VERSION ""

NS_ :

BS_:

BU_: AHLM ASBS CBC DIAGNOST DPDM DTCM ECM EHPS ESC ESL ESM ETM GPF HCP IC IRCM OCM ORC PTS RF_HUB SCCM SGW TBM TCM TPM

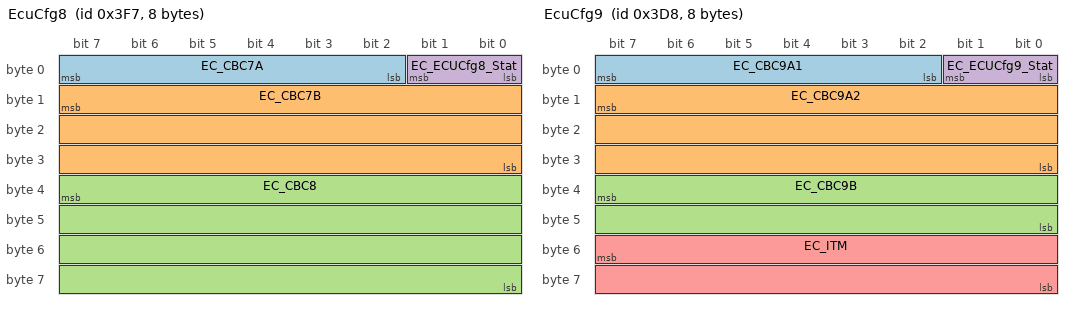
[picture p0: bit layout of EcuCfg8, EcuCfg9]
BO_ 1015 EcuCfg8: 8 CBC
 SG_ EC_CBC7A : 2|6@1+ (1,0) [0|0] ""  RF_HUB,SGW,TBM
 SG_ EC_CBC7B : 15|24@0+ (1,0) [0|0] ""  RF_HUB,SGW
 SG_ EC_CBC8 : 39|32@0+ (1,0) [0|0] ""  RF_HUB,SGW
 SG_ EC_ECUCfg8_Stat : 0|2@1+ (1,0) [0|0] ""  RF_HUB,SGW

BO_ 984 EcuCfg9: 8 CBC
 SG_ EC_CBC9A1 : 2|6@1+ (1,0) [0|0] ""  RF_HUB,SGW
 SG_ EC_CBC9A2 : 15|24@0+ (1,0) [0|0] ""  RF_HUB,SGW
 SG_ EC_CBC9B : 39|16@0+ (1,0) [0|0] ""  RF_HUB,SGW
 SG_ EC_ECUCfg9_Stat : 0|2@1+ (1,0) [0|0] ""  RF_HUB,SGW
 SG_ EC_ITM : 55|16@0+ (1,0) [0|0] ""  RF_HUB,SGW

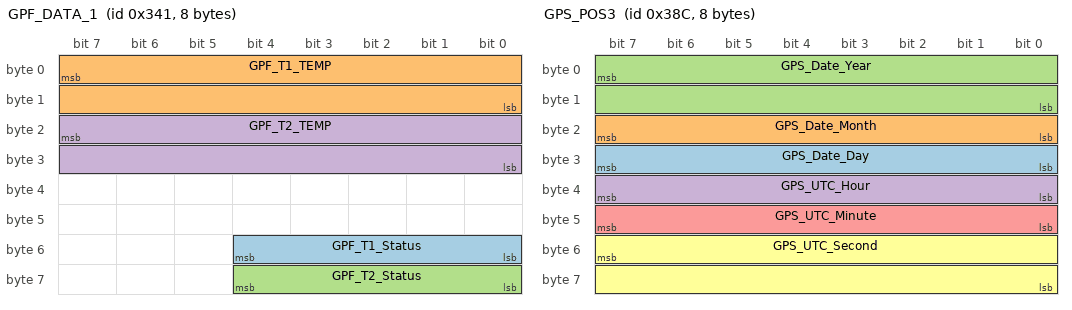
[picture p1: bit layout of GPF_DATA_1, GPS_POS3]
BO_ 833 GPF_DATA_1: 8 GPF
 SG_ GPF_T1_Status : 48|5@1+ (1,0) [0|0] ""  ECM,SGW
 SG_ GPF_T1_TEMP : 7|16@0+ (0.03125,-273) [-273|1774.97] "deg"  ECM,SGW
 SG_ GPF_T2_Status : 56|5@1+ (1,0) [0|0] ""  ECM,SGW
 SG_ GPF_T2_TEMP : 23|16@0+ (0.03125,-273) [-273|1774.97] "deg"  ECM,SGW

BO_ 908 GPS_POS3: 8 CBC
 SG_ GPS_Date_Day : 24|8@1+ (1,0) [1|31] "Days"  HCP,SGW
 SG_ GPS_Date_Month : 16|8@1+ (1,0) [1|12] "Months"  HCP,SGW
 SG_ GPS_Date_Year : 7|16@0+ (1,0) [0|65534] "Years"  HCP,SGW
 SG_ GPS_UTC_Hour : 32|8@1+ (1,0) [0|23] "h"  HCP,SGW
 SG_ GPS_UTC_Minute : 40|8@1+ (1,0) [0|59] "min"  HCP,SGW
 SG_ GPS_UTC_Second : 55|16@0+ (0.01,0) [0|59.99] "s"  HCP,SGW

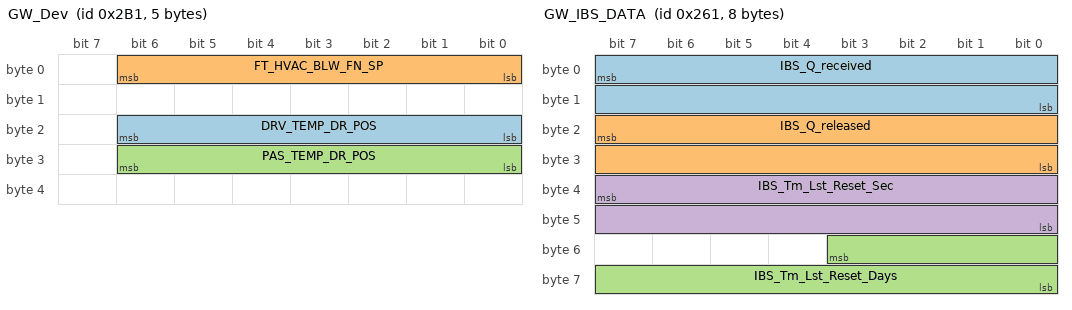
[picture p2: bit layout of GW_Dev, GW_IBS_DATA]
BO_ 689 GW_Dev: 5 CBC
 SG_ DRV_TEMP_DR_POS : 16|7@1+ (1,0) [0|100] "%"  ECM,HCP,SGW
 SG_ FT_HVAC_BLW_FN_SP : 0|7@1+ (1,0) [0|100] "Bars"  ECM,SGW
 SG_ PAS_TEMP_DR_POS : 24|7@1+ (1,0) [0|100] "%"  HCP,SGW

BO_ 609 GW_IBS_DATA: 8 CBC
 SG_ IBS_Q_received : 7|16@0+ (0.125,0) [0|8191.75] "Ah"  SGW
 SG_ IBS_Q_released : 23|16@0+ (0.125,0) [0|8191.75] "Ah"  SGW
 SG_ IBS_Tm_Lst_Reset_Days : 51|12@0+ (1,0) [0|4094] "Days"  SGW
 SG_ IBS_Tm_Lst_Reset_Sec : 39|16@0+ (2,0) [0|86398] "sec"  SGW

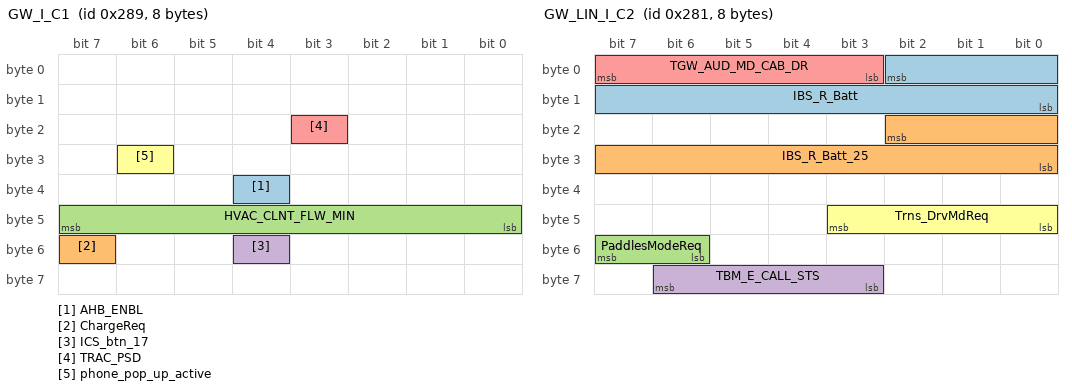
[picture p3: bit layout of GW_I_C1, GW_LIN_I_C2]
BO_ 649 GW_I_C1: 8 CBC
 SG_ AHB_ENBL : 36|1@1+ (1,0) [0|0] ""  IC,SGW
 SG_ ChargeReq : 55|1@1+ (1,0) [0|0] ""  HCP,IC,SGW
 SG_ HVAC_CLNT_FLW_MIN : 40|8@1+ (0.521555,0) [0.521555|131.953415] "LpM"  ECM,SGW
 SG_ ICS_btn_17 : 52|1@1+ (1,0) [0|0] ""  PTS,SGW
 SG_ TRAC_PSD : 19|1@1+ (1,0) [0|0] ""  ESC,ETM,SGW,TBM
 SG_ phone_pop_up_active : 30|1@1+ (1,0) [0|0] ""  IC,SGW

BO_ 650 GW_I_C2: 8 CBC
 SG_ ChargeNow : 60|1@1+ (1,0) [0|0] ""  HCP,SGW
 SG_ ChargeNow_TBM : 61|1@1+ (1,0) [0|0] ""  HCP,SGW

BO_ 663 GW_LIN_I_C1: 8 CBC
 SG_ SpSt_Pad1 : 50|3@1+ (1,0) [0|0] ""  ECM,HCP,SGW
 SG_ SpSt_Pad2 : 53|3@1+ (1,0) [0|0] ""  ECM,HCP,SGW

BO_ 641 GW_LIN_I_C2: 8 CBC
 SG_ IBS_R_Batt : 2|11@0+ (0.05,0) [0|20] "mOhm"  SGW
 SG_ IBS_R_Batt_25 : 18|11@0+ (0.05,0) [0|20] "mOhm"  SGW
 SG_ PaddlesModeReq : 54|2@1+ (1,0) [0|0] ""  SGW,TCM
 SG_ TBM_E_CALL_STS : 59|4@1+ (1,0) [0|0] ""  IC,SGW
 SG_ TGW_AUD_MD_CAB_DR : 3|5@1+ (1,0) [0|0] ""  IC,SGW
 SG_ Trns_DrvMdReq : 40|4@1+ (1,0) [0|0] ""  SGW,TCM

BO_ 651 GW_LIN_I_C3: 8 CBC
 SG_ HILL_DES_RQ_ICS : 49|2@1+ (1,0) [0|0] ""  ESC,SGW

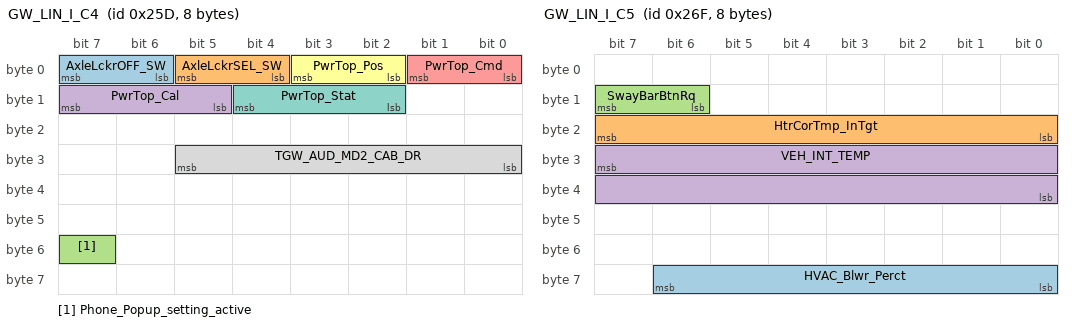
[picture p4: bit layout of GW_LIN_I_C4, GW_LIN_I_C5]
BO_ 605 GW_LIN_I_C4: 8 CBC
 SG_ AxleLckrOFF_SW : 6|2@1+ (1,0) [0|0] ""  DTCM,SGW
 SG_ AxleLckrSEL_SW : 4|2@1+ (1,0) [0|0] ""  DTCM,SGW
 SG_ Phone_Popup_setting_active : 55|1@1+ (1,0) [0|0] ""  IC,SGW
 SG_ PwrTop_Cal : 13|3@1+ (1,0) [0|0] ""  IC,SGW
 SG_ PwrTop_Cmd : 0|2@1+ (1,0) [0|0] ""  SGW
 SG_ PwrTop_Pos : 2|2@1+ (1,0) [0|0] ""  SGW
 SG_ PwrTop_Stat : 10|3@1+ (1,0) [0|0] ""  IC,SGW
 SG_ TGW_AUD_MD2_CAB_DR : 24|6@1+ (1,0) [0|0] ""  IC,SGW

BO_ 623 GW_LIN_I_C5: 8 CBC
 SG_ HVAC_Blwr_Perct : 56|7@1+ (1,0) [0|100] "%"  HCP,SGW
 SG_ HtrCorTmp_InTgt : 16|8@1+ (1,-40) [-40|214] "°C"  HCP,SGW
 SG_ SwayBarBtnRq : 14|2@1+ (1,0) [0|0] ""  ASBS,SGW
 SG_ VEH_INT_TEMP : 31|16@0+ (0.01,-40) [-40|85] "°C"  HCP,SGW

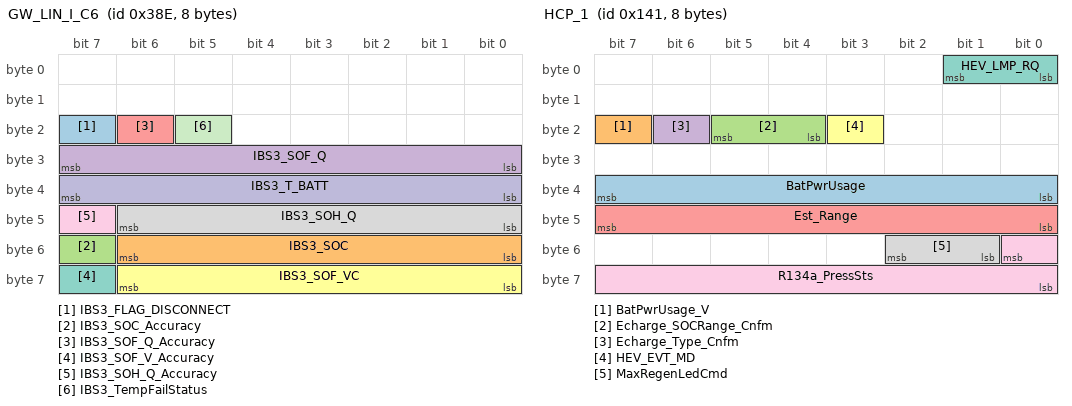
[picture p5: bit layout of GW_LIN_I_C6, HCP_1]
BO_ 910 GW_LIN_I_C6: 8 CBC
 SG_ IBS3_FLAG_DISCONNECT : 23|1@1+ (1,0) [0|0] ""  ECM,SGW
 SG_ IBS3_SOC : 48|7@1+ (1,0) [0|100] "%"  ECM,ETM,HCP,ORC,SGW,TBM
 SG_ IBS3_SOC_Accuracy : 55|1@1+ (1,0) [0|0] ""  ECM,ETM,HCP,SGW,TBM
 SG_ IBS3_SOF_Q : 24|8@1+ (1,0) [0|254] "Ah"  ECM,SGW
 SG_ IBS3_SOF_Q_Accuracy : 22|1@1+ (1,0) [0|0] ""  ECM,SGW
 SG_ IBS3_SOF_VC : 56|7@1+ (0.05,5) [5|11.3] "V"  ECM,SGW
 SG_ IBS3_SOF_V_Accuracy : 63|1@1+ (1,0) [0|0] ""  ECM,SGW
 SG_ IBS3_SOH_Q : 40|7@1+ (2,0) [0|252] "Ah"  ECM,SGW
 SG_ IBS3_SOH_Q_Accuracy : 47|1@1+ (1,0) [0|0] ""  ECM,SGW
 SG_ IBS3_T_BATT : 32|8@1+ (1,-40) [-40|105] "°C"  ECM,ETM,HCP,SGW,TBM
 SG_ IBS3_TempFailStatus : 21|1@1+ (1,0) [0|0] ""  ECM,HCP,SGW

BO_ 321 HCP_1: 8 HCP
 SG_ BatPwrUsage : 32|8@1+ (1,-125) [-125|130] "kW"  IC,SGW
 SG_ BatPwrUsage_V : 23|1@1+ (1,0) [0|0] ""  SGW
 SG_ Echarge_SOCRange_Cnfm : 20|2@1+ (1,0) [0|0] ""  CBC,SGW
 SG_ Echarge_Type_Cnfm : 22|1@1+ (1,0) [0|0] ""  CBC,SGW
 SG_ Est_Range : 40|8@1+ (1,0) [0|254] "km"  ETM,IC,SGW,TBM
 SG_ HEV_EVT_MD : 19|1@1+ (1,0) [0|0] ""  CBC,ETM,IC,IRCM,SGW,TBM
 SG_ HEV_LMP_RQ : 0|2@1+ (1,0) [0|0] ""  ETM,IC,ORC,SGW,TBM
 SG_ MaxRegenLedCmd : 49|2@1+ (1,0) [0|0] ""  CBC,SGW
 SG_ R134a_PressSts : 48|9@0+ (0.1,0) [0|40] "bar"  CBC,SGW

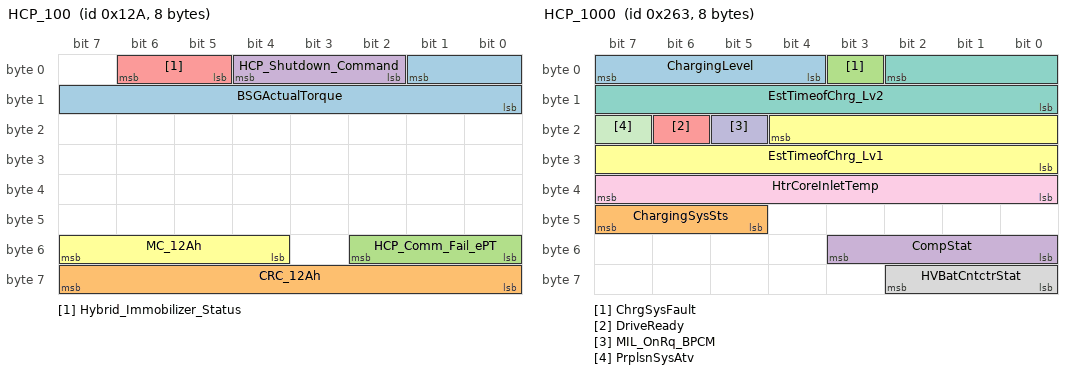
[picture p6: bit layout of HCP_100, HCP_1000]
BO_ 298 HCP_100: 8 HCP
 SG_ BSGActualTorque : 1|10@0+ (0.32,-163.52) [-163.52|163.52] "Nm"  ORC,SGW
 SG_ CRC_12Ah : 56|8@1+ (1,0) [0|0] ""  ECM,ESC,SGW,TCM
 SG_ HCP_Comm_Fail_ePT : 48|3@1+ (1,0) [0|0] ""  ECM,SGW,TCM
 SG_ HCP_Shutdown_Command : 2|3@1+ (1,0) [0|0] ""  CBC,SGW
 SG_ Hybrid_Immobilizer_Status : 5|2@1+ (1,0) [0|0] ""  CBC,ECM,SGW
 SG_ MC_12Ah : 52|4@1+ (1,0) [0|15] ""  ECM,ESC,SGW,TCM

BO_ 611 HCP_1000: 8 HCP
 SG_ ChargingLevel : 4|4@1+ (1,0) [0|0] ""  CBC,ETM,IC,SGW,TBM
 SG_ ChargingSysSts : 45|3@1+ (1,0) [0|0] ""  CBC,ETM,IC,SGW,TBM
 SG_ ChrgSysFault : 3|1@1+ (1,0) [0|0] ""  ETM,IC,SGW,TBM
 SG_ CompStat : 48|4@1+ (1,0) [0|0] ""  CBC,SGW
 SG_ DriveReady : 22|1@1+ (1,0) [0|0] ""  AHLM,CBC,ETM,IC,IRCM,SGW,TBM
 SG_ EstTimeofChrg_Lv1 : 20|13@0+ (1,0) [0|8190] "min"  CBC,ETM,IC,SGW,TBM
 SG_ EstTimeofChrg_Lv2 : 2|11@0+ (1,0) [0|2046] "min"  CBC,ETM,IC,SGW,TBM
 SG_ HVBatCntctrStat : 56|3@1+ (1,0) [0|0] ""  ETM,IC,ORC,SGW,TBM
 SG_ HtrCoreInletTemp : 32|8@1+ (1,-40) [-40|214] "°C"  CBC,ECM,SGW
 SG_ MIL_OnRq_BPCM : 21|1@1+ (1,0) [0|0] ""  IC,SGW
 SG_ PrplsnSysAtv : 23|1@1+ (1,0) [0|0] ""  CBC,ECM,EHPS,ESC,ETM,IC,RF_HUB,SGW,TBM

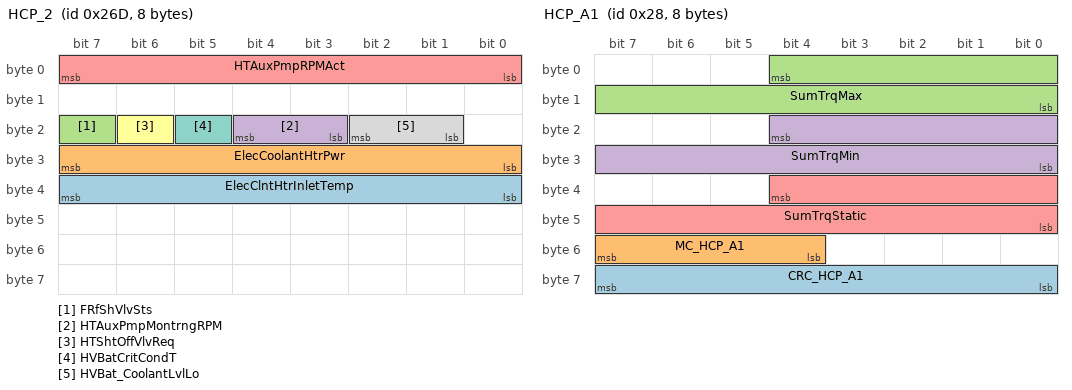
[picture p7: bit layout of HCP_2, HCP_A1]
BO_ 621 HCP_2: 8 HCP
 SG_ ElecClntHtrInletTemp : 32|8@1+ (1,-40) [-40|214] "°C"  ECM,SGW
 SG_ ElecCoolantHtrPwr : 24|8@1+ (0.04,0) [0|10.16] "kW"  CBC,ECM,SGW
 SG_ FRfShVlvSts : 23|1@1+ (1,0) [0|0] ""  CBC,SGW
 SG_ HTAuxPmpMontrngRPM : 19|2@1+ (1,0) [0|0] ""  ECM,SGW
 SG_ HTAuxPmpRPMAct : 0|8@1+ (24,0) [0|6096] "rpm"  CBC,ECM,SGW
 SG_ HTShtOffVlvReq : 22|1@1+ (1,0) [0|0] ""  CBC,ECM,SGW
 SG_ HVBatCritCondT : 21|1@1+ (1,0) [0|0] ""  CBC,SGW
 SG_ HVBat_CoolantLvlLo : 17|2@1+ (1,0) [0|0] ""  IC,SGW

BO_ 40 HCP_A1: 8 HCP
 SG_ CRC_HCP_A1 : 56|8@1+ (1,0) [0|0] ""  DTCM,ECM,ESC,IRCM,SGW,TCM
 SG_ MC_HCP_A1 : 52|4@1+ (1,0) [0|15] ""  DTCM,ECM,ESC,IRCM,SGW,TCM
 SG_ SumTrqMax : 4|13@0+ (0.25,-500) [-500|1547.5] "Nm"  DTCM,ECM,ESC,IRCM,SGW,TCM
 SG_ SumTrqMin : 20|13@0+ (0.25,-500) [-500|1547.5] "Nm"  DTCM,ECM,ESC,IRCM,SGW,TCM
 SG_ SumTrqStatic : 36|13@0+ (0.25,-500) [-500|1547.5] "Nm"  DTCM,ECM,ESC,IRCM,ORC,SGW,TCM

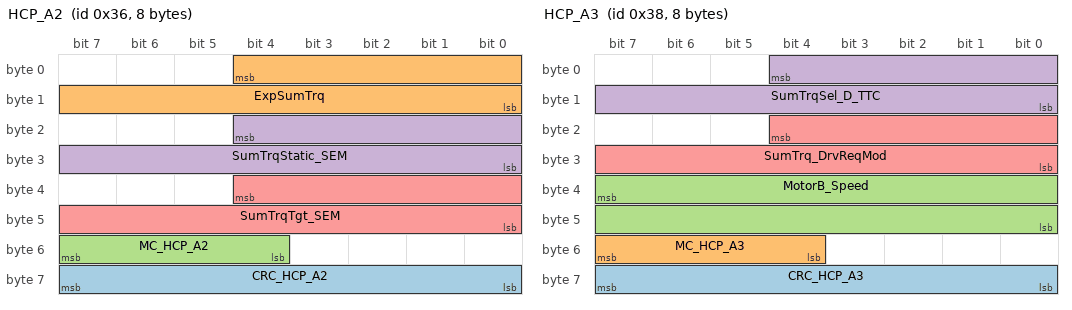
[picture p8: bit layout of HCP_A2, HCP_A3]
BO_ 54 HCP_A2: 8 HCP
 SG_ CRC_HCP_A2 : 56|8@1+ (1,0) [0|0] ""  DTCM,ESC,SGW,TCM
 SG_ ExpSumTrq : 4|13@0+ (0.25,-500) [-500|1547.5] "Nm"  DTCM,ESC,SGW
 SG_ MC_HCP_A2 : 52|4@1+ (1,0) [0|15] ""  DTCM,ESC,SGW,TCM
 SG_ SumTrqStatic_SEM : 20|13@0+ (0.25,-500) [-500|1547.5] "Nm"  SGW,TCM
 SG_ SumTrqTgt_SEM : 36|13@0+ (0.25,-500) [-500|1547.5] "Nm"  SGW,TCM

BO_ 56 HCP_A3: 8 HCP
 SG_ CRC_HCP_A3 : 56|8@1+ (1,0) [0|0] ""  DTCM,ECM,ESC,SGW,TCM
 SG_ MC_HCP_A3 : 52|4@1+ (1,0) [0|15] ""  DTCM,ECM,ESC,SGW,TCM
 SG_ MotorB_Speed : 39|16@0+ (1,-16382) [-16382|49151] "rpm"  DTCM,ECM,ESC,SGW,TCM
 SG_ SumTrqSel_D_TTC : 4|13@0+ (0.25,-500) [-500|1547.5] "Nm"  DTCM,ESC,IRCM,ORC,SGW,TCM
 SG_ SumTrq_DrvReqMod : 20|13@0+ (0.25,-500) [-500|1547.5] "Nm"  DTCM,ESC,IRCM,SGW,TCM

BO_ 315 HCP_C1: 8 HCP
 SG_ CRC_HCP_C1 : 56|8@1+ (1,0) [0|0] ""  ECM,IC,SGW,TCM
 SG_ DriveMdstat : 48|4@1+ (1,0) [0|0] ""  CBC,ECM,ETM,IC,SGW
 SG_ DrvMode_PopUpRqst : 25|4@1+ (1,0) [0|0] ""  IC,SGW
 SG_ GrShiftIndication : 1|2@1+ (1,0) [0|0] ""  IC,SGW
 SG_ HCPCoachDisp : 40|8@1+ (1,-100) [-100|100] "%"  IC,SGW
 SG_ HCPCoachDispV : 30|1@1+ (1,0) [0|0] ""  IC,SGW
 SG_ HCPOutputPwr : 32|8@1+ (1,-100) [-100|100] "%"  IC,SGW
 SG_ HCPOutputPwrV : 29|1@1+ (1,0) [0|0] ""  IC,SGW
 SG_ HCPPopUpMessage1 : 8|1@1+ (1,0) [0|0] ""  IC,SGW
 SG_ HCPPopUpMessage10 : 24|1@1+ (1,0) [0|0] ""  IC,SGW
 SG_ HCPPopUpMessage12 : 3|2@1+ (1,0) [0|0] ""  IC,SGW
 SG_ HCPPopUpMessage2 : 9|1@1+ (1,0) [0|0] ""  IC,SGW
 SG_ HCPPopUpMessage3 : 10|1@1+ (1,0) [0|0] ""  IC,SGW
 SG_ HCPPopUpMessage4 : 11|1@1+ (1,0) [0|0] ""  IC,SGW
 SG_ HCPPopUpMessage5 : 12|1@1+ (1,0) [0|0] ""  IC,SGW
 SG_ HCPPopUpMessage6 : 13|1@1+ (1,0) [0|0] ""  IC,SGW
 SG_ HCPPopUpMessage7 : 14|1@1+ (1,0) [0|0] ""  IC,SGW
 SG_ HCPPopUpMessage8 : 15|1@1+ (1,0) [0|0] ""  IC,SGW
 SG_ HCPPopUpMessage9 : 0|1@1+ (1,0) [0|0] ""  IC,SGW
 SG_ HybSysEmsMlfAtv : 7|1@1+ (1,0) [0|0] ""  SGW
 SG_ MC_HCP_C1 : 52|4@1+ (1,0) [0|15] ""  ECM,IC,SGW,TCM
 SG_ MIL_OnRq_HCP : 6|1@1+ (1,0) [0|0] ""  ECM,ETM,SGW,TBM
 SG_ MaxRegenTelltale : 16|2@1+ (1,0) [0|0] ""  IC,SGW
 SG_ P1fFailedUseBumpStartHMI : 31|1@1+ (1,0) [0|0] ""  IC,SGW

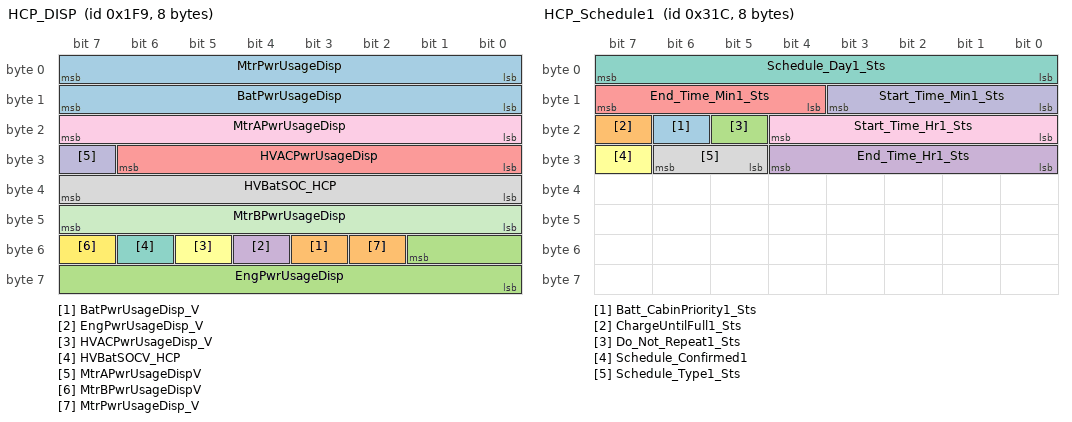
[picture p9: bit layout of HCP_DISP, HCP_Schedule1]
BO_ 505 HCP_DISP: 8 HCP
 SG_ BatPwrUsageDisp : 8|8@1+ (1,-125) [-125|130] "kW"  CBC,ETM,SGW,TBM
 SG_ BatPwrUsageDisp_V : 51|1@1+ (1,0) [0|0] ""  CBC,ETM,SGW
 SG_ EngPwrUsageDisp : 49|10@0+ (1,0) [0|1023] "kW"  CBC,ETM,IC,SGW
 SG_ EngPwrUsageDisp_V : 52|1@1+ (1,0) [0|0] ""  CBC,ETM,IC,SGW
 SG_ HVACPwrUsageDisp : 24|7@1+ (1,0) [0|127] "kW"  CBC,ETM,SGW
 SG_ HVACPwrUsageDisp_V : 53|1@1+ (1,0) [0|0] ""  CBC,ETM,SGW
 SG_ HVBatSOCV_HCP : 54|1@1+ (1,0) [0|0] ""  CBC,ETM,IC,SGW,TBM
 SG_ HVBatSOC_HCP : 32|8@1+ (0.3922,0) [0|100] "%"  CBC,ETM,IC,SGW,TBM
 SG_ MtrAPwrUsageDisp : 16|8@1+ (1,-125) [-125|130] "kW"  CBC,ETM,SGW
 SG_ MtrAPwrUsageDispV : 31|1@1+ (1,0) [0|0] ""  CBC,ETM,SGW
 SG_ MtrBPwrUsageDisp : 40|8@1+ (1,-125) [-125|130] "kW"  CBC,ETM,SGW
 SG_ MtrBPwrUsageDispV : 55|1@1+ (1,0) [0|0] ""  CBC,ETM,SGW
 SG_ MtrPwrUsageDisp : 0|8@1+ (1,-125) [-125|130] "kW"  IC,SGW
 SG_ MtrPwrUsageDisp_V : 50|1@1+ (1,0) [0|0] ""  IC,SGW

BO_ 796 HCP_Schedule1: 8 HCP
 SG_ Batt_CabinPriority1_Sts : 22|1@1+ (1,0) [0|0] ""  CBC,SGW
 SG_ ChargeUntilFull1_Sts : 23|1@1+ (1,0) [0|0] ""  CBC,SGW
 SG_ Do_Not_Repeat1_Sts : 21|1@1+ (1,0) [0|0] ""  CBC,SGW
 SG_ End_Time_Hr1_Sts : 24|5@1+ (1,0) [0|23] "Hours"  CBC,SGW
 SG_ End_Time_Min1_Sts : 12|4@1+ (5,0) [0|55] "min"  CBC,SGW
 SG_ Schedule_Confirmed1 : 31|1@1+ (1,0) [0|0] ""  CBC,SGW
 SG_ Schedule_Day1_Sts : 0|8@1+ (1,0) [0|0] ""  CBC,SGW
 SG_ Schedule_Type1_Sts : 29|2@1+ (1,0) [0|0] ""  CBC,SGW
 SG_ Start_Time_Hr1_Sts : 16|5@1+ (1,0) [0|23] "Hours"  CBC,SGW
 SG_ Start_Time_Min1_Sts : 8|4@1+ (5,0) [0|55] "min"  CBC,SGW

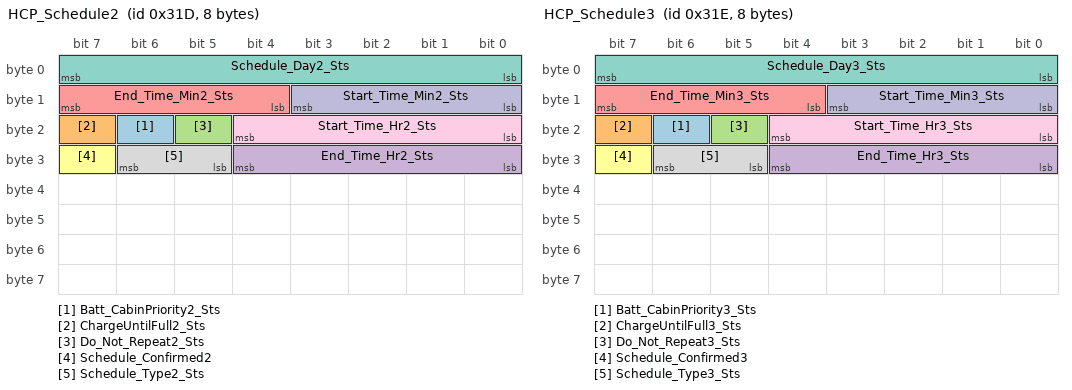
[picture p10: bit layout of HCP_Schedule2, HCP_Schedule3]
BO_ 797 HCP_Schedule2: 8 HCP
 SG_ Batt_CabinPriority2_Sts : 22|1@1+ (1,0) [0|0] ""  CBC,SGW
 SG_ ChargeUntilFull2_Sts : 23|1@1+ (1,0) [0|0] ""  CBC,SGW
 SG_ Do_Not_Repeat2_Sts : 21|1@1+ (1,0) [0|0] ""  CBC,SGW
 SG_ End_Time_Hr2_Sts : 24|5@1+ (1,0) [0|23] "Hours"  CBC,SGW
 SG_ End_Time_Min2_Sts : 12|4@1+ (5,0) [0|55] "min"  CBC,SGW
 SG_ Schedule_Confirmed2 : 31|1@1+ (1,0) [0|0] ""  CBC,SGW
 SG_ Schedule_Day2_Sts : 0|8@1+ (1,0) [0|0] ""  CBC,SGW
 SG_ Schedule_Type2_Sts : 29|2@1+ (1,0) [0|0] ""  CBC,SGW
 SG_ Start_Time_Hr2_Sts : 16|5@1+ (1,0) [0|23] "Hours"  CBC,SGW
 SG_ Start_Time_Min2_Sts : 8|4@1+ (5,0) [0|55] "min"  CBC,SGW

BO_ 798 HCP_Schedule3: 8 HCP
 SG_ Batt_CabinPriority3_Sts : 22|1@1+ (1,0) [0|0] ""  CBC,SGW
 SG_ ChargeUntilFull3_Sts : 23|1@1+ (1,0) [0|0] ""  CBC,SGW
 SG_ Do_Not_Repeat3_Sts : 21|1@1+ (1,0) [0|0] ""  CBC,SGW
 SG_ End_Time_Hr3_Sts : 24|5@1+ (1,0) [0|23] "Hours"  CBC,SGW
 SG_ End_Time_Min3_Sts : 12|4@1+ (5,0) [0|55] "min"  CBC,SGW
 SG_ Schedule_Confirmed3 : 31|1@1+ (1,0) [0|0] ""  CBC,SGW
 SG_ Schedule_Day3_Sts : 0|8@1+ (1,0) [0|0] ""  CBC,SGW
 SG_ Schedule_Type3_Sts : 29|2@1+ (1,0) [0|0] ""  CBC,SGW
 SG_ Start_Time_Hr3_Sts : 16|5@1+ (1,0) [0|23] "Hours"  CBC,SGW
 SG_ Start_Time_Min3_Sts : 8|4@1+ (5,0) [0|55] "min"  CBC,SGW

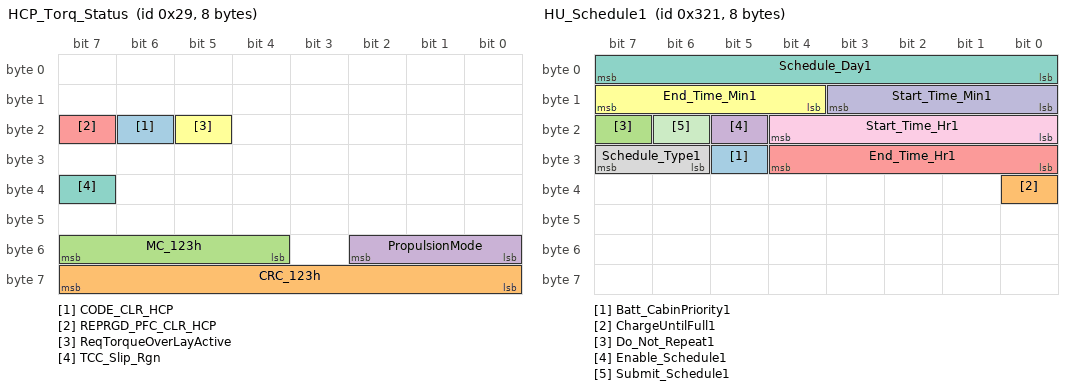
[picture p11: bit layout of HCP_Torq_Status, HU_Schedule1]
BO_ 41 HCP_Torq_Status: 8 HCP
 SG_ CODE_CLR_HCP : 22|1@1+ (1,0) [0|0] ""  ECM,SGW
 SG_ CRC_123h : 56|8@1+ (1,0) [0|255] ""  ECM,SGW,TCM
 SG_ MC_123h : 52|4@1+ (1,0) [0|15] ""  ECM,SGW,TCM
 SG_ PropulsionMode : 48|3@1+ (1,0) [0|0] ""  ECM,SGW
 SG_ REPRGD_PFC_CLR_HCP : 23|1@1+ (1,0) [0|0] ""  ECM,SGW
 SG_ ReqTorqueOverLayActive : 21|1@1+ (1,0) [0|0] ""  ORC,SGW,TCM
 SG_ TCC_Slip_Rgn : 39|1@1+ (1,0) [0|0] ""  SGW,TCM

BO_ 801 HU_Schedule1: 8 CBC
 SG_ Batt_CabinPriority1 : 29|1@1+ (1,0) [0|0] ""  HCP,SGW
 SG_ ChargeUntilFull1 : 32|1@1+ (1,0) [0|0] ""  HCP,SGW
 SG_ Do_Not_Repeat1 : 23|1@1+ (1,0) [0|0] ""  HCP,SGW
 SG_ Enable_Schedule1 : 21|1@1+ (1,0) [0|0] ""  HCP,SGW
 SG_ End_Time_Hr1 : 24|5@1+ (5,0) [0|23] "Hours"  HCP,SGW
 SG_ End_Time_Min1 : 12|4@1+ (1,0) [0|55] "min"  HCP,SGW
 SG_ Schedule_Day1 : 0|8@1+ (1,0) [0|0] ""  HCP,SGW
 SG_ Schedule_Type1 : 30|2@1+ (1,0) [0|0] ""  HCP,SGW
 SG_ Start_Time_Hr1 : 16|5@1+ (1,0) [0|23] "Hours"  HCP,SGW
 SG_ Start_Time_Min1 : 8|4@1+ (5,0) [0|55] "min"  HCP,SGW
 SG_ Submit_Schedule1 : 22|1@1+ (1,0) [0|0] ""  HCP,SGW

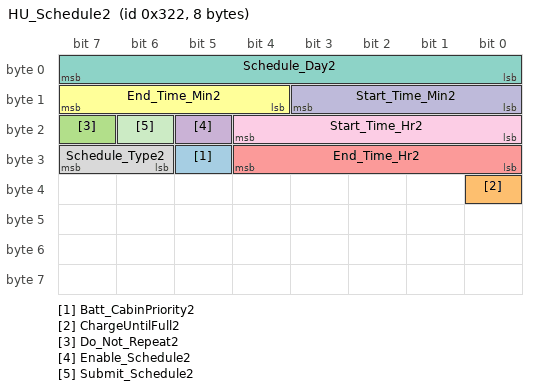
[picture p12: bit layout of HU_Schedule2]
BO_ 802 HU_Schedule2: 8 CBC
 SG_ Batt_CabinPriority2 : 29|1@1+ (1,0) [0|0] ""  HCP,SGW
 SG_ ChargeUntilFull2 : 32|1@1+ (1,0) [0|0] ""  HCP,SGW
 SG_ Do_Not_Repeat2 : 23|1@1+ (1,0) [0|0] ""  HCP,SGW
 SG_ Enable_Schedule2 : 21|1@1+ (1,0) [0|0] ""  HCP,SGW
 SG_ End_Time_Hr2 : 24|5@1+ (1,0) [0|23] "Hours"  HCP,SGW
 SG_ End_Time_Min2 : 12|4@1+ (5,0) [0|55] "min"  HCP,SGW
 SG_ Schedule_Day2 : 0|8@1+ (1,0) [0|0] ""  HCP,SGW
 SG_ Schedule_Type2 : 30|2@1+ (1,0) [0|0] ""  HCP,SGW
 SG_ Start_Time_Hr2 : 16|5@1+ (1,0) [0|23] "Hours"  HCP,SGW
 SG_ Start_Time_Min2 : 8|4@1+ (5,0) [0|55] "min"  HCP,SGW
 SG_ Submit_Schedule2 : 22|1@1+ (1,0) [0|0] ""  HCP,SGW

CM_ SG_ 1015 EC_CBC7A "CBC ecu configuration 7A";
CM_ SG_ 1015 EC_CBC7B "CBC ecu configuration 7B";
CM_ SG_ 1015 EC_CBC8 "CBC ecu configuration 8";
CM_ SG_ 1015 EC_ECUCfg8_Stat "ECU Configuration messages status 8";
CM_ SG_ 984 EC_CBC9A1 "CBC configuration 9A1";
CM_ SG_ 984 EC_CBC9A2 "CBC configuration 9A2";
CM_ SG_ 984 EC_CBC9B "CBC configuration 9B";
CM_ SG_ 984 EC_ECUCfg9_Stat "ECU Configuration messages status 9";
CM_ SG_ 984 EC_ITM "ITM ecu configuration";
CM_ SG_ 833 GPF_T1_Status "PRE GPF Temperature Sensor Status";
CM_ SG_ 833 GPF_T1_TEMP "PRE GPF Temperature Sensor";
CM_ SG_ 833 GPF_T2_Status "POST GPF Temperature Sensor Status";
CM_ SG_ 833 GPF_T2_TEMP "POST GPF Temperature Sensor";
CM_ SG_ 908 GPS_Date_Day "GPS date day";
CM_ SG_ 908 GPS_Date_Month "GPS date month";
CM_ SG_ 908 GPS_Date_Year "GPS date year";
CM_ SG_ 908 GPS_UTC_Hour "GPS UTC hour";
CM_ SG_ 908 GPS_UTC_Minute "GPS UTC minute";
CM_ SG_ 908 GPS_UTC_Second "GPS UTC second";
CM_ SG_ 689 DRV_TEMP_DR_POS "Driver temperature door postion";
CM_ SG_ 689 FT_HVAC_BLW_FN_SP "Front HVAC blower fan speed status in 'bars'";
CM_ SG_ 689 PAS_TEMP_DR_POS "Passenger temperature door postion";
CM_ SG_ 609 IBS_Q_received "LifeTime charge received";
CM_ SG_ 609 IBS_Q_released "Lifetime charge released";
CM_ SG_ 609 IBS_Tm_Lst_Reset_Days "Accumulated time since last reset in days";
CM_ SG_ 609 IBS_Tm_Lst_Reset_Sec "Accumulated time since last reset in seconds";
CM_ SG_ 649 AHB_ENBL "Auto highbeam enable";
CM_ SG_ 649 ChargeReq "Request for scheduled charge; Charge now = [1]";
CM_ SG_ 649 HVAC_CLNT_FLW_MIN "HVAC coolant flow minimum request";
CM_ SG_ 649 ICS_btn_17 "PTS Off pressed";
CM_ SG_ 649 TRAC_PSD "Traction on/off button pressed; [0] = Not Pressed, [1] = Pressed";
CM_ SG_ 649 phone_pop_up_active "Phone pop up is active; True = [1]";
CM_ SG_ 650 ChargeNow "Charge Now Signal";
CM_ SG_ 650 ChargeNow_TBM "Charge Now Signal TBM";
CM_ SG_ 663 SpSt_Pad1 "Stop / start switch - pad 1";
CM_ SG_ 663 SpSt_Pad2 "Stop / start switch - pad 2";
CM_ SG_ 641 IBS_R_Batt "Calculated battery resistance";
CM_ SG_ 641 IBS_R_Batt_25 "Batt resistance at 100% SOC and 25 degC";
CM_ SG_ 641 PaddlesModeReq "Requested state of paddle lock-out function";
CM_ SG_ 641 TBM_E_CALL_STS "E call status messages";
CM_ SG_ 641 TGW_AUD_MD_CAB_DR "TGW audio mode for Cabin/Driver";
CM_ SG_ 641 Trns_DrvMdReq "The requested state of the drive mode feature";
CM_ SG_ 651 HILL_DES_RQ_ICS "Hill descent or select speed status";
CM_ SG_ 605 AxleLckrOFF_SW "Axle locker deactivation switch";
CM_ SG_ 605 AxleLckrSEL_SW "Axle locker selection switch";
CM_ SG_ 605 Phone_Popup_setting_active "Phone call status popup active or not, Active=1";
CM_ SG_ 605 PwrTop_Cal "Power Top Calibration Status";
CM_ SG_ 605 PwrTop_Cmd "Power Top Switch Status";
CM_ SG_ 605 PwrTop_Pos "Power Top Roof Position";
CM_ SG_ 605 PwrTop_Stat "Power Top Operation Status";
CM_ SG_ 605 TGW_AUD_MD2_CAB_DR "TGW additional audio modes for Cabin/Driver";
CM_ SG_ 623 HVAC_Blwr_Perct "HVAC blower PWM percentage for service mode";
CM_ SG_ 623 HtrCorTmp_InTgt "Heater core temp target";
CM_ SG_ 623 SwayBarBtnRq "Sway bar disconnect switch request";
CM_ SG_ 623 VEH_INT_TEMP "Vehicle interior temperature";
CM_ SG_ 910 IBS3_FLAG_DISCONNECT "Battery disconnection flag";
CM_ SG_ 910 IBS3_SOC "State of charge";
CM_ SG_ 910 IBS3_SOC_Accuracy "SOC accuracy status";
CM_ SG_ 910 IBS3_SOF_Q "Residual battery charge in Ah";
CM_ SG_ 910 IBS3_SOF_Q_Accuracy "SOF_Q accuracy status";
CM_ SG_ 910 IBS3_SOF_VC "Predicted initial battery voltage dip during cranking (old CG spec)";
CM_ SG_ 910 IBS3_SOF_V_Accuracy "SOF_V accuracy; Data reliable = [0], unreliable = [1]";
CM_ SG_ 910 IBS3_SOH_Q "State of health related to capacity (energy)";
CM_ SG_ 910 IBS3_SOH_Q_Accuracy "SOH_Q accuracy status";
CM_ SG_ 910 IBS3_T_BATT "Battery temperature";
CM_ SG_ 910 IBS3_TempFailStatus "Failure of ASIC Temperature meas. (internal defect)";
CM_ SG_ 321 BatPwrUsage ".";
CM_ SG_ 321 BatPwrUsage_V ".";
CM_ SG_ 321 Echarge_SOCRange_Cnfm "Echarge selected SOC confirmation status";
CM_ SG_ 321 Echarge_Type_Cnfm "Echarge type confirmation status";
CM_ SG_ 321 Est_Range "Estimated electric range sent to HMI";
CM_ SG_ 321 HEV_EVT_MD "The system is in EVT mode; Hybrid mode = [0], EV Mode = [1]";
CM_ SG_ 321 HEV_LMP_RQ "HEV service lamp request";
CM_ SG_ 321 MaxRegenLedCmd "Max Regen switch status";
CM_ SG_ 321 R134a_PressSts "Refrigerant pressure (R134a or R1234YF)";
CM_ SG_ 298 BSGActualTorque "BSG Actual Torque";
CM_ SG_ 298 CRC_12Ah "CRC-checksum byte 1 to 7 according to SAE J1850";
CM_ SG_ 298 HCP_Comm_Fail_ePT "HCP_Comm_Fail_ePT";
CM_ SG_ 298 HCP_Shutdown_Command "System shutdown command from HCP";
CM_ SG_ 298 Hybrid_Immobilizer_Status "System shutdown command from HCP";
CM_ SG_ 298 MC_12Ah "Message counter";
CM_ SG_ 611 ChargingLevel "Charging level and type.";
CM_ SG_ 611 ChargingSysSts "Charging System status";
CM_ SG_ 611 ChrgSysFault "Charging System Fault status";
CM_ SG_ 611 CompStat "comppressor state";
CM_ SG_ 611 DriveReady "Ready to Drive, [1] = Vehicle is allowed to shift out of park or neutral";
CM_ SG_ 611 EstTimeofChrg_Lv1 "Estimated Time to charge on Level 1";
CM_ SG_ 611 EstTimeofChrg_Lv2 "Estimated Time to charge on Level 2";
CM_ SG_ 611 HVBatCntctrStat "HV Battery pack contactor state";
CM_ SG_ 611 HtrCoreInletTemp "Heater Core Inlet Temp";
CM_ SG_ 611 MIL_OnRq_BPCM "MIL Lamp request from BPCM.";
CM_ SG_ 611 PrplsnSysAtv "Propulsion system active, [1] = active";
CM_ SG_ 621 ElecClntHtrInletTemp "Electric Coolant Heater Inlet Temperature";
CM_ SG_ 621 ElecCoolantHtrPwr "Electric Coolant Heater Power";
CM_ SG_ 621 FRfShVlvSts "Front Refrigerant Shutoff Valve Status";
CM_ SG_ 621 HTAuxPmpMontrngRPM "High Temp Aux Pump RPM monitoring active";
CM_ SG_ 621 HTAuxPmpRPMAct "High Temp Aux Pump Status";
CM_ SG_ 621 HTShtOffVlvReq "High temp shut off valve request; [0] = Open, [1] = Closed";
CM_ SG_ 621 HVBatCritCondT "High Voltage Battery Temperature Critical Condition, [1] = True";
CM_ SG_ 621 HVBat_CoolantLvlLo "Battery coolant level low";
CM_ SG_ 40 CRC_HCP_A1 "CRC-checksum byte 1 to 7 according to SAE J1850";
CM_ SG_ 40 MC_HCP_A1 "Message counter";
CM_ SG_ 40 SumTrqMax "Maximum Sum Torque";
CM_ SG_ 40 SumTrqMin "Minimum Sum Torque";
CM_ SG_ 40 SumTrqStatic "Static Sum Torque / Effective Sum Torque";
CM_ SG_ 54 CRC_HCP_A2 "CRC-checksum byte 1 to 7 according to SAE J1850";
CM_ SG_ 54 ExpSumTrq "Expected Sum Torque based on target  transmission input speed";
CM_ SG_ 54 MC_HCP_A2 "Message counter";
CM_ SG_ 54 SumTrqStatic_SEM "Static Sum Torque - Transmission Torque Request";
CM_ SG_ 54 SumTrqTgt_SEM "Target Torque  - Transmission Torque Request";
CM_ SG_ 56 CRC_HCP_A3 "CRC-checksum byte 1 to 6 according to SAE J1850";
CM_ SG_ 56 MC_HCP_A3 "Message counter";
CM_ SG_ 56 MotorB_Speed "Electric Motor Revolutions Per Minute, Initialization = 0xFFFE";
CM_ SG_ 56 SumTrqSel_D_TTC "Corrected (substitute) driver torque demand";
CM_ SG_ 56 SumTrq_DrvReqMod "Driver requested sum torque modifed";
CM_ SG_ 315 CRC_HCP_C1 "CRC-checksum byte 1 to 7 according to SAE J1850";
CM_ SG_ 315 DriveMdstat "Drive mode select switch status";
CM_ SG_ 315 DrvMode_PopUpRqst "Drive modes HMI pop-up message request";
CM_ SG_ 315 GrShiftIndication "Gear Shift Indication to Driver";
CM_ SG_ 315 HCPCoachDisp "Percentage output acceleration & deceleration to support Efficiency Coaching HMI";
CM_ SG_ 315 HCPCoachDispV "Acceleration & deceleration to support Efficiency Coaching validtiy, 0 = Valid, 1 = Invalid";
CM_ SG_ 315 HCPOutputPwr "Percentage output power from HCP for HMI";
CM_ SG_ 315 HCPOutputPwrV "Percentage output power from HCP for HMI validity, 0 = Valid, 1 = Invalid";
CM_ SG_ 315 HCPPopUpMessage1 "Vehicle speed may be limited; True = [1]";
CM_ SG_ 315 HCPPopUpMessage10 "High Voltage Functionalities rejected due to Hood Open; True = [1]";
CM_ SG_ 315 HCPPopUpMessage12 "Display for Max Regen feature";
CM_ SG_ 315 HCPPopUpMessage2 "Plug in vehicle to keep battery warm; True = [1]";
CM_ SG_ 315 HCPPopUpMessage3 "Remote start canceled - hv battery temperature; True = [1]";
CM_ SG_ 315 HCPPopUpMessage4 "Turn on vehicle to use climate controls; True = [1]";
CM_ SG_ 315 HCPPopUpMessage5 "Please check plug status before driving; True = [1]";
CM_ SG_ 315 HCPPopUpMessage6 "There may be a problem with the charging unit; True = [1]";
CM_ SG_ 315 HCPPopUpMessage7 "Please leave key in run - battery conditioning needed; True = [1]";
CM_ SG_ 315 HCPPopUpMessage8 "Plugged in. Lock vehicle to start charging or resume scheduled charging; True = [1]";
CM_ SG_ 315 HCPPopUpMessage9 "Stop safely. Vehicle will shut off soon; True = [1]";
CM_ SG_ 315 HybSysEmsMlfAtv "Emissions Related Malfunction Active";
CM_ SG_ 315 MC_HCP_C1 "Message counter";
CM_ SG_ 315 MIL_OnRq_HCP "MIL on request from the HCP";
CM_ SG_ 315 MaxRegenTelltale "Max Regen telltale";
CM_ SG_ 315 P1fFailedUseBumpStartHMI "P1f failed, use P2 to bump start the engine; True = [1]";
CM_ SG_ 505 BatPwrUsageDisp "Battery power usage for HMI, in KW";
CM_ SG_ 505 BatPwrUsageDisp_V "Validity bit for signal BatPwrUsageDisp, 0=Valid";
CM_ SG_ 505 EngPwrUsageDisp "Engine power usage for HMI, in KW";
CM_ SG_ 505 EngPwrUsageDisp_V "Validity bit for signal EngPwrUsageDisp, 0=Valid";
CM_ SG_ 505 HVACPwrUsageDisp "HVAC power usage for HMI, in KW";
CM_ SG_ 505 HVACPwrUsageDisp_V "Validity bit for signal HVACPwrUsageDisp, 0=Valid";
CM_ SG_ 505 HVBatSOCV_HCP "High voltage battery state of charge validity: invalid = [1]";
CM_ SG_ 505 HVBatSOC_HCP "High voltage battery state of charge";
CM_ SG_ 505 MtrAPwrUsageDisp "Motor A power usage for HMI, in KW";
CM_ SG_ 505 MtrAPwrUsageDispV "Validity bit for signal MtrAPwrUsageDisp, 0=Valid";
CM_ SG_ 505 MtrBPwrUsageDisp "Motor B power usage for HMI, in KW";
CM_ SG_ 505 MtrBPwrUsageDispV "Validity bit for signal MtrBPwrUsageDisp, 0=Valid";
CM_ SG_ 505 MtrPwrUsageDisp "Motor power usage for HMI, in KW";
CM_ SG_ 505 MtrPwrUsageDisp_V "Validity bit for signal MtrPwrUsageDisp, 0=Valid";
CM_ SG_ 796 Batt_CabinPriority1_Sts "Bit to prioritize cabin conditioning under schedule 1";
CM_ SG_ 796 ChargeUntilFull1_Sts "Charge until battery is fully charged with schedule 1";
CM_ SG_ 796 Do_Not_Repeat1_Sts "Do not repeat the set Schedule";
CM_ SG_ 796 End_Time_Hr1_Sts "End Time of schedule 1 (hours in 24 hrs. format)";
CM_ SG_ 796 End_Time_Min1_Sts "End Time of schedule 1 (Minutes)";
CM_ SG_ 796 Schedule_Confirmed1 "Confirm the requested schedule 1";
CM_ SG_ 796 Schedule_Day1_Sts "Schedule#1 Day for charging or cabin conditioning";
CM_ SG_ 796 Schedule_Type1_Sts "Type of charging and climate schedule";
CM_ SG_ 796 Start_Time_Hr1_Sts "Start Time of schedule 1 (hours in 24 hrs. format)";
CM_ SG_ 796 Start_Time_Min1_Sts "Start Time of schedule 1 (minutes)";
CM_ SG_ 797 Batt_CabinPriority2_Sts "Bit to prioritize cabin conditioning under schedule 2";
CM_ SG_ 797 ChargeUntilFull2_Sts "Charge until battery is fully charged with schedule 2";
CM_ SG_ 797 Do_Not_Repeat2_Sts "Do not repeat the set Schedule";
CM_ SG_ 797 End_Time_Hr2_Sts "End Time of schedule 2 (hours in 24 hrs. format)";
CM_ SG_ 797 End_Time_Min2_Sts "End Time of schedule 2 (Minutes)";
CM_ SG_ 797 Schedule_Confirmed2 "Confirm the requested schedule 2";
CM_ SG_ 797 Schedule_Day2_Sts "Schedule#2 Day for charging or cabin conditioning";
CM_ SG_ 797 Schedule_Type2_Sts "Type of charging and climate schedule";
CM_ SG_ 797 Start_Time_Hr2_Sts "Start Time of schedule 2 (hours in 24 hrs. format)";
CM_ SG_ 797 Start_Time_Min2_Sts "Start Time of schedule 2 (minutes)";
CM_ SG_ 798 Batt_CabinPriority3_Sts "Bit to prioritize cabin conditioning under schedule 3";
CM_ SG_ 798 ChargeUntilFull3_Sts "Charge until battery is fully charged with schedule 3";
CM_ SG_ 798 Do_Not_Repeat3_Sts "Do not repeat the set Schedule";
CM_ SG_ 798 End_Time_Hr3_Sts "End Time of schedule 3 (hours in 24 hrs. format)";
CM_ SG_ 798 End_Time_Min3_Sts "End Time of schedule 3 (Minutes)";
CM_ SG_ 798 Schedule_Confirmed3 "Confirm the requested schedule 3";
CM_ SG_ 798 Schedule_Day3_Sts "Schedule#3 Day for charging or cabin conditioning";
CM_ SG_ 798 Schedule_Type3_Sts "Type of charging and climate schedule";
CM_ SG_ 798 Start_Time_Hr3_Sts "Start Time of schedule 3 (hours in 24 hrs. format)";
CM_ SG_ 798 Start_Time_Min3_Sts "Start Time of schedule 3 (minutes)";
CM_ SG_ 41 CODE_CLR_HCP "Clear emission related faults; 0= not clear 1= Clear";
CM_ SG_ 41 CRC_123h "CRC-checksum byte 1 to 7 according to SAE J1850";
CM_ SG_ 41 MC_123h "Message counter";
CM_ SG_ 41 PropulsionMode "Propulsion mode of the vehicle";
CM_ SG_ 41 REPRGD_PFC_CLR_HCP "Set readiness to 'incomplete'; 0 = Do nothing; 1= Set incomplete";
CM_ SG_ 41 ReqTorqueOverLayActive "Regeneration Shift Schedule Request (1 = Active)";
CM_ SG_ 41 TCC_Slip_Rgn "TCC slip during transition regen; Active = [1]";
CM_ SG_ 801 Batt_CabinPriority1 "Bit to prioritize battery charging or cabin conditioning under schedule 1";
CM_ SG_ 801 ChargeUntilFull1 "Charge until battery is fully charged with schedule 1";
CM_ SG_ 801 Do_Not_Repeat1 "Do not repeat the set Schedule";
CM_ SG_ 801 Enable_Schedule1 "Schedule 1 checkbox enabled";
CM_ SG_ 801 End_Time_Hr1 "End Time of schedule 1 (hours in 24 hrs. format)";
CM_ SG_ 801 End_Time_Min1 "End Time of schedule 1 (Minutes)";
CM_ SG_ 801 Schedule_Day1 "Schedule#1 Day for charging or cabin conditioning";
CM_ SG_ 801 Schedule_Type1 "Type of charging and climate schedule";
CM_ SG_ 801 Start_Time_Hr1 "Start Time of schedule 1 (hours in 24 hrs. format)";
CM_ SG_ 801 Start_Time_Min1 "Start Time of schedule 1 (minutes)";
CM_ SG_ 801 Submit_Schedule1 "Schedule 1 submitted";
CM_ SG_ 802 Batt_CabinPriority2 "Bit to prioritize battery charging or cabin conditioning under schedule 2";
CM_ SG_ 802 ChargeUntilFull2 "Charge until battery is fully charged with schedule 2";
CM_ SG_ 802 Do_Not_Repeat2 "Do not repeat the set Schedule";
CM_ SG_ 802 Enable_Schedule2 "Schedule 2 checkbox enabled";
CM_ SG_ 802 End_Time_Hr2 "End Time of schedule 2 (hours in 24 hrs. format)";
CM_ SG_ 802 End_Time_Min2 "End Time of schedule 2 (Minutes)";
CM_ SG_ 802 Schedule_Day2 "Schedule#2 Day for charging or cabin conditioning";
CM_ SG_ 802 Schedule_Type2 "Type of charging and climate schedule";
CM_ SG_ 802 Start_Time_Hr2 "Start Time of schedule 2 (hours in 24 hrs. format)";
CM_ SG_ 802 Start_Time_Min2 "Start Time of schedule 2 (minutes)";
CM_ SG_ 802 Submit_Schedule2 "Schedule 2 submitted";
BA_DEF_ BO_  "App-Botschaft" ENUM  "nein","ja";
BA_DEF_ BO_  "CanMsgMinLen" INT 0 8;
BA_DEF_ BO_  "DiagRequest" ENUM  "nein","ja";
BA_DEF_ BO_  "DiagResponse" ENUM  "nein","ja";
BA_DEF_ BO_  "DiagState" ENUM  "nein","ja";
BA_DEF_ BO_  "GenMsgCycleTime" INT 0 65535;
BA_DEF_ BO_  "GenMsgCycleTimeActive" INT 0 65535;
BA_DEF_ BO_  "GenMsgDelayTime" INT 0 65535;
BA_DEF_ BO_  "GenMsgNrOfRepetitions" INT 0 65535;
BA_DEF_ BO_  "GenMsgSendType" ENUM  "cyclicX","spontanX","cyclicIfActiveX","spontanWithDelay","cyclicAndSpontanX","cyclicAndSpontanWithDelay","spontanWithRepitition","cyclicIfActiveAndSpontanWD","cyclicIfActiveFast","cyclicWithRepeatOnDemand","none";
BA_DEF_ BO_  "GenMsgStartDelayTime" INT 0 65535;
BA_DEF_ BO_  "GenMsgStartValue" STRING ;
BA_DEF_ BO_  "NWM-Botschaft" ENUM  "nein","ja";
BA_DEF_ BO_  "TpTxIndex" INT 0 99;
BA_DEF_ SG_  "FlexKomComment" STRING ;
BA_DEF_ SG_  "FlexKomIsMotorola" ENUM  "nein","ja";
BA_DEF_ SG_  "FlexKomSID" INT 0 2147483647;
BA_DEF_ SG_  "FlexKomSigLaenge" INT 0 64;
BA_DEF_ SG_  "FlexKomSigName" STRING ;
BA_DEF_ SG_  "FlexKomSigStartPos" INT 0 63;
BA_DEF_ SG_  "FlexKomSigStartValue" STRING ;
BA_DEF_ SG_  "GenSigCycleTime" INT 0 65535;
BA_DEF_ SG_  "GenSigCycleTimeActive" INT 0 65535;
BA_DEF_ SG_  "GenSigSendType" ENUM  "cyclicX","spontanX","cyclicIfActiveX","spontanWithDelay","cyclicAndSpontanX","cyclicAndSpontanWithDelay","spontanWithRepitition","cyclicIfActiveAndSpontanWD","cyclicIfActiveFast","cyclicWithRepeatOnDemand","none";
BA_DEF_ SG_  "GenSigSNA" STRING ;
BA_DEF_ SG_  "GenSigStartValue" HEX 0 2147483648;
BA_DEF_ SG_  "GenSigTimeout_AHLM" INT 0 65535;
BA_DEF_ SG_  "GenSigTimeout_ASBS" INT 0 65535;
BA_DEF_ SG_  "GenSigTimeout_CBC" INT 0 65535;
BA_DEF_ SG_  "GenSigTimeout_DPDM" INT 0 65535;
BA_DEF_ SG_  "GenSigTimeout_DTCM" INT 0 65535;
BA_DEF_ SG_  "GenSigTimeout_EHPS" INT 0 65535;
BA_DEF_ SG_  "GenSigTimeout_ESC" INT 0 65535;
BA_DEF_ SG_  "GenSigTimeout_ESL" INT 0 65535;
BA_DEF_ SG_  "GenSigTimeout_ESM" INT 0 65535;
BA_DEF_ SG_  "GenSigTimeout_ETM" INT 0 65535;
BA_DEF_ SG_  "GenSigTimeout_IC" INT 0 65535;
BA_DEF_ SG_  "GenSigTimeout_OCM" INT 0 65535;
BA_DEF_ SG_  "GenSigTimeout_ORC" INT 0 65535;
BA_DEF_ SG_  "GenSigTimeout_PTS" INT 0 65535;
BA_DEF_ SG_  "GenSigTimeout_RF_HUB" INT 0 65535;
BA_DEF_ SG_  "GenSigTimeout_SCCM" INT 0 65535;
BA_DEF_ SG_  "GenSigTimeout_TBM" INT 0 65535;
BA_DEF_ SG_  "GenSigTimeout_TCM" INT 0 65535;
BA_DEF_ SG_  "GenSigTimeout_TPM" INT 0 65535;
BA_DEF_ SG_  "RID" STRING ;
BA_DEF_ SG_  "SystemSignalLongSymbol" STRING ;
BA_DEF_DEF_  "App-Botschaft" "nein";
BA_DEF_DEF_  "CanMsgMinLen" 0;
BA_DEF_DEF_  "DiagRequest" "nein";
BA_DEF_DEF_  "DiagResponse" "nein";
BA_DEF_DEF_  "DiagState" "nein";
BA_DEF_DEF_  "GenMsgCycleTime" 0;
BA_DEF_DEF_  "GenMsgCycleTimeActive" 0;
BA_DEF_DEF_  "GenMsgDelayTime" 0;
BA_DEF_DEF_  "GenMsgNrOfRepetitions" 0;
BA_DEF_DEF_  "GenMsgSendType" "cyclicX";
BA_DEF_DEF_  "GenMsgStartDelayTime" 0;
BA_DEF_DEF_  "GenMsgStartValue" "";
BA_DEF_DEF_  "NWM-Botschaft" "nein";
BA_DEF_DEF_  "TpTxIndex" 0;
BA_DEF_DEF_  "FlexKomComment" "";
BA_DEF_DEF_  "FlexKomIsMotorola" "nein";
BA_DEF_DEF_  "FlexKomSID" 0;
BA_DEF_DEF_  "FlexKomSigLaenge" 0;
BA_DEF_DEF_  "FlexKomSigName" "";
BA_DEF_DEF_  "FlexKomSigStartPos" 0;
BA_DEF_DEF_  "FlexKomSigStartValue" "";
BA_DEF_DEF_  "GenSigCycleTime" 0;
BA_DEF_DEF_  "GenSigCycleTimeActive" 0;
BA_DEF_DEF_  "GenSigSendType" "cyclicX";
BA_DEF_DEF_  "GenSigSNA" "";
BA_DEF_DEF_  "GenSigStartValue" 0;
BA_DEF_DEF_  "GenSigTimeout_AHLM" 0;
BA_DEF_DEF_  "GenSigTimeout_ASBS" 0;
BA_DEF_DEF_  "GenSigTimeout_CBC" 0;
BA_DEF_DEF_  "GenSigTimeout_DPDM" 0;
BA_DEF_DEF_  "GenSigTimeout_DTCM" 0;
BA_DEF_DEF_  "GenSigTimeout_EHPS" 0;
BA_DEF_DEF_  "GenSigTimeout_ESC" 0;
BA_DEF_DEF_  "GenSigTimeout_ESL" 0;
BA_DEF_DEF_  "GenSigTimeout_ESM" 0;
BA_DEF_DEF_  "GenSigTimeout_ETM" 0;
BA_DEF_DEF_  "GenSigTimeout_IC" 0;
BA_DEF_DEF_  "GenSigTimeout_OCM" 0;
BA_DEF_DEF_  "GenSigTimeout_ORC" 0;
BA_DEF_DEF_  "GenSigTimeout_PTS" 0;
BA_DEF_DEF_  "GenSigTimeout_RF_HUB" 0;
BA_DEF_DEF_  "GenSigTimeout_SCCM" 0;
BA_DEF_DEF_  "GenSigTimeout_TBM" 0;
BA_DEF_DEF_  "GenSigTimeout_TCM" 0;
BA_DEF_DEF_  "GenSigTimeout_TPM" 0;
BA_DEF_DEF_  "RID" "";
BA_DEF_DEF_  "SystemSignalLongSymbol" "";
BA_ "GenMsgStartValue" BO_ 1015 "0300000000000000h";
BA_ "GenMsgStartDelayTime" BO_ 1015 80;
BA_ "GenMsgNrOfRepetitions" BO_ 1015 2;
BA_ "GenMsgDelayTime" BO_ 1015 20;
BA_ "GenMsgCycleTime" BO_ 1015 2000;
BA_ "GenMsgStartValue" BO_ 984 "0300000000000000h";
BA_ "GenMsgStartDelayTime" BO_ 984 90;
BA_ "GenMsgNrOfRepetitions" BO_ 984 2;
BA_ "GenMsgDelayTime" BO_ 984 20;
BA_ "GenMsgCycleTime" BO_ 984 2000;
BA_ "GenMsgStartValue" BO_ 833 "0019001900000000h";
BA_ "GenMsgNrOfRepetitions" BO_ 833 2;
BA_ "GenMsgDelayTime" BO_ 833 20;
BA_ "GenMsgCycleTime" BO_ 833 500;
BA_ "GenMsgStartValue" BO_ 908 "FFFFFFFFFFFFFFFFh";
BA_ "GenMsgNrOfRepetitions" BO_ 908 2;
BA_ "GenMsgDelayTime" BO_ 908 20;
BA_ "GenMsgCycleTime" BO_ 908 1000;
BA_ "GenMsgStartValue" BO_ 689 "7F8FFFFF7Fh";
BA_ "GenMsgStartDelayTime" BO_ 689 70;
BA_ "GenMsgSendType" BO_ 689 5;
BA_ "GenMsgNrOfRepetitions" BO_ 689 2;
BA_ "GenMsgDelayTime" BO_ 689 20;
BA_ "GenMsgCycleTime" BO_ 689 1000;
BA_ "GenMsgStartValue" BO_ 609 "FFFFFFFF00000000h";
BA_ "GenMsgStartDelayTime" BO_ 609 90;
BA_ "GenMsgNrOfRepetitions" BO_ 609 2;
BA_ "GenMsgDelayTime" BO_ 609 20;
BA_ "GenMsgCycleTime" BO_ 609 1000;
BA_ "GenMsgStartValue" BO_ 649 "3000071EC0FF8000h";
BA_ "GenMsgStartDelayTime" BO_ 649 80;
BA_ "GenMsgSendType" BO_ 649 5;
BA_ "GenMsgNrOfRepetitions" BO_ 649 2;
BA_ "GenMsgDelayTime" BO_ 649 20;
BA_ "GenMsgCycleTime" BO_ 649 1000;
BA_ "GenMsgStartValue" BO_ 650 "0000000000000000h";
BA_ "GenMsgSendType" BO_ 650 5;
BA_ "GenMsgNrOfRepetitions" BO_ 650 2;
BA_ "GenMsgDelayTime" BO_ 650 20;
BA_ "GenMsgCycleTime" BO_ 650 1000;
BA_ "GenMsgStartValue" BO_ 663 "F0FF0300000C00FFh";
BA_ "GenMsgStartDelayTime" BO_ 663 100;
BA_ "GenMsgSendType" BO_ 663 5;
BA_ "GenMsgNrOfRepetitions" BO_ 663 2;
BA_ "GenMsgDelayTime" BO_ 663 20;
BA_ "GenMsgCycleTime" BO_ 663 1000;
BA_ "GenMsgStartValue" BO_ 641 "07FF07FF00000004h";
BA_ "GenMsgStartDelayTime" BO_ 641 130;
BA_ "GenMsgSendType" BO_ 641 5;
BA_ "GenMsgNrOfRepetitions" BO_ 641 2;
BA_ "GenMsgDelayTime" BO_ 641 20;
BA_ "GenMsgCycleTime" BO_ 641 1000;
BA_ "GenMsgStartValue" BO_ 651 "00000000001E0000h";
BA_ "GenMsgSendType" BO_ 651 5;
BA_ "GenMsgNrOfRepetitions" BO_ 651 2;
BA_ "GenMsgDelayTime" BO_ 651 20;
BA_ "GenMsgCycleTime" BO_ 651 1000;
BA_ "GenMsgStartValue" BO_ 605 "000000007F7F7F7Fh";
BA_ "GenMsgSendType" BO_ 605 5;
BA_ "GenMsgNrOfRepetitions" BO_ 605 2;
BA_ "GenMsgDelayTime" BO_ 605 20;
BA_ "GenMsgCycleTime" BO_ 605 1000;
BA_ "GenMsgStartValue" BO_ 623 "0000FFFFFF7F7F7Fh";
BA_ "GenMsgSendType" BO_ 623 5;
BA_ "GenMsgNrOfRepetitions" BO_ 623 2;
BA_ "GenMsgDelayTime" BO_ 623 20;
BA_ "GenMsgCycleTime" BO_ 623 1000;
BA_ "GenMsgStartValue" BO_ 910 "000000FFFF7F7F00h";
BA_ "GenMsgNrOfRepetitions" BO_ 910 2;
BA_ "GenMsgDelayTime" BO_ 910 20;
BA_ "GenMsgCycleTime" BO_ 910 2000;
BA_ "GenMsgStartValue" BO_ 321 "03000E0000FF01FFh";
BA_ "GenMsgNrOfRepetitions" BO_ 321 2;
BA_ "GenMsgDelayTime" BO_ 321 20;
BA_ "GenMsgCycleTime" BO_ 321 100;
BA_ "GenMsgStartValue" BO_ 298 "01FF0000000000FFh";
BA_ "GenMsgSendType" BO_ 298 5;
BA_ "GenMsgNrOfRepetitions" BO_ 298 2;
BA_ "GenMsgDelayTime" BO_ 298 20;
BA_ "GenMsgCycleTime" BO_ 298 100;
BA_ "GenMsgStartValue" BO_ 611 "0000000000000000h";
BA_ "GenMsgSendType" BO_ 611 5;
BA_ "GenMsgNrOfRepetitions" BO_ 611 2;
BA_ "GenMsgDelayTime" BO_ 611 20;
BA_ "GenMsgCycleTime" BO_ 611 1000;
BA_ "GenMsgStartValue" BO_ 621 "00001E0000000000h";
BA_ "GenMsgSendType" BO_ 621 5;
BA_ "GenMsgNrOfRepetitions" BO_ 621 2;
BA_ "GenMsgDelayTime" BO_ 621 20;
BA_ "GenMsgCycleTime" BO_ 621 1000;
BA_ "GenMsgStartValue" BO_ 40 "1FFF1FFF1FFF00FFh";
BA_ "GenMsgNrOfRepetitions" BO_ 40 2;
BA_ "GenMsgDelayTime" BO_ 40 20;
BA_ "GenMsgCycleTime" BO_ 40 10;
BA_ "GenMsgStartValue" BO_ 54 "1FFF1FFF1FFF00FFh";
BA_ "GenMsgNrOfRepetitions" BO_ 54 2;
BA_ "GenMsgDelayTime" BO_ 54 20;
BA_ "GenMsgCycleTime" BO_ 54 10;
BA_ "GenMsgStartValue" BO_ 56 "1FFF1FFFFFFE00FFh";
BA_ "GenMsgNrOfRepetitions" BO_ 56 2;
BA_ "GenMsgDelayTime" BO_ 56 20;
BA_ "GenMsgCycleTime" BO_ 56 10;
BA_ "GenMsgStartValue" BO_ 315 "00000000646400FFh";
BA_ "GenMsgNrOfRepetitions" BO_ 315 2;
BA_ "GenMsgDelayTime" BO_ 315 20;
BA_ "GenMsgCycleTime" BO_ 315 100;
BA_ "GenMsgStartValue" BO_ 505 "0000000000000000h";
BA_ "GenMsgNrOfRepetitions" BO_ 505 2;
BA_ "GenMsgDelayTime" BO_ 505 20;
BA_ "GenMsgCycleTime" BO_ 505 500;
BA_ "GenMsgStartValue" BO_ 796 "0000000000000000h";
BA_ "GenMsgSendType" BO_ 796 5;
BA_ "GenMsgNrOfRepetitions" BO_ 796 2;
BA_ "GenMsgDelayTime" BO_ 796 20;
BA_ "GenMsgCycleTime" BO_ 796 1000;
BA_ "GenMsgStartValue" BO_ 797 "0000000000000000h";
BA_ "GenMsgSendType" BO_ 797 5;
BA_ "GenMsgNrOfRepetitions" BO_ 797 2;
BA_ "GenMsgDelayTime" BO_ 797 20;
BA_ "GenMsgCycleTime" BO_ 797 1000;
BA_ "GenMsgStartValue" BO_ 798 "0000000000000000h";
BA_ "GenMsgSendType" BO_ 798 5;
BA_ "GenMsgNrOfRepetitions" BO_ 798 2;
BA_ "GenMsgDelayTime" BO_ 798 20;
BA_ "GenMsgCycleTime" BO_ 798 1000;
BA_ "GenMsgStartValue" BO_ 41 "00000000000000FFh";
BA_ "GenMsgNrOfRepetitions" BO_ 41 2;
BA_ "GenMsgDelayTime" BO_ 41 20;
BA_ "GenMsgCycleTime" BO_ 41 10;
BA_ "GenMsgStartValue" BO_ 801 "0000000000000000h";
BA_ "GenMsgSendType" BO_ 801 5;
BA_ "GenMsgNrOfRepetitions" BO_ 801 2;
BA_ "GenMsgDelayTime" BO_ 801 20;
BA_ "GenMsgCycleTime" BO_ 801 1000;
BA_ "GenMsgStartValue" BO_ 802 "0000000000000000h";
BA_ "GenMsgSendType" BO_ 802 5;
BA_ "GenMsgNrOfRepetitions" BO_ 802 2;
BA_ "GenMsgDelayTime" BO_ 802 20;
BA_ "GenMsgCycleTime" BO_ 802 1000;
BA_ "GenSigSNA" SG_ 1015 EC_CBC7A "0h";
BA_ "GenSigCycleTime" SG_ 1015 EC_CBC7A 2000;
BA_ "FlexKomSigStartValue" SG_ 1015 EC_CBC7A "00000000h";
BA_ "FlexKomSigStartPos" SG_ 1015 EC_CBC7A 7;
BA_ "FlexKomSigName" SG_ 1015 EC_CBC7A "EC_CBC7";
BA_ "FlexKomSigLaenge" SG_ 1015 EC_CBC7A 32;
BA_ "FlexKomSID" SG_ 1015 EC_CBC7A 1106;
BA_ "FlexKomIsMotorola" SG_ 1015 EC_CBC7A 1;
BA_ "FlexKomComment" SG_ 1015 EC_CBC7A "CBC ecu configuration 7";
BA_ "GenSigSNA" SG_ 1015 EC_CBC7B "0h";
BA_ "GenSigCycleTime" SG_ 1015 EC_CBC7B 2000;
BA_ "FlexKomSigStartValue" SG_ 1015 EC_CBC7B "00000000h";
BA_ "FlexKomSigStartPos" SG_ 1015 EC_CBC7B 7;
BA_ "FlexKomSigName" SG_ 1015 EC_CBC7B "EC_CBC7";
BA_ "FlexKomSigLaenge" SG_ 1015 EC_CBC7B 32;
BA_ "FlexKomSID" SG_ 1015 EC_CBC7B 1106;
BA_ "FlexKomIsMotorola" SG_ 1015 EC_CBC7B 1;
BA_ "FlexKomComment" SG_ 1015 EC_CBC7B "CBC ecu configuration 7";
BA_ "GenSigSNA" SG_ 1015 EC_CBC8 "0h";
BA_ "GenSigCycleTime" SG_ 1015 EC_CBC8 2000;
BA_ "FlexKomSigStartValue" SG_ 1015 EC_CBC8 "00000000h";
BA_ "FlexKomSigStartPos" SG_ 1015 EC_CBC8 39;
BA_ "FlexKomSigName" SG_ 1015 EC_CBC8 "EC_CBC8";
BA_ "FlexKomSigLaenge" SG_ 1015 EC_CBC8 32;
BA_ "FlexKomSID" SG_ 1015 EC_CBC8 1104;
BA_ "FlexKomIsMotorola" SG_ 1015 EC_CBC8 1;
BA_ "FlexKomComment" SG_ 1015 EC_CBC8 "CBC ecu configuration 8";
BA_ "GenSigStartValue" SG_ 1015 EC_ECUCfg8_Stat 3;
BA_ "GenSigSNA" SG_ 1015 EC_ECUCfg8_Stat "3h";
BA_ "GenSigCycleTime" SG_ 1015 EC_ECUCfg8_Stat 2000;
BA_ "FlexKomSigStartValue" SG_ 1015 EC_ECUCfg8_Stat "03h";
BA_ "FlexKomSigStartPos" SG_ 1015 EC_ECUCfg8_Stat 1;
BA_ "FlexKomSigName" SG_ 1015 EC_ECUCfg8_Stat "EC_ECUCfg8_Stat";
BA_ "FlexKomSigLaenge" SG_ 1015 EC_ECUCfg8_Stat 2;
BA_ "FlexKomSID" SG_ 1015 EC_ECUCfg8_Stat 1101;
BA_ "FlexKomIsMotorola" SG_ 1015 EC_ECUCfg8_Stat 1;
BA_ "FlexKomComment" SG_ 1015 EC_ECUCfg8_Stat "ECU Configuration messages status 8";
BA_ "GenSigSNA" SG_ 984 EC_CBC9A1 "0h";
BA_ "GenSigCycleTime" SG_ 984 EC_CBC9A1 2000;
BA_ "FlexKomSigStartValue" SG_ 984 EC_CBC9A1 "00000000h";
BA_ "FlexKomSigStartPos" SG_ 984 EC_CBC9A1 7;
BA_ "FlexKomSigName" SG_ 984 EC_CBC9A1 "EC_CBC9A";
BA_ "FlexKomSigLaenge" SG_ 984 EC_CBC9A1 32;
BA_ "FlexKomSID" SG_ 984 EC_CBC9A1 1421;
BA_ "FlexKomIsMotorola" SG_ 984 EC_CBC9A1 1;
BA_ "FlexKomComment" SG_ 984 EC_CBC9A1 "CBC configuration 9A";
BA_ "GenSigSNA" SG_ 984 EC_CBC9A2 "0h";
BA_ "GenSigCycleTime" SG_ 984 EC_CBC9A2 2000;
BA_ "FlexKomSigStartValue" SG_ 984 EC_CBC9A2 "00000000h";
BA_ "FlexKomSigStartPos" SG_ 984 EC_CBC9A2 7;
BA_ "FlexKomSigName" SG_ 984 EC_CBC9A2 "EC_CBC9A";
BA_ "FlexKomSigLaenge" SG_ 984 EC_CBC9A2 32;
BA_ "FlexKomSID" SG_ 984 EC_CBC9A2 1421;
BA_ "FlexKomIsMotorola" SG_ 984 EC_CBC9A2 1;
BA_ "FlexKomComment" SG_ 984 EC_CBC9A2 "CBC configuration 9A";
BA_ "GenSigSNA" SG_ 984 EC_CBC9B "0h";
BA_ "GenSigCycleTime" SG_ 984 EC_CBC9B 2000;
BA_ "FlexKomSigStartValue" SG_ 984 EC_CBC9B "0000h";
BA_ "FlexKomSigStartPos" SG_ 984 EC_CBC9B 39;
BA_ "FlexKomSigName" SG_ 984 EC_CBC9B "EC_CBC9B";
BA_ "FlexKomSigLaenge" SG_ 984 EC_CBC9B 16;
BA_ "FlexKomSID" SG_ 984 EC_CBC9B 1422;
BA_ "FlexKomIsMotorola" SG_ 984 EC_CBC9B 1;
BA_ "FlexKomComment" SG_ 984 EC_CBC9B "CBC configuration 9B";
BA_ "GenSigStartValue" SG_ 984 EC_ECUCfg9_Stat 3;
BA_ "GenSigSNA" SG_ 984 EC_ECUCfg9_Stat "3h";
BA_ "GenSigCycleTime" SG_ 984 EC_ECUCfg9_Stat 2000;
BA_ "FlexKomSigStartValue" SG_ 984 EC_ECUCfg9_Stat "03h";
BA_ "FlexKomSigStartPos" SG_ 984 EC_ECUCfg9_Stat 1;
BA_ "FlexKomSigName" SG_ 984 EC_ECUCfg9_Stat "EC_ECUCfg9_Stat";
BA_ "FlexKomSigLaenge" SG_ 984 EC_ECUCfg9_Stat 2;
BA_ "FlexKomSID" SG_ 984 EC_ECUCfg9_Stat 1215;
BA_ "FlexKomIsMotorola" SG_ 984 EC_ECUCfg9_Stat 1;
BA_ "FlexKomComment" SG_ 984 EC_ECUCfg9_Stat "ECU Configuration messages status 9";
BA_ "GenSigSNA" SG_ 984 EC_ITM "0h";
BA_ "GenSigCycleTime" SG_ 984 EC_ITM 2000;
BA_ "FlexKomSigStartValue" SG_ 984 EC_ITM "0000h";
BA_ "FlexKomSigStartPos" SG_ 984 EC_ITM 55;
BA_ "FlexKomSigName" SG_ 984 EC_ITM "EC_ITM";
BA_ "FlexKomSigLaenge" SG_ 984 EC_ITM 16;
BA_ "FlexKomSID" SG_ 984 EC_ITM 1219;
BA_ "FlexKomIsMotorola" SG_ 984 EC_ITM 1;
BA_ "FlexKomComment" SG_ 984 EC_ITM "ITM ecu configuration";
BA_ "GenSigSNA" SG_ 833 GPF_T1_Status "0h";
BA_ "GenSigCycleTime" SG_ 833 GPF_T1_Status 500;
BA_ "FlexKomSigStartValue" SG_ 833 GPF_T1_Status "0019001900000000h";
BA_ "FlexKomSigStartPos" SG_ 833 GPF_T1_Status 7;
BA_ "FlexKomSigName" SG_ 833 GPF_T1_Status "GPF_DATA_1_PKT";
BA_ "FlexKomSigLaenge" SG_ 833 GPF_T1_Status 64;
BA_ "FlexKomSID" SG_ 833 GPF_T1_Status 2850;
BA_ "FlexKomIsMotorola" SG_ 833 GPF_T1_Status 1;
BA_ "FlexKomComment" SG_ 833 GPF_T1_Status "GPF_DATA_1 packet";
BA_ "GenSigStartValue" SG_ 833 GPF_T1_TEMP 25;
BA_ "GenSigSNA" SG_ 833 GPF_T1_TEMP "0h";
BA_ "GenSigCycleTime" SG_ 833 GPF_T1_TEMP 500;
BA_ "FlexKomSigStartValue" SG_ 833 GPF_T1_TEMP "0019001900000000h";
BA_ "FlexKomSigStartPos" SG_ 833 GPF_T1_TEMP 7;
BA_ "FlexKomSigName" SG_ 833 GPF_T1_TEMP "GPF_DATA_1_PKT";
BA_ "FlexKomSigLaenge" SG_ 833 GPF_T1_TEMP 64;
BA_ "FlexKomSID" SG_ 833 GPF_T1_TEMP 2850;
BA_ "FlexKomIsMotorola" SG_ 833 GPF_T1_TEMP 1;
BA_ "FlexKomComment" SG_ 833 GPF_T1_TEMP "GPF_DATA_1 packet";
BA_ "GenSigSNA" SG_ 833 GPF_T2_Status "0h";
BA_ "GenSigCycleTime" SG_ 833 GPF_T2_Status 500;
BA_ "FlexKomSigStartValue" SG_ 833 GPF_T2_Status "0019001900000000h";
BA_ "FlexKomSigStartPos" SG_ 833 GPF_T2_Status 7;
BA_ "FlexKomSigName" SG_ 833 GPF_T2_Status "GPF_DATA_1_PKT";
BA_ "FlexKomSigLaenge" SG_ 833 GPF_T2_Status 64;
BA_ "FlexKomSID" SG_ 833 GPF_T2_Status 2850;
BA_ "FlexKomIsMotorola" SG_ 833 GPF_T2_Status 1;
BA_ "FlexKomComment" SG_ 833 GPF_T2_Status "GPF_DATA_1 packet";
BA_ "GenSigStartValue" SG_ 833 GPF_T2_TEMP 25;
BA_ "GenSigSNA" SG_ 833 GPF_T2_TEMP "0h";
BA_ "GenSigCycleTime" SG_ 833 GPF_T2_TEMP 500;
BA_ "FlexKomSigStartValue" SG_ 833 GPF_T2_TEMP "0019001900000000h";
BA_ "FlexKomSigStartPos" SG_ 833 GPF_T2_TEMP 7;
BA_ "FlexKomSigName" SG_ 833 GPF_T2_TEMP "GPF_DATA_1_PKT";
BA_ "FlexKomSigLaenge" SG_ 833 GPF_T2_TEMP 64;
BA_ "FlexKomSID" SG_ 833 GPF_T2_TEMP 2850;
BA_ "FlexKomIsMotorola" SG_ 833 GPF_T2_TEMP 1;
BA_ "FlexKomComment" SG_ 833 GPF_T2_TEMP "GPF_DATA_1 packet";
BA_ "RID" SG_ 908 GPS_Date_Day "2897";
BA_ "GenSigStartValue" SG_ 908 GPS_Date_Day 255;
BA_ "GenSigSNA" SG_ 908 GPS_Date_Day "FFh";
BA_ "GenSigCycleTime" SG_ 908 GPS_Date_Day 1000;
BA_ "FlexKomSigStartValue" SG_ 908 GPS_Date_Day "FFFFFFFFFFFFFFFFh";
BA_ "FlexKomSigStartPos" SG_ 908 GPS_Date_Day 7;
BA_ "FlexKomSigName" SG_ 908 GPS_Date_Day "GPS_Date_UTC";
BA_ "FlexKomSigLaenge" SG_ 908 GPS_Date_Day 64;
BA_ "FlexKomSID" SG_ 908 GPS_Date_Day 566;
BA_ "FlexKomIsMotorola" SG_ 908 GPS_Date_Day 1;
BA_ "FlexKomComment" SG_ 908 GPS_Date_Day "GPS Date and UTC";
BA_ "RID" SG_ 908 GPS_Date_Month "2895";
BA_ "GenSigStartValue" SG_ 908 GPS_Date_Month 255;
BA_ "GenSigSNA" SG_ 908 GPS_Date_Month "FFh";
BA_ "GenSigCycleTime" SG_ 908 GPS_Date_Month 1000;
BA_ "FlexKomSigStartValue" SG_ 908 GPS_Date_Month "FFFFFFFFFFFFFFFFh";
BA_ "FlexKomSigStartPos" SG_ 908 GPS_Date_Month 7;
BA_ "FlexKomSigName" SG_ 908 GPS_Date_Month "GPS_Date_UTC";
BA_ "FlexKomSigLaenge" SG_ 908 GPS_Date_Month 64;
BA_ "FlexKomSID" SG_ 908 GPS_Date_Month 566;
BA_ "FlexKomIsMotorola" SG_ 908 GPS_Date_Month 1;
BA_ "FlexKomComment" SG_ 908 GPS_Date_Month "GPS Date and UTC";
BA_ "RID" SG_ 908 GPS_Date_Year "2896";
BA_ "GenSigStartValue" SG_ 908 GPS_Date_Year 65535;
BA_ "GenSigSNA" SG_ 908 GPS_Date_Year "FFFFh";
BA_ "GenSigCycleTime" SG_ 908 GPS_Date_Year 1000;
BA_ "FlexKomSigStartValue" SG_ 908 GPS_Date_Year "FFFFFFFFFFFFFFFFh";
BA_ "FlexKomSigStartPos" SG_ 908 GPS_Date_Year 7;
BA_ "FlexKomSigName" SG_ 908 GPS_Date_Year "GPS_Date_UTC";
BA_ "FlexKomSigLaenge" SG_ 908 GPS_Date_Year 64;
BA_ "FlexKomSID" SG_ 908 GPS_Date_Year 566;
BA_ "FlexKomIsMotorola" SG_ 908 GPS_Date_Year 1;
BA_ "FlexKomComment" SG_ 908 GPS_Date_Year "GPS Date and UTC";
BA_ "RID" SG_ 908 GPS_UTC_Hour "2899";
BA_ "GenSigStartValue" SG_ 908 GPS_UTC_Hour 255;
BA_ "GenSigSNA" SG_ 908 GPS_UTC_Hour "FFh";
BA_ "GenSigCycleTime" SG_ 908 GPS_UTC_Hour 1000;
BA_ "FlexKomSigStartValue" SG_ 908 GPS_UTC_Hour "FFFFFFFFFFFFFFFFh";
BA_ "FlexKomSigStartPos" SG_ 908 GPS_UTC_Hour 7;
BA_ "FlexKomSigName" SG_ 908 GPS_UTC_Hour "GPS_Date_UTC";
BA_ "FlexKomSigLaenge" SG_ 908 GPS_UTC_Hour 64;
BA_ "FlexKomSID" SG_ 908 GPS_UTC_Hour 566;
BA_ "FlexKomIsMotorola" SG_ 908 GPS_UTC_Hour 1;
BA_ "FlexKomComment" SG_ 908 GPS_UTC_Hour "GPS Date and UTC";
BA_ "RID" SG_ 908 GPS_UTC_Minute "2902";
BA_ "GenSigStartValue" SG_ 908 GPS_UTC_Minute 255;
BA_ "GenSigSNA" SG_ 908 GPS_UTC_Minute "FFh";
BA_ "GenSigCycleTime" SG_ 908 GPS_UTC_Minute 1000;
BA_ "FlexKomSigStartValue" SG_ 908 GPS_UTC_Minute "FFFFFFFFFFFFFFFFh";
BA_ "FlexKomSigStartPos" SG_ 908 GPS_UTC_Minute 7;
BA_ "FlexKomSigName" SG_ 908 GPS_UTC_Minute "GPS_Date_UTC";
BA_ "FlexKomSigLaenge" SG_ 908 GPS_UTC_Minute 64;
BA_ "FlexKomSID" SG_ 908 GPS_UTC_Minute 566;
BA_ "FlexKomIsMotorola" SG_ 908 GPS_UTC_Minute 1;
BA_ "FlexKomComment" SG_ 908 GPS_UTC_Minute "GPS Date and UTC";
BA_ "RID" SG_ 908 GPS_UTC_Second "2898";
BA_ "GenSigStartValue" SG_ 908 GPS_UTC_Second 65535;
BA_ "GenSigSNA" SG_ 908 GPS_UTC_Second "FFFFh";
BA_ "GenSigCycleTime" SG_ 908 GPS_UTC_Second 1000;
BA_ "FlexKomSigStartValue" SG_ 908 GPS_UTC_Second "FFFFFFFFFFFFFFFFh";
BA_ "FlexKomSigStartPos" SG_ 908 GPS_UTC_Second 7;
BA_ "FlexKomSigName" SG_ 908 GPS_UTC_Second "GPS_Date_UTC";
BA_ "FlexKomSigLaenge" SG_ 908 GPS_UTC_Second 64;
BA_ "FlexKomSID" SG_ 908 GPS_UTC_Second 566;
BA_ "FlexKomIsMotorola" SG_ 908 GPS_UTC_Second 1;
BA_ "FlexKomComment" SG_ 908 GPS_UTC_Second "GPS Date and UTC";
BA_ "RID" SG_ 689 DRV_TEMP_DR_POS "1232";
BA_ "GenSigStartValue" SG_ 689 DRV_TEMP_DR_POS 127;
BA_ "GenSigSNA" SG_ 689 DRV_TEMP_DR_POS "7Fh";
BA_ "GenSigSendType" SG_ 689 DRV_TEMP_DR_POS 5;
BA_ "GenSigCycleTime" SG_ 689 DRV_TEMP_DR_POS 1000;
BA_ "FlexKomSigStartValue" SG_ 689 DRV_TEMP_DR_POS "7F8FFFFF7Fh";
BA_ "FlexKomSigStartPos" SG_ 689 DRV_TEMP_DR_POS 7;
BA_ "FlexKomSigName" SG_ 689 DRV_TEMP_DR_POS "GW_Dev";
BA_ "FlexKomSigLaenge" SG_ 689 DRV_TEMP_DR_POS 40;
BA_ "FlexKomSID" SG_ 689 DRV_TEMP_DR_POS 1445;
BA_ "FlexKomIsMotorola" SG_ 689 DRV_TEMP_DR_POS 1;
BA_ "FlexKomComment" SG_ 689 DRV_TEMP_DR_POS "Temporary development packet - route signals from ";
BA_ "RID" SG_ 689 FT_HVAC_BLW_FN_SP "1070";
BA_ "GenSigTimeout_IC" SG_ 689 FT_HVAC_BLW_FN_SP 10500;
BA_ "GenSigStartValue" SG_ 689 FT_HVAC_BLW_FN_SP 127;
BA_ "GenSigSNA" SG_ 689 FT_HVAC_BLW_FN_SP "7Fh";
BA_ "GenSigSendType" SG_ 689 FT_HVAC_BLW_FN_SP 5;
BA_ "GenSigCycleTime" SG_ 689 FT_HVAC_BLW_FN_SP 1000;
BA_ "FlexKomSigStartValue" SG_ 689 FT_HVAC_BLW_FN_SP "7F8FFFFF7Fh";
BA_ "FlexKomSigStartPos" SG_ 689 FT_HVAC_BLW_FN_SP 7;
BA_ "FlexKomSigName" SG_ 689 FT_HVAC_BLW_FN_SP "GW_Dev";
BA_ "FlexKomSigLaenge" SG_ 689 FT_HVAC_BLW_FN_SP 40;
BA_ "FlexKomSID" SG_ 689 FT_HVAC_BLW_FN_SP 1445;
BA_ "FlexKomIsMotorola" SG_ 689 FT_HVAC_BLW_FN_SP 1;
BA_ "FlexKomComment" SG_ 689 FT_HVAC_BLW_FN_SP "Temporary development packet - route signals from ";
BA_ "RID" SG_ 689 PAS_TEMP_DR_POS "1205";
BA_ "GenSigStartValue" SG_ 689 PAS_TEMP_DR_POS 127;
BA_ "GenSigSNA" SG_ 689 PAS_TEMP_DR_POS "7Fh";
BA_ "GenSigSendType" SG_ 689 PAS_TEMP_DR_POS 5;
BA_ "GenSigCycleTime" SG_ 689 PAS_TEMP_DR_POS 1000;
BA_ "FlexKomSigStartValue" SG_ 689 PAS_TEMP_DR_POS "7F8FFFFF7Fh";
BA_ "FlexKomSigStartPos" SG_ 689 PAS_TEMP_DR_POS 7;
BA_ "FlexKomSigName" SG_ 689 PAS_TEMP_DR_POS "GW_Dev";
BA_ "FlexKomSigLaenge" SG_ 689 PAS_TEMP_DR_POS 40;
BA_ "FlexKomSID" SG_ 689 PAS_TEMP_DR_POS 1445;
BA_ "FlexKomIsMotorola" SG_ 689 PAS_TEMP_DR_POS 1;
BA_ "FlexKomComment" SG_ 689 PAS_TEMP_DR_POS "Temporary development packet - route signals from ";
BA_ "RID" SG_ 609 IBS_Q_received "1817";
BA_ "GenSigStartValue" SG_ 609 IBS_Q_received 65535;
BA_ "GenSigSNA" SG_ 609 IBS_Q_received "FFFFh";
BA_ "GenSigCycleTime" SG_ 609 IBS_Q_received 1000;
BA_ "FlexKomSigStartValue" SG_ 609 IBS_Q_received "FFFFFFFF00000000h";
BA_ "FlexKomSigStartPos" SG_ 609 IBS_Q_received 7;
BA_ "FlexKomSigName" SG_ 609 IBS_Q_received "GW_IBS_DataPkt";
BA_ "FlexKomSigLaenge" SG_ 609 IBS_Q_received 64;
BA_ "FlexKomSID" SG_ 609 IBS_Q_received 1855;
BA_ "FlexKomIsMotorola" SG_ 609 IBS_Q_received 1;
BA_ "FlexKomComment" SG_ 609 IBS_Q_received "LIN to CAN C IBS data";
BA_ "RID" SG_ 609 IBS_Q_released "1815";
BA_ "GenSigStartValue" SG_ 609 IBS_Q_released 65535;
BA_ "GenSigSNA" SG_ 609 IBS_Q_released "FFFFh";
BA_ "GenSigCycleTime" SG_ 609 IBS_Q_released 1000;
BA_ "FlexKomSigStartValue" SG_ 609 IBS_Q_released "FFFFFFFF00000000h";
BA_ "FlexKomSigStartPos" SG_ 609 IBS_Q_released 7;
BA_ "FlexKomSigName" SG_ 609 IBS_Q_released "GW_IBS_DataPkt";
BA_ "FlexKomSigLaenge" SG_ 609 IBS_Q_released 64;
BA_ "FlexKomSID" SG_ 609 IBS_Q_released 1855;
BA_ "FlexKomIsMotorola" SG_ 609 IBS_Q_released 1;
BA_ "FlexKomComment" SG_ 609 IBS_Q_released "LIN to CAN C IBS data";
BA_ "RID" SG_ 609 IBS_Tm_Lst_Reset_Days "1807";
BA_ "GenSigSNA" SG_ 609 IBS_Tm_Lst_Reset_Days "FFFh";
BA_ "GenSigCycleTime" SG_ 609 IBS_Tm_Lst_Reset_Days 1000;
BA_ "FlexKomSigStartValue" SG_ 609 IBS_Tm_Lst_Reset_Days "FFFFFFFF00000000h";
BA_ "FlexKomSigStartPos" SG_ 609 IBS_Tm_Lst_Reset_Days 7;
BA_ "FlexKomSigName" SG_ 609 IBS_Tm_Lst_Reset_Days "GW_IBS_DataPkt";
BA_ "FlexKomSigLaenge" SG_ 609 IBS_Tm_Lst_Reset_Days 64;
BA_ "FlexKomSID" SG_ 609 IBS_Tm_Lst_Reset_Days 1855;
BA_ "FlexKomIsMotorola" SG_ 609 IBS_Tm_Lst_Reset_Days 1;
BA_ "FlexKomComment" SG_ 609 IBS_Tm_Lst_Reset_Days "LIN to CAN C IBS data";
BA_ "RID" SG_ 609 IBS_Tm_Lst_Reset_Sec "1826";
BA_ "GenSigSNA" SG_ 609 IBS_Tm_Lst_Reset_Sec "FFFFh";
BA_ "GenSigCycleTime" SG_ 609 IBS_Tm_Lst_Reset_Sec 1000;
BA_ "FlexKomSigStartValue" SG_ 609 IBS_Tm_Lst_Reset_Sec "FFFFFFFF00000000h";
BA_ "FlexKomSigStartPos" SG_ 609 IBS_Tm_Lst_Reset_Sec 7;
BA_ "FlexKomSigName" SG_ 609 IBS_Tm_Lst_Reset_Sec "GW_IBS_DataPkt";
BA_ "FlexKomSigLaenge" SG_ 609 IBS_Tm_Lst_Reset_Sec 64;
BA_ "FlexKomSID" SG_ 609 IBS_Tm_Lst_Reset_Sec 1855;
BA_ "FlexKomIsMotorola" SG_ 609 IBS_Tm_Lst_Reset_Sec 1;
BA_ "FlexKomComment" SG_ 609 IBS_Tm_Lst_Reset_Sec "LIN to CAN C IBS data";
BA_ "GenSigTimeout_IC" SG_ 649 AHB_ENBL 10500;
BA_ "GenSigSNA" SG_ 649 AHB_ENBL "0h";
BA_ "GenSigSendType" SG_ 649 AHB_ENBL 5;
BA_ "GenSigCycleTime" SG_ 649 AHB_ENBL 1000;
BA_ "FlexKomSigStartValue" SG_ 649 AHB_ENBL "00h";
BA_ "FlexKomSigStartPos" SG_ 649 AHB_ENBL 36;
BA_ "FlexKomSigName" SG_ 649 AHB_ENBL "AHB_ENBL";
BA_ "FlexKomSigLaenge" SG_ 649 AHB_ENBL 1;
BA_ "FlexKomSID" SG_ 649 AHB_ENBL 733;
BA_ "FlexKomIsMotorola" SG_ 649 AHB_ENBL 1;
BA_ "FlexKomComment" SG_ 649 AHB_ENBL "Auto highbeam enable";
BA_ "RID" SG_ 649 ChargeReq "2187 4465";
BA_ "GenSigStartValue" SG_ 649 ChargeReq 1;
BA_ "GenSigSNA" SG_ 649 ChargeReq "1h";
BA_ "GenSigSendType" SG_ 649 ChargeReq 5;
BA_ "GenSigCycleTime" SG_ 649 ChargeReq 1000;
BA_ "FlexKomSigStartValue" SG_ 649 ChargeReq "01h";
BA_ "FlexKomSigStartPos" SG_ 649 ChargeReq 55;
BA_ "FlexKomSigName" SG_ 649 ChargeReq "ChargeReq";
BA_ "FlexKomSigLaenge" SG_ 649 ChargeReq 1;
BA_ "FlexKomSID" SG_ 649 ChargeReq 2418;
BA_ "FlexKomIsMotorola" SG_ 649 ChargeReq 1;
BA_ "FlexKomComment" SG_ 649 ChargeReq "Request for scheduled charge; Charge now = [1]";
BA_ "RID" SG_ 649 HVAC_CLNT_FLW_MIN "2885";
BA_ "GenSigStartValue" SG_ 649 HVAC_CLNT_FLW_MIN 255;
BA_ "GenSigSNA" SG_ 649 HVAC_CLNT_FLW_MIN "FFh";
BA_ "GenSigSendType" SG_ 649 HVAC_CLNT_FLW_MIN 5;
BA_ "GenSigCycleTime" SG_ 649 HVAC_CLNT_FLW_MIN 1000;
BA_ "FlexKomSigStartValue" SG_ 649 HVAC_CLNT_FLW_MIN "FFh";
BA_ "FlexKomSigStartPos" SG_ 649 HVAC_CLNT_FLW_MIN 47;
BA_ "FlexKomSigName" SG_ 649 HVAC_CLNT_FLW_MIN "HVAC_CLNT_FLW_MIN";
BA_ "FlexKomSigLaenge" SG_ 649 HVAC_CLNT_FLW_MIN 8;
BA_ "FlexKomSID" SG_ 649 HVAC_CLNT_FLW_MIN 1527;
BA_ "FlexKomIsMotorola" SG_ 649 HVAC_CLNT_FLW_MIN 1;
BA_ "FlexKomComment" SG_ 649 HVAC_CLNT_FLW_MIN "HVAC coolant flow minimum request";
BA_ "RID" SG_ 649 ICS_btn_17 "2096";
BA_ "GenSigSNA" SG_ 649 ICS_btn_17 "0h";
BA_ "GenSigSendType" SG_ 649 ICS_btn_17 5;
BA_ "GenSigCycleTime" SG_ 649 ICS_btn_17 1000;
BA_ "FlexKomSigStartValue" SG_ 649 ICS_btn_17 "00h";
BA_ "FlexKomSigStartPos" SG_ 649 ICS_btn_17 52;
BA_ "FlexKomSigName" SG_ 649 ICS_btn_17 "ICS_btn_17";
BA_ "FlexKomSigLaenge" SG_ 649 ICS_btn_17 1;
BA_ "FlexKomSID" SG_ 649 ICS_btn_17 1840;
BA_ "FlexKomIsMotorola" SG_ 649 ICS_btn_17 1;
BA_ "FlexKomComment" SG_ 649 ICS_btn_17 "PTS Off pressed";
BA_ "RID" SG_ 649 TRAC_PSD "1155";
BA_ "GenSigSNA" SG_ 649 TRAC_PSD "0h";
BA_ "GenSigSendType" SG_ 649 TRAC_PSD 5;
BA_ "GenSigCycleTime" SG_ 649 TRAC_PSD 1000;
BA_ "FlexKomSigStartValue" SG_ 649 TRAC_PSD "00h";
BA_ "FlexKomSigStartPos" SG_ 649 TRAC_PSD 19;
BA_ "FlexKomSigName" SG_ 649 TRAC_PSD "TRAC_PSD";
BA_ "FlexKomSigLaenge" SG_ 649 TRAC_PSD 1;
BA_ "FlexKomSID" SG_ 649 TRAC_PSD 424;
BA_ "FlexKomIsMotorola" SG_ 649 TRAC_PSD 1;
BA_ "FlexKomComment" SG_ 649 TRAC_PSD "Traction on/off button pressed; [0] = Not Pressed,";
BA_ "RID" SG_ 649 phone_pop_up_active "3052";
BA_ "GenSigTimeout_IC" SG_ 649 phone_pop_up_active 10500;
BA_ "GenSigSNA" SG_ 649 phone_pop_up_active "0h";
BA_ "GenSigSendType" SG_ 649 phone_pop_up_active 5;
BA_ "GenSigCycleTime" SG_ 649 phone_pop_up_active 1000;
BA_ "FlexKomSigStartValue" SG_ 649 phone_pop_up_active "00h";
BA_ "FlexKomSigStartPos" SG_ 649 phone_pop_up_active 30;
BA_ "FlexKomSigName" SG_ 649 phone_pop_up_active "phone_pop_up_active";
BA_ "FlexKomSigLaenge" SG_ 649 phone_pop_up_active 1;
BA_ "FlexKomSID" SG_ 649 phone_pop_up_active 2527;
BA_ "FlexKomIsMotorola" SG_ 649 phone_pop_up_active 1;
BA_ "FlexKomComment" SG_ 649 phone_pop_up_active "Phone pop up is active; True = [1]";
BA_ "RID" SG_ 650 ChargeNow "6625";
BA_ "GenSigSNA" SG_ 650 ChargeNow "0";
BA_ "GenSigSendType" SG_ 650 ChargeNow 5;
BA_ "GenSigCycleTime" SG_ 650 ChargeNow 1000;
BA_ "FlexKomSigStartValue" SG_ 650 ChargeNow "00000000003F0000h";
BA_ "FlexKomSigStartPos" SG_ 650 ChargeNow 7;
BA_ "FlexKomSigName" SG_ 650 ChargeNow "GW_I_C2_pkt";
BA_ "FlexKomSigLaenge" SG_ 650 ChargeNow 64;
BA_ "FlexKomSID" SG_ 650 ChargeNow 2784;
BA_ "FlexKomIsMotorola" SG_ 650 ChargeNow 1;
BA_ "FlexKomComment" SG_ 650 ChargeNow "GW_I_C2 packet";
BA_ "RID" SG_ 650 ChargeNow_TBM "6682";
BA_ "GenSigSNA" SG_ 650 ChargeNow_TBM "0";
BA_ "GenSigSendType" SG_ 650 ChargeNow_TBM 5;
BA_ "GenSigCycleTime" SG_ 650 ChargeNow_TBM 1000;
BA_ "FlexKomSigStartValue" SG_ 650 ChargeNow_TBM "00000000003F0000h";
BA_ "FlexKomSigStartPos" SG_ 650 ChargeNow_TBM 7;
BA_ "FlexKomSigName" SG_ 650 ChargeNow_TBM "GW_I_C2_pkt";
BA_ "FlexKomSigLaenge" SG_ 650 ChargeNow_TBM 64;
BA_ "FlexKomSID" SG_ 650 ChargeNow_TBM 2784;
BA_ "FlexKomIsMotorola" SG_ 650 ChargeNow_TBM 1;
BA_ "FlexKomComment" SG_ 650 ChargeNow_TBM "GW_I_C2 packet";
BA_ "RID" SG_ 663 SpSt_Pad1 "1933";
BA_ "GenSigSNA" SG_ 663 SpSt_Pad1 "7h";
BA_ "GenSigSendType" SG_ 663 SpSt_Pad1 5;
BA_ "GenSigCycleTime" SG_ 663 SpSt_Pad1 1000;
BA_ "FlexKomSigStartValue" SG_ 663 SpSt_Pad1 "00h";
BA_ "FlexKomSigStartPos" SG_ 663 SpSt_Pad1 52;
BA_ "FlexKomSigName" SG_ 663 SpSt_Pad1 "SpSt_Pad1";
BA_ "FlexKomSigLaenge" SG_ 663 SpSt_Pad1 3;
BA_ "FlexKomSID" SG_ 663 SpSt_Pad1 1959;
BA_ "FlexKomIsMotorola" SG_ 663 SpSt_Pad1 1;
BA_ "FlexKomComment" SG_ 663 SpSt_Pad1 "Stop / start switch - pad 1";
BA_ "RID" SG_ 663 SpSt_Pad2 "1934";
BA_ "GenSigSNA" SG_ 663 SpSt_Pad2 "7h";
BA_ "GenSigSendType" SG_ 663 SpSt_Pad2 5;
BA_ "GenSigCycleTime" SG_ 663 SpSt_Pad2 1000;
BA_ "FlexKomSigStartValue" SG_ 663 SpSt_Pad2 "00h";
BA_ "FlexKomSigStartPos" SG_ 663 SpSt_Pad2 55;
BA_ "FlexKomSigName" SG_ 663 SpSt_Pad2 "SpSt_Pad2";
BA_ "FlexKomSigLaenge" SG_ 663 SpSt_Pad2 3;
BA_ "FlexKomSID" SG_ 663 SpSt_Pad2 1960;
BA_ "FlexKomIsMotorola" SG_ 663 SpSt_Pad2 1;
BA_ "FlexKomComment" SG_ 663 SpSt_Pad2 "Stop / start switch - pad 2";
BA_ "RID" SG_ 641 IBS_R_Batt "1917";
BA_ "GenSigStartValue" SG_ 641 IBS_R_Batt 2047;
BA_ "GenSigSNA" SG_ 641 IBS_R_Batt "7FFh";
BA_ "GenSigCycleTime" SG_ 641 IBS_R_Batt 1000;
BA_ "FlexKomSigStartValue" SG_ 641 IBS_R_Batt "07FFh";
BA_ "FlexKomSigStartPos" SG_ 641 IBS_R_Batt 7;
BA_ "FlexKomSigName" SG_ 641 IBS_R_Batt "IBS_R_Batt";
BA_ "FlexKomSigLaenge" SG_ 641 IBS_R_Batt 16;
BA_ "FlexKomSID" SG_ 641 IBS_R_Batt 1948;
BA_ "FlexKomIsMotorola" SG_ 641 IBS_R_Batt 1;
BA_ "FlexKomComment" SG_ 641 IBS_R_Batt "Calculated battery resistance";
BA_ "RID" SG_ 641 IBS_R_Batt_25 "1912";
BA_ "GenSigStartValue" SG_ 641 IBS_R_Batt_25 2047;
BA_ "GenSigSNA" SG_ 641 IBS_R_Batt_25 "7FFh";
BA_ "GenSigCycleTime" SG_ 641 IBS_R_Batt_25 1000;
BA_ "FlexKomSigStartValue" SG_ 641 IBS_R_Batt_25 "07FFh";
BA_ "FlexKomSigStartPos" SG_ 641 IBS_R_Batt_25 23;
BA_ "FlexKomSigName" SG_ 641 IBS_R_Batt_25 "IBS_R_Batt_25";
BA_ "FlexKomSigLaenge" SG_ 641 IBS_R_Batt_25 16;
BA_ "FlexKomSID" SG_ 641 IBS_R_Batt_25 1947;
BA_ "FlexKomIsMotorola" SG_ 641 IBS_R_Batt_25 1;
BA_ "FlexKomComment" SG_ 641 IBS_R_Batt_25 "Batt resistance at 100% SOC and 25 degC";
BA_ "GenSigTimeout_IC" SG_ 641 PaddlesModeReq 10500;
BA_ "GenSigSNA" SG_ 641 PaddlesModeReq "3h";
BA_ "GenSigSendType" SG_ 641 PaddlesModeReq 5;
BA_ "GenSigCycleTime" SG_ 641 PaddlesModeReq 1000;
BA_ "FlexKomSigStartValue" SG_ 641 PaddlesModeReq "00h";
BA_ "FlexKomSigStartPos" SG_ 641 PaddlesModeReq 55;
BA_ "FlexKomSigName" SG_ 641 PaddlesModeReq "PaddlesModeReq";
BA_ "FlexKomSigLaenge" SG_ 641 PaddlesModeReq 2;
BA_ "FlexKomSID" SG_ 641 PaddlesModeReq 2080;
BA_ "FlexKomIsMotorola" SG_ 641 PaddlesModeReq 1;
BA_ "FlexKomComment" SG_ 641 PaddlesModeReq "Requested state of paddle lock-out function";
BA_ "RID" SG_ 641 TBM_E_CALL_STS "2196";
BA_ "GenSigTimeout_IC" SG_ 641 TBM_E_CALL_STS 10500;
BA_ "GenSigSNA" SG_ 641 TBM_E_CALL_STS "Fh";
BA_ "GenSigSendType" SG_ 641 TBM_E_CALL_STS 5;
BA_ "GenSigCycleTime" SG_ 641 TBM_E_CALL_STS 1000;
BA_ "FlexKomSigStartValue" SG_ 641 TBM_E_CALL_STS "00h";
BA_ "FlexKomSigStartPos" SG_ 641 TBM_E_CALL_STS 62;
BA_ "FlexKomSigName" SG_ 641 TBM_E_CALL_STS "TBM_E_CALL_STS";
BA_ "FlexKomSigLaenge" SG_ 641 TBM_E_CALL_STS 4;
BA_ "FlexKomSID" SG_ 641 TBM_E_CALL_STS 2438;
BA_ "FlexKomIsMotorola" SG_ 641 TBM_E_CALL_STS 1;
BA_ "FlexKomComment" SG_ 641 TBM_E_CALL_STS "E call status messages";
BA_ "RID" SG_ 641 TGW_AUD_MD_CAB_DR "2058";
BA_ "GenSigTimeout_IC" SG_ 641 TGW_AUD_MD_CAB_DR 10500;
BA_ "GenSigSNA" SG_ 641 TGW_AUD_MD_CAB_DR "1Fh";
BA_ "GenSigSendType" SG_ 641 TGW_AUD_MD_CAB_DR 5;
BA_ "GenSigCycleTime" SG_ 641 TGW_AUD_MD_CAB_DR 1000;
BA_ "FlexKomSigStartValue" SG_ 641 TGW_AUD_MD_CAB_DR "00h";
BA_ "FlexKomSigStartPos" SG_ 641 TGW_AUD_MD_CAB_DR 7;
BA_ "FlexKomSigName" SG_ 641 TGW_AUD_MD_CAB_DR "TGW_AUD_MD_CAB_DR";
BA_ "FlexKomSigLaenge" SG_ 641 TGW_AUD_MD_CAB_DR 5;
BA_ "FlexKomSID" SG_ 641 TGW_AUD_MD_CAB_DR 672;
BA_ "FlexKomIsMotorola" SG_ 641 TGW_AUD_MD_CAB_DR 1;
BA_ "FlexKomComment" SG_ 641 TGW_AUD_MD_CAB_DR "TGW audio mode for Cabin/Driver";
BA_ "RID" SG_ 641 Trns_DrvMdReq "6575";
BA_ "GenSigTimeout_IC" SG_ 641 Trns_DrvMdReq 10500;
BA_ "GenSigSNA" SG_ 641 Trns_DrvMdReq "Fh";
BA_ "GenSigSendType" SG_ 641 Trns_DrvMdReq 5;
BA_ "GenSigCycleTime" SG_ 641 Trns_DrvMdReq 1000;
BA_ "FlexKomSigStartValue" SG_ 641 Trns_DrvMdReq "00h";
BA_ "FlexKomSigStartPos" SG_ 641 Trns_DrvMdReq 43;
BA_ "FlexKomSigName" SG_ 641 Trns_DrvMdReq "Trns_DrvMdReq";
BA_ "FlexKomSigLaenge" SG_ 641 Trns_DrvMdReq 4;
BA_ "FlexKomSID" SG_ 641 Trns_DrvMdReq 2081;
BA_ "FlexKomIsMotorola" SG_ 641 Trns_DrvMdReq 1;
BA_ "FlexKomComment" SG_ 641 Trns_DrvMdReq "The requested state of the drive mode feature";
BA_ "RID" SG_ 651 HILL_DES_RQ_ICS "5077";
BA_ "GenSigSNA" SG_ 651 HILL_DES_RQ_ICS "3h";
BA_ "GenSigSendType" SG_ 651 HILL_DES_RQ_ICS 5;
BA_ "GenSigCycleTime" SG_ 651 HILL_DES_RQ_ICS 1000;
BA_ "FlexKomSigStartValue" SG_ 651 HILL_DES_RQ_ICS "00h";
BA_ "FlexKomSigStartPos" SG_ 651 HILL_DES_RQ_ICS 50;
BA_ "FlexKomSigName" SG_ 651 HILL_DES_RQ_ICS "HILL_DES_RQ_ICS";
BA_ "FlexKomSigLaenge" SG_ 651 HILL_DES_RQ_ICS 2;
BA_ "FlexKomSID" SG_ 651 HILL_DES_RQ_ICS 2638;
BA_ "FlexKomIsMotorola" SG_ 651 HILL_DES_RQ_ICS 1;
BA_ "FlexKomComment" SG_ 651 HILL_DES_RQ_ICS "Hill descent or select speed status";
BA_ "RID" SG_ 605 AxleLckrOFF_SW "5153";
BA_ "GenSigSNA" SG_ 605 AxleLckrOFF_SW "3h";
BA_ "GenSigSendType" SG_ 605 AxleLckrOFF_SW 5;
BA_ "GenSigCycleTime" SG_ 605 AxleLckrOFF_SW 1000;
BA_ "FlexKomSigStartValue" SG_ 605 AxleLckrOFF_SW "00h";
BA_ "FlexKomSigStartPos" SG_ 605 AxleLckrOFF_SW 7;
BA_ "FlexKomSigName" SG_ 605 AxleLckrOFF_SW "AxleLckrOFF_SW";
BA_ "FlexKomSigLaenge" SG_ 605 AxleLckrOFF_SW 2;
BA_ "FlexKomSID" SG_ 605 AxleLckrOFF_SW 2641;
BA_ "FlexKomIsMotorola" SG_ 605 AxleLckrOFF_SW 1;
BA_ "FlexKomComment" SG_ 605 AxleLckrOFF_SW "Axle locker deactivation switch";
BA_ "RID" SG_ 605 AxleLckrSEL_SW "5152";
BA_ "GenSigSNA" SG_ 605 AxleLckrSEL_SW "3h";
BA_ "GenSigSendType" SG_ 605 AxleLckrSEL_SW 5;
BA_ "GenSigCycleTime" SG_ 605 AxleLckrSEL_SW 1000;
BA_ "FlexKomSigStartValue" SG_ 605 AxleLckrSEL_SW "00h";
BA_ "FlexKomSigStartPos" SG_ 605 AxleLckrSEL_SW 5;
BA_ "FlexKomSigName" SG_ 605 AxleLckrSEL_SW "AxleLckrSEL_SW";
BA_ "FlexKomSigLaenge" SG_ 605 AxleLckrSEL_SW 2;
BA_ "FlexKomSID" SG_ 605 AxleLckrSEL_SW 2640;
BA_ "FlexKomIsMotorola" SG_ 605 AxleLckrSEL_SW 1;
BA_ "FlexKomComment" SG_ 605 AxleLckrSEL_SW "Axle locker selection switch";
BA_ "RID" SG_ 605 Phone_Popup_setting_active "6384";
BA_ "GenSigTimeout_IC" SG_ 605 Phone_Popup_setting_active 10500;
BA_ "GenSigSNA" SG_ 605 Phone_Popup_setting_active "0h";
BA_ "GenSigSendType" SG_ 605 Phone_Popup_setting_active 5;
BA_ "GenSigCycleTime" SG_ 605 Phone_Popup_setting_active 1000;
BA_ "FlexKomSigStartValue" SG_ 605 Phone_Popup_setting_active "00h";
BA_ "FlexKomSigStartPos" SG_ 605 Phone_Popup_setting_active 55;
BA_ "FlexKomSigName" SG_ 605 Phone_Popup_setting_active "Phone_Popup_setting_active";
BA_ "FlexKomSigLaenge" SG_ 605 Phone_Popup_setting_active 1;
BA_ "FlexKomSID" SG_ 605 Phone_Popup_setting_active 2745;
BA_ "FlexKomIsMotorola" SG_ 605 Phone_Popup_setting_active 1;
BA_ "FlexKomComment" SG_ 605 Phone_Popup_setting_active "Phone call status popup active or not, Active=1";
BA_ "RID" SG_ 605 PwrTop_Cal "5073";
BA_ "GenSigTimeout_IC" SG_ 605 PwrTop_Cal 10500;
BA_ "GenSigSNA" SG_ 605 PwrTop_Cal "7h";
BA_ "GenSigSendType" SG_ 605 PwrTop_Cal 5;
BA_ "GenSigCycleTime" SG_ 605 PwrTop_Cal 1000;
BA_ "FlexKomSigStartValue" SG_ 605 PwrTop_Cal "00h";
BA_ "FlexKomSigStartPos" SG_ 605 PwrTop_Cal 15;
BA_ "FlexKomSigName" SG_ 605 PwrTop_Cal "PwrTop_Cal";
BA_ "FlexKomSigLaenge" SG_ 605 PwrTop_Cal 3;
BA_ "FlexKomSID" SG_ 605 PwrTop_Cal 2633;
BA_ "FlexKomIsMotorola" SG_ 605 PwrTop_Cal 1;
BA_ "FlexKomComment" SG_ 605 PwrTop_Cal "Power Top Calibration Status";
BA_ "RID" SG_ 605 PwrTop_Cmd "5074";
BA_ "GenSigTimeout_IC" SG_ 605 PwrTop_Cmd 10500;
BA_ "GenSigSNA" SG_ 605 PwrTop_Cmd "3h";
BA_ "GenSigSendType" SG_ 605 PwrTop_Cmd 5;
BA_ "GenSigCycleTime" SG_ 605 PwrTop_Cmd 1000;
BA_ "FlexKomSigStartValue" SG_ 605 PwrTop_Cmd "00h";
BA_ "FlexKomSigStartPos" SG_ 605 PwrTop_Cmd 1;
BA_ "FlexKomSigName" SG_ 605 PwrTop_Cmd "PwrTop_Cmd";
BA_ "FlexKomSigLaenge" SG_ 605 PwrTop_Cmd 2;
BA_ "FlexKomSID" SG_ 605 PwrTop_Cmd 2634;
BA_ "FlexKomIsMotorola" SG_ 605 PwrTop_Cmd 1;
BA_ "FlexKomComment" SG_ 605 PwrTop_Cmd "Power Top Switch Status";
BA_ "RID" SG_ 605 PwrTop_Pos "5075";
BA_ "GenSigTimeout_IC" SG_ 605 PwrTop_Pos 10500;
BA_ "GenSigSNA" SG_ 605 PwrTop_Pos "0h";
BA_ "GenSigSendType" SG_ 605 PwrTop_Pos 5;
BA_ "GenSigCycleTime" SG_ 605 PwrTop_Pos 1000;
BA_ "FlexKomSigStartValue" SG_ 605 PwrTop_Pos "00h";
BA_ "FlexKomSigStartPos" SG_ 605 PwrTop_Pos 3;
BA_ "FlexKomSigName" SG_ 605 PwrTop_Pos "PwrTop_Pos";
BA_ "FlexKomSigLaenge" SG_ 605 PwrTop_Pos 2;
BA_ "FlexKomSID" SG_ 605 PwrTop_Pos 2635;
BA_ "FlexKomIsMotorola" SG_ 605 PwrTop_Pos 1;
BA_ "FlexKomComment" SG_ 605 PwrTop_Pos "Power Top Roof Position";
BA_ "RID" SG_ 605 PwrTop_Stat "5072";
BA_ "GenSigTimeout_IC" SG_ 605 PwrTop_Stat 10500;
BA_ "GenSigSNA" SG_ 605 PwrTop_Stat "7h";
BA_ "GenSigSendType" SG_ 605 PwrTop_Stat 5;
BA_ "GenSigCycleTime" SG_ 605 PwrTop_Stat 1000;
BA_ "FlexKomSigStartValue" SG_ 605 PwrTop_Stat "00h";
BA_ "FlexKomSigStartPos" SG_ 605 PwrTop_Stat 12;
BA_ "FlexKomSigName" SG_ 605 PwrTop_Stat "PwrTop_Stat";
BA_ "FlexKomSigLaenge" SG_ 605 PwrTop_Stat 3;
BA_ "FlexKomSID" SG_ 605 PwrTop_Stat 2636;
BA_ "FlexKomIsMotorola" SG_ 605 PwrTop_Stat 1;
BA_ "FlexKomComment" SG_ 605 PwrTop_Stat "Power Top Operation Status";
BA_ "RID" SG_ 605 TGW_AUD_MD2_CAB_DR "6336";
BA_ "GenSigTimeout_IC" SG_ 605 TGW_AUD_MD2_CAB_DR 10500;
BA_ "GenSigSNA" SG_ 605 TGW_AUD_MD2_CAB_DR "3Fh";
BA_ "GenSigSendType" SG_ 605 TGW_AUD_MD2_CAB_DR 5;
BA_ "GenSigCycleTime" SG_ 605 TGW_AUD_MD2_CAB_DR 1000;
BA_ "FlexKomSigStartValue" SG_ 605 TGW_AUD_MD2_CAB_DR "00h";
BA_ "FlexKomSigStartPos" SG_ 605 TGW_AUD_MD2_CAB_DR 29;
BA_ "FlexKomSigName" SG_ 605 TGW_AUD_MD2_CAB_DR "TGW_AUD_MD2_CAB_DR";
BA_ "FlexKomSigLaenge" SG_ 605 TGW_AUD_MD2_CAB_DR 6;
BA_ "FlexKomSID" SG_ 605 TGW_AUD_MD2_CAB_DR 2717;
BA_ "FlexKomIsMotorola" SG_ 605 TGW_AUD_MD2_CAB_DR 1;
BA_ "FlexKomComment" SG_ 605 TGW_AUD_MD2_CAB_DR "TGW additional audio modes for Cabin/Driver";
BA_ "RID" SG_ 623 HVAC_Blwr_Perct "2873";
BA_ "GenSigStartValue" SG_ 623 HVAC_Blwr_Perct 127;
BA_ "GenSigSNA" SG_ 623 HVAC_Blwr_Perct "7Fh";
BA_ "GenSigSendType" SG_ 623 HVAC_Blwr_Perct 5;
BA_ "GenSigCycleTime" SG_ 623 HVAC_Blwr_Perct 1000;
BA_ "FlexKomSigStartValue" SG_ 623 HVAC_Blwr_Perct "0000FFFFFF7F7F7Fh";
BA_ "FlexKomSigStartPos" SG_ 623 HVAC_Blwr_Perct 7;
BA_ "FlexKomSigName" SG_ 623 HVAC_Blwr_Perct "GW_LIN_I_C5_Pkt";
BA_ "FlexKomSigLaenge" SG_ 623 HVAC_Blwr_Perct 64;
BA_ "FlexKomSID" SG_ 623 HVAC_Blwr_Perct 2511;
BA_ "FlexKomIsMotorola" SG_ 623 HVAC_Blwr_Perct 1;
BA_ "FlexKomComment" SG_ 623 HVAC_Blwr_Perct "-";
BA_ "RID" SG_ 623 HtrCorTmp_InTgt "2874";
BA_ "GenSigStartValue" SG_ 623 HtrCorTmp_InTgt 255;
BA_ "GenSigSNA" SG_ 623 HtrCorTmp_InTgt "FFh";
BA_ "GenSigSendType" SG_ 623 HtrCorTmp_InTgt 5;
BA_ "GenSigCycleTime" SG_ 623 HtrCorTmp_InTgt 1000;
BA_ "FlexKomSigStartValue" SG_ 623 HtrCorTmp_InTgt "0000FFFFFF7F7F7Fh";
BA_ "FlexKomSigStartPos" SG_ 623 HtrCorTmp_InTgt 7;
BA_ "FlexKomSigName" SG_ 623 HtrCorTmp_InTgt "GW_LIN_I_C5_Pkt";
BA_ "FlexKomSigLaenge" SG_ 623 HtrCorTmp_InTgt 64;
BA_ "FlexKomSID" SG_ 623 HtrCorTmp_InTgt 2511;
BA_ "FlexKomIsMotorola" SG_ 623 HtrCorTmp_InTgt 1;
BA_ "FlexKomComment" SG_ 623 HtrCorTmp_InTgt "-";
BA_ "RID" SG_ 623 SwayBarBtnRq "5136";
BA_ "GenSigTimeout_ASBS" SG_ 623 SwayBarBtnRq 10500;
BA_ "GenSigSNA" SG_ 623 SwayBarBtnRq "3h";
BA_ "GenSigSendType" SG_ 623 SwayBarBtnRq 5;
BA_ "GenSigCycleTime" SG_ 623 SwayBarBtnRq 1000;
BA_ "FlexKomSigStartValue" SG_ 623 SwayBarBtnRq "0000FFFFFF7F7F7Fh";
BA_ "FlexKomSigStartPos" SG_ 623 SwayBarBtnRq 7;
BA_ "FlexKomSigName" SG_ 623 SwayBarBtnRq "GW_LIN_I_C5_Pkt";
BA_ "FlexKomSigLaenge" SG_ 623 SwayBarBtnRq 64;
BA_ "FlexKomSID" SG_ 623 SwayBarBtnRq 2511;
BA_ "FlexKomIsMotorola" SG_ 623 SwayBarBtnRq 1;
BA_ "FlexKomComment" SG_ 623 SwayBarBtnRq "-";
BA_ "RID" SG_ 623 VEH_INT_TEMP "2879";
BA_ "GenSigStartValue" SG_ 623 VEH_INT_TEMP 65535;
BA_ "GenSigSNA" SG_ 623 VEH_INT_TEMP "FFFFh";
BA_ "GenSigSendType" SG_ 623 VEH_INT_TEMP 5;
BA_ "GenSigCycleTime" SG_ 623 VEH_INT_TEMP 1000;
BA_ "FlexKomSigStartValue" SG_ 623 VEH_INT_TEMP "0000FFFFFF7F7F7Fh";
BA_ "FlexKomSigStartPos" SG_ 623 VEH_INT_TEMP 7;
BA_ "FlexKomSigName" SG_ 623 VEH_INT_TEMP "GW_LIN_I_C5_Pkt";
BA_ "FlexKomSigLaenge" SG_ 623 VEH_INT_TEMP 64;
BA_ "FlexKomSID" SG_ 623 VEH_INT_TEMP 2511;
BA_ "FlexKomIsMotorola" SG_ 623 VEH_INT_TEMP 1;
BA_ "FlexKomComment" SG_ 623 VEH_INT_TEMP "-";
BA_ "RID" SG_ 910 IBS3_FLAG_DISCONNECT "5131";
BA_ "GenSigSNA" SG_ 910 IBS3_FLAG_DISCONNECT "0h";
BA_ "GenSigCycleTime" SG_ 910 IBS3_FLAG_DISCONNECT 2000;
BA_ "FlexKomSigStartValue" SG_ 910 IBS3_FLAG_DISCONNECT "00FFFF7F7F80h";
BA_ "FlexKomSigStartPos" SG_ 910 IBS3_FLAG_DISCONNECT 23;
BA_ "FlexKomSigName" SG_ 910 IBS3_FLAG_DISCONNECT "GW_LIN_I_C6_Pkt2";
BA_ "FlexKomSigLaenge" SG_ 910 IBS3_FLAG_DISCONNECT 48;
BA_ "FlexKomSID" SG_ 910 IBS3_FLAG_DISCONNECT 2657;
BA_ "FlexKomIsMotorola" SG_ 910 IBS3_FLAG_DISCONNECT 1;
BA_ "FlexKomComment" SG_ 910 IBS3_FLAG_DISCONNECT "Cyclic only";
BA_ "RID" SG_ 910 IBS3_SOC "5121";
BA_ "GenSigStartValue" SG_ 910 IBS3_SOC 127;
BA_ "GenSigSNA" SG_ 910 IBS3_SOC "7Fh";
BA_ "GenSigCycleTime" SG_ 910 IBS3_SOC 2000;
BA_ "FlexKomSigStartValue" SG_ 910 IBS3_SOC "00FFFF7F7F80h";
BA_ "FlexKomSigStartPos" SG_ 910 IBS3_SOC 23;
BA_ "FlexKomSigName" SG_ 910 IBS3_SOC "GW_LIN_I_C6_Pkt2";
BA_ "FlexKomSigLaenge" SG_ 910 IBS3_SOC 48;
BA_ "FlexKomSID" SG_ 910 IBS3_SOC 2657;
BA_ "FlexKomIsMotorola" SG_ 910 IBS3_SOC 1;
BA_ "FlexKomComment" SG_ 910 IBS3_SOC "Cyclic only";
BA_ "RID" SG_ 910 IBS3_SOC_Accuracy "5104";
BA_ "GenSigSNA" SG_ 910 IBS3_SOC_Accuracy "0h";
BA_ "GenSigCycleTime" SG_ 910 IBS3_SOC_Accuracy 2000;
BA_ "FlexKomSigStartValue" SG_ 910 IBS3_SOC_Accuracy "00FFFF7F7F80h";
BA_ "FlexKomSigStartPos" SG_ 910 IBS3_SOC_Accuracy 23;
BA_ "FlexKomSigName" SG_ 910 IBS3_SOC_Accuracy "GW_LIN_I_C6_Pkt2";
BA_ "FlexKomSigLaenge" SG_ 910 IBS3_SOC_Accuracy 48;
BA_ "FlexKomSID" SG_ 910 IBS3_SOC_Accuracy 2657;
BA_ "FlexKomIsMotorola" SG_ 910 IBS3_SOC_Accuracy 1;
BA_ "FlexKomComment" SG_ 910 IBS3_SOC_Accuracy "Cyclic only";
BA_ "RID" SG_ 910 IBS3_SOF_Q "5145";
BA_ "GenSigStartValue" SG_ 910 IBS3_SOF_Q 255;
BA_ "GenSigSNA" SG_ 910 IBS3_SOF_Q "FFh";
BA_ "GenSigCycleTime" SG_ 910 IBS3_SOF_Q 2000;
BA_ "FlexKomSigStartValue" SG_ 910 IBS3_SOF_Q "00FFFF7F7F80h";
BA_ "FlexKomSigStartPos" SG_ 910 IBS3_SOF_Q 23;
BA_ "FlexKomSigName" SG_ 910 IBS3_SOF_Q "GW_LIN_I_C6_Pkt2";
BA_ "FlexKomSigLaenge" SG_ 910 IBS3_SOF_Q 48;
BA_ "FlexKomSID" SG_ 910 IBS3_SOF_Q 2657;
BA_ "FlexKomIsMotorola" SG_ 910 IBS3_SOF_Q 1;
BA_ "FlexKomComment" SG_ 910 IBS3_SOF_Q "Cyclic only";
BA_ "RID" SG_ 910 IBS3_SOF_Q_Accuracy "5133";
BA_ "GenSigSNA" SG_ 910 IBS3_SOF_Q_Accuracy "0h";
BA_ "GenSigCycleTime" SG_ 910 IBS3_SOF_Q_Accuracy 2000;
BA_ "FlexKomSigStartValue" SG_ 910 IBS3_SOF_Q_Accuracy "00FFFF7F7F80h";
BA_ "FlexKomSigStartPos" SG_ 910 IBS3_SOF_Q_Accuracy 23;
BA_ "FlexKomSigName" SG_ 910 IBS3_SOF_Q_Accuracy "GW_LIN_I_C6_Pkt2";
BA_ "FlexKomSigLaenge" SG_ 910 IBS3_SOF_Q_Accuracy 48;
BA_ "FlexKomSID" SG_ 910 IBS3_SOF_Q_Accuracy 2657;
BA_ "FlexKomIsMotorola" SG_ 910 IBS3_SOF_Q_Accuracy 1;
BA_ "FlexKomComment" SG_ 910 IBS3_SOF_Q_Accuracy "Cyclic only";
BA_ "RID" SG_ 910 IBS3_SOF_VC "5115";
BA_ "GenSigSNA" SG_ 910 IBS3_SOF_VC "7Fh";
BA_ "GenSigCycleTime" SG_ 910 IBS3_SOF_VC 2000;
BA_ "FlexKomSigStartValue" SG_ 910 IBS3_SOF_VC "00FFFF7F7F80h";
BA_ "FlexKomSigStartPos" SG_ 910 IBS3_SOF_VC 23;
BA_ "FlexKomSigName" SG_ 910 IBS3_SOF_VC "GW_LIN_I_C6_Pkt2";
BA_ "FlexKomSigLaenge" SG_ 910 IBS3_SOF_VC 48;
BA_ "FlexKomSID" SG_ 910 IBS3_SOF_VC 2657;
BA_ "FlexKomIsMotorola" SG_ 910 IBS3_SOF_VC 1;
BA_ "FlexKomComment" SG_ 910 IBS3_SOF_VC "Cyclic only";
BA_ "RID" SG_ 910 IBS3_SOF_V_Accuracy "5129";
BA_ "GenSigStartValue" SG_ 910 IBS3_SOF_V_Accuracy 1;
BA_ "GenSigSNA" SG_ 910 IBS3_SOF_V_Accuracy "1h";
BA_ "GenSigCycleTime" SG_ 910 IBS3_SOF_V_Accuracy 2000;
BA_ "FlexKomSigStartValue" SG_ 910 IBS3_SOF_V_Accuracy "00FFFF7F7F80h";
BA_ "FlexKomSigStartPos" SG_ 910 IBS3_SOF_V_Accuracy 23;
BA_ "FlexKomSigName" SG_ 910 IBS3_SOF_V_Accuracy "GW_LIN_I_C6_Pkt2";
BA_ "FlexKomSigLaenge" SG_ 910 IBS3_SOF_V_Accuracy 48;
BA_ "FlexKomSID" SG_ 910 IBS3_SOF_V_Accuracy 2657;
BA_ "FlexKomIsMotorola" SG_ 910 IBS3_SOF_V_Accuracy 1;
BA_ "FlexKomComment" SG_ 910 IBS3_SOF_V_Accuracy "Cyclic only";
BA_ "RID" SG_ 910 IBS3_SOH_Q "5148";
BA_ "GenSigStartValue" SG_ 910 IBS3_SOH_Q 127;
BA_ "GenSigSNA" SG_ 910 IBS3_SOH_Q "7Fh";
BA_ "GenSigCycleTime" SG_ 910 IBS3_SOH_Q 2000;
BA_ "FlexKomSigStartValue" SG_ 910 IBS3_SOH_Q "00FFFF7F7F80h";
BA_ "FlexKomSigStartPos" SG_ 910 IBS3_SOH_Q 23;
BA_ "FlexKomSigName" SG_ 910 IBS3_SOH_Q "GW_LIN_I_C6_Pkt2";
BA_ "FlexKomSigLaenge" SG_ 910 IBS3_SOH_Q 48;
BA_ "FlexKomSID" SG_ 910 IBS3_SOH_Q 2657;
BA_ "FlexKomIsMotorola" SG_ 910 IBS3_SOH_Q 1;
BA_ "FlexKomComment" SG_ 910 IBS3_SOH_Q "Cyclic only";
BA_ "RID" SG_ 910 IBS3_SOH_Q_Accuracy "5086";
BA_ "GenSigSNA" SG_ 910 IBS3_SOH_Q_Accuracy "0h";
BA_ "GenSigCycleTime" SG_ 910 IBS3_SOH_Q_Accuracy 2000;
BA_ "FlexKomSigStartValue" SG_ 910 IBS3_SOH_Q_Accuracy "00FFFF7F7F80h";
BA_ "FlexKomSigStartPos" SG_ 910 IBS3_SOH_Q_Accuracy 23;
BA_ "FlexKomSigName" SG_ 910 IBS3_SOH_Q_Accuracy "GW_LIN_I_C6_Pkt2";
BA_ "FlexKomSigLaenge" SG_ 910 IBS3_SOH_Q_Accuracy 48;
BA_ "FlexKomSID" SG_ 910 IBS3_SOH_Q_Accuracy 2657;
BA_ "FlexKomIsMotorola" SG_ 910 IBS3_SOH_Q_Accuracy 1;
BA_ "FlexKomComment" SG_ 910 IBS3_SOH_Q_Accuracy "Cyclic only";
BA_ "RID" SG_ 910 IBS3_T_BATT "5105";
BA_ "GenSigStartValue" SG_ 910 IBS3_T_BATT 255;
BA_ "GenSigSNA" SG_ 910 IBS3_T_BATT "FFh";
BA_ "GenSigCycleTime" SG_ 910 IBS3_T_BATT 2000;
BA_ "FlexKomSigStartValue" SG_ 910 IBS3_T_BATT "00FFFF7F7F80h";
BA_ "FlexKomSigStartPos" SG_ 910 IBS3_T_BATT 23;
BA_ "FlexKomSigName" SG_ 910 IBS3_T_BATT "GW_LIN_I_C6_Pkt2";
BA_ "FlexKomSigLaenge" SG_ 910 IBS3_T_BATT 48;
BA_ "FlexKomSID" SG_ 910 IBS3_T_BATT 2657;
BA_ "FlexKomIsMotorola" SG_ 910 IBS3_T_BATT 1;
BA_ "FlexKomComment" SG_ 910 IBS3_T_BATT "Cyclic only";
BA_ "RID" SG_ 910 IBS3_TempFailStatus "5082";
BA_ "GenSigSNA" SG_ 910 IBS3_TempFailStatus "0h";
BA_ "GenSigCycleTime" SG_ 910 IBS3_TempFailStatus 2000;
BA_ "FlexKomSigStartValue" SG_ 910 IBS3_TempFailStatus "00FFFF7F7F80h";
BA_ "FlexKomSigStartPos" SG_ 910 IBS3_TempFailStatus 23;
BA_ "FlexKomSigName" SG_ 910 IBS3_TempFailStatus "GW_LIN_I_C6_Pkt2";
BA_ "FlexKomSigLaenge" SG_ 910 IBS3_TempFailStatus 48;
BA_ "FlexKomSID" SG_ 910 IBS3_TempFailStatus 2657;
BA_ "FlexKomIsMotorola" SG_ 910 IBS3_TempFailStatus 1;
BA_ "FlexKomComment" SG_ 910 IBS3_TempFailStatus "Cyclic only";
BA_ "GenSigTimeout_IC" SG_ 321 BatPwrUsage 1050;
BA_ "GenSigSNA" SG_ 321 BatPwrUsage "0h";
BA_ "GenSigCycleTime" SG_ 321 BatPwrUsage 100;
BA_ "FlexKomSigStartValue" SG_ 321 BatPwrUsage "03000E0000FF01FFh";
BA_ "FlexKomSigStartPos" SG_ 321 BatPwrUsage 7;
BA_ "FlexKomSigName" SG_ 321 BatPwrUsage "HCP_1";
BA_ "FlexKomSigLaenge" SG_ 321 BatPwrUsage 64;
BA_ "FlexKomSID" SG_ 321 BatPwrUsage 2198;
BA_ "FlexKomIsMotorola" SG_ 321 BatPwrUsage 1;
BA_ "FlexKomComment" SG_ 321 BatPwrUsage "HCP message 1 packet";
BA_ "GenSigTimeout_IC" SG_ 321 BatPwrUsage_V 1050;
BA_ "GenSigSNA" SG_ 321 BatPwrUsage_V "0h";
BA_ "GenSigCycleTime" SG_ 321 BatPwrUsage_V 100;
BA_ "FlexKomSigStartValue" SG_ 321 BatPwrUsage_V "03000E0000FF01FFh";
BA_ "FlexKomSigStartPos" SG_ 321 BatPwrUsage_V 7;
BA_ "FlexKomSigName" SG_ 321 BatPwrUsage_V "HCP_1";
BA_ "FlexKomSigLaenge" SG_ 321 BatPwrUsage_V 64;
BA_ "FlexKomSID" SG_ 321 BatPwrUsage_V 2198;
BA_ "FlexKomIsMotorola" SG_ 321 BatPwrUsage_V 1;
BA_ "FlexKomComment" SG_ 321 BatPwrUsage_V "HCP message 1 packet";
BA_ "RID" SG_ 321 Echarge_SOCRange_Cnfm "6558";
BA_ "GenSigSNA" SG_ 321 Echarge_SOCRange_Cnfm "0h";
BA_ "GenSigCycleTime" SG_ 321 Echarge_SOCRange_Cnfm 100;
BA_ "FlexKomSigStartValue" SG_ 321 Echarge_SOCRange_Cnfm "03000E0000FF01FFh";
BA_ "FlexKomSigStartPos" SG_ 321 Echarge_SOCRange_Cnfm 7;
BA_ "FlexKomSigName" SG_ 321 Echarge_SOCRange_Cnfm "HCP_1";
BA_ "FlexKomSigLaenge" SG_ 321 Echarge_SOCRange_Cnfm 64;
BA_ "FlexKomSID" SG_ 321 Echarge_SOCRange_Cnfm 2198;
BA_ "FlexKomIsMotorola" SG_ 321 Echarge_SOCRange_Cnfm 1;
BA_ "FlexKomComment" SG_ 321 Echarge_SOCRange_Cnfm "HCP message 1 packet";
BA_ "RID" SG_ 321 Echarge_Type_Cnfm "6559";
BA_ "GenSigSNA" SG_ 321 Echarge_Type_Cnfm "0h";
BA_ "GenSigCycleTime" SG_ 321 Echarge_Type_Cnfm 100;
BA_ "FlexKomSigStartValue" SG_ 321 Echarge_Type_Cnfm "03000E0000FF01FFh";
BA_ "FlexKomSigStartPos" SG_ 321 Echarge_Type_Cnfm 7;
BA_ "FlexKomSigName" SG_ 321 Echarge_Type_Cnfm "HCP_1";
BA_ "FlexKomSigLaenge" SG_ 321 Echarge_Type_Cnfm 64;
BA_ "FlexKomSID" SG_ 321 Echarge_Type_Cnfm 2198;
BA_ "FlexKomIsMotorola" SG_ 321 Echarge_Type_Cnfm 1;
BA_ "FlexKomComment" SG_ 321 Echarge_Type_Cnfm "HCP message 1 packet";
BA_ "GenSigTimeout_IC" SG_ 321 Est_Range 1050;
BA_ "GenSigStartValue" SG_ 321 Est_Range 255;
BA_ "GenSigSNA" SG_ 321 Est_Range "FFh";
BA_ "GenSigCycleTime" SG_ 321 Est_Range 100;
BA_ "FlexKomSigStartValue" SG_ 321 Est_Range "03000E0000FF01FFh";
BA_ "FlexKomSigStartPos" SG_ 321 Est_Range 7;
BA_ "FlexKomSigName" SG_ 321 Est_Range "HCP_1";
BA_ "FlexKomSigLaenge" SG_ 321 Est_Range 64;
BA_ "FlexKomSID" SG_ 321 Est_Range 2198;
BA_ "FlexKomIsMotorola" SG_ 321 Est_Range 1;
BA_ "FlexKomComment" SG_ 321 Est_Range "HCP message 1 packet";
BA_ "RID" SG_ 321 HEV_EVT_MD "6517";
BA_ "GenSigTimeout_IC" SG_ 321 HEV_EVT_MD 1050;
BA_ "GenSigTimeout_CBC" SG_ 321 HEV_EVT_MD 10500;
BA_ "GenSigStartValue" SG_ 321 HEV_EVT_MD 1;
BA_ "GenSigSNA" SG_ 321 HEV_EVT_MD "1h";
BA_ "GenSigCycleTime" SG_ 321 HEV_EVT_MD 100;
BA_ "FlexKomSigStartValue" SG_ 321 HEV_EVT_MD "03000E0000FF01FFh";
BA_ "FlexKomSigStartPos" SG_ 321 HEV_EVT_MD 7;
BA_ "FlexKomSigName" SG_ 321 HEV_EVT_MD "HCP_1";
BA_ "FlexKomSigLaenge" SG_ 321 HEV_EVT_MD 64;
BA_ "FlexKomSID" SG_ 321 HEV_EVT_MD 2198;
BA_ "FlexKomIsMotorola" SG_ 321 HEV_EVT_MD 1;
BA_ "FlexKomComment" SG_ 321 HEV_EVT_MD "HCP message 1 packet";
BA_ "GenSigTimeout_IC" SG_ 321 HEV_LMP_RQ 1050;
BA_ "GenSigStartValue" SG_ 321 HEV_LMP_RQ 3;
BA_ "GenSigSNA" SG_ 321 HEV_LMP_RQ "3h";
BA_ "GenSigCycleTime" SG_ 321 HEV_LMP_RQ 100;
BA_ "FlexKomSigStartValue" SG_ 321 HEV_LMP_RQ "03000E0000FF01FFh";
BA_ "FlexKomSigStartPos" SG_ 321 HEV_LMP_RQ 7;
BA_ "FlexKomSigName" SG_ 321 HEV_LMP_RQ "HCP_1";
BA_ "FlexKomSigLaenge" SG_ 321 HEV_LMP_RQ 64;
BA_ "FlexKomSID" SG_ 321 HEV_LMP_RQ 2198;
BA_ "FlexKomIsMotorola" SG_ 321 HEV_LMP_RQ 1;
BA_ "FlexKomComment" SG_ 321 HEV_LMP_RQ "HCP message 1 packet";
BA_ "GenSigSNA" SG_ 321 MaxRegenLedCmd "3h";
BA_ "GenSigCycleTime" SG_ 321 MaxRegenLedCmd 100;
BA_ "FlexKomSigStartValue" SG_ 321 MaxRegenLedCmd "03000E0000FF01FFh";
BA_ "FlexKomSigStartPos" SG_ 321 MaxRegenLedCmd 7;
BA_ "FlexKomSigName" SG_ 321 MaxRegenLedCmd "HCP_1";
BA_ "FlexKomSigLaenge" SG_ 321 MaxRegenLedCmd 64;
BA_ "FlexKomSID" SG_ 321 MaxRegenLedCmd 2198;
BA_ "FlexKomIsMotorola" SG_ 321 MaxRegenLedCmd 1;
BA_ "FlexKomComment" SG_ 321 MaxRegenLedCmd "HCP message 1 packet";
BA_ "RID" SG_ 321 R134a_PressSts "5059";
BA_ "GenSigTimeout_CBC" SG_ 321 R134a_PressSts 1050;
BA_ "GenSigStartValue" SG_ 321 R134a_PressSts 511;
BA_ "GenSigSNA" SG_ 321 R134a_PressSts "1FFh";
BA_ "GenSigCycleTime" SG_ 321 R134a_PressSts 100;
BA_ "FlexKomSigStartValue" SG_ 321 R134a_PressSts "03000E0000FF01FFh";
BA_ "FlexKomSigStartPos" SG_ 321 R134a_PressSts 7;
BA_ "FlexKomSigName" SG_ 321 R134a_PressSts "HCP_1";
BA_ "FlexKomSigLaenge" SG_ 321 R134a_PressSts 64;
BA_ "FlexKomSID" SG_ 321 R134a_PressSts 2198;
BA_ "FlexKomIsMotorola" SG_ 321 R134a_PressSts 1;
BA_ "FlexKomComment" SG_ 321 R134a_PressSts "HCP message 1 packet";
BA_ "GenSigStartValue" SG_ 298 BSGActualTorque 511;
BA_ "GenSigSNA" SG_ 298 BSGActualTorque "3FFh";
BA_ "GenSigSendType" SG_ 298 BSGActualTorque 5;
BA_ "GenSigCycleTime" SG_ 298 BSGActualTorque 100;
BA_ "FlexKomSigStartValue" SG_ 298 BSGActualTorque "01FF0000000000FFh";
BA_ "FlexKomSigStartPos" SG_ 298 BSGActualTorque 7;
BA_ "FlexKomSigName" SG_ 298 BSGActualTorque "HCP_100";
BA_ "FlexKomSigLaenge" SG_ 298 BSGActualTorque 64;
BA_ "FlexKomSID" SG_ 298 BSGActualTorque 2820;
BA_ "FlexKomIsMotorola" SG_ 298 BSGActualTorque 1;
BA_ "FlexKomComment" SG_ 298 BSGActualTorque "HCP_100 message packet";
BA_ "GenSigStartValue" SG_ 298 CRC_12Ah 255;
BA_ "GenSigSNA" SG_ 298 CRC_12Ah "FFh";
BA_ "GenSigCycleTime" SG_ 298 CRC_12Ah 100;
BA_ "FlexKomSigStartValue" SG_ 298 CRC_12Ah "01FF0000000000FFh";
BA_ "FlexKomSigStartPos" SG_ 298 CRC_12Ah 7;
BA_ "FlexKomSigName" SG_ 298 CRC_12Ah "HCP_100";
BA_ "FlexKomSigLaenge" SG_ 298 CRC_12Ah 64;
BA_ "FlexKomSID" SG_ 298 CRC_12Ah 2820;
BA_ "FlexKomIsMotorola" SG_ 298 CRC_12Ah 1;
BA_ "FlexKomComment" SG_ 298 CRC_12Ah "HCP_100 message packet";
BA_ "GenSigSNA" SG_ 298 HCP_Comm_Fail_ePT "0h";
BA_ "GenSigSendType" SG_ 298 HCP_Comm_Fail_ePT 5;
BA_ "GenSigCycleTime" SG_ 298 HCP_Comm_Fail_ePT 100;
BA_ "FlexKomSigStartValue" SG_ 298 HCP_Comm_Fail_ePT "01FF0000000000FFh";
BA_ "FlexKomSigStartPos" SG_ 298 HCP_Comm_Fail_ePT 7;
BA_ "FlexKomSigName" SG_ 298 HCP_Comm_Fail_ePT "HCP_100";
BA_ "FlexKomSigLaenge" SG_ 298 HCP_Comm_Fail_ePT 64;
BA_ "FlexKomSID" SG_ 298 HCP_Comm_Fail_ePT 2820;
BA_ "FlexKomIsMotorola" SG_ 298 HCP_Comm_Fail_ePT 1;
BA_ "FlexKomComment" SG_ 298 HCP_Comm_Fail_ePT "HCP_100 message packet";
BA_ "GenSigSNA" SG_ 298 HCP_Shutdown_Command "7h";
BA_ "GenSigSendType" SG_ 298 HCP_Shutdown_Command 5;
BA_ "GenSigCycleTime" SG_ 298 HCP_Shutdown_Command 100;
BA_ "FlexKomSigStartValue" SG_ 298 HCP_Shutdown_Command "01FF0000000000FFh";
BA_ "FlexKomSigStartPos" SG_ 298 HCP_Shutdown_Command 7;
BA_ "FlexKomSigName" SG_ 298 HCP_Shutdown_Command "HCP_100";
BA_ "FlexKomSigLaenge" SG_ 298 HCP_Shutdown_Command 64;
BA_ "FlexKomSID" SG_ 298 HCP_Shutdown_Command 2820;
BA_ "FlexKomIsMotorola" SG_ 298 HCP_Shutdown_Command 1;
BA_ "FlexKomComment" SG_ 298 HCP_Shutdown_Command "HCP_100 message packet";
BA_ "GenSigSNA" SG_ 298 Hybrid_Immobilizer_Status "3h";
BA_ "GenSigSendType" SG_ 298 Hybrid_Immobilizer_Status 5;
BA_ "GenSigCycleTime" SG_ 298 Hybrid_Immobilizer_Status 100;
BA_ "FlexKomSigStartValue" SG_ 298 Hybrid_Immobilizer_Status "01FF0000000000FFh";
BA_ "FlexKomSigStartPos" SG_ 298 Hybrid_Immobilizer_Status 7;
BA_ "FlexKomSigName" SG_ 298 Hybrid_Immobilizer_Status "HCP_100";
BA_ "FlexKomSigLaenge" SG_ 298 Hybrid_Immobilizer_Status 64;
BA_ "FlexKomSID" SG_ 298 Hybrid_Immobilizer_Status 2820;
BA_ "FlexKomIsMotorola" SG_ 298 Hybrid_Immobilizer_Status 1;
BA_ "FlexKomComment" SG_ 298 Hybrid_Immobilizer_Status "HCP_100 message packet";
BA_ "GenSigSNA" SG_ 298 MC_12Ah "0h";
BA_ "GenSigCycleTime" SG_ 298 MC_12Ah 100;
BA_ "FlexKomSigStartValue" SG_ 298 MC_12Ah "01FF0000000000FFh";
BA_ "FlexKomSigStartPos" SG_ 298 MC_12Ah 7;
BA_ "FlexKomSigName" SG_ 298 MC_12Ah "HCP_100";
BA_ "FlexKomSigLaenge" SG_ 298 MC_12Ah 64;
BA_ "FlexKomSID" SG_ 298 MC_12Ah 2820;
BA_ "FlexKomIsMotorola" SG_ 298 MC_12Ah 1;
BA_ "FlexKomComment" SG_ 298 MC_12Ah "HCP_100 message packet";
BA_ "RID" SG_ 611 ChargingLevel "6518";
BA_ "GenSigTimeout_IC" SG_ 611 ChargingLevel 10500;
BA_ "GenSigTimeout_CBC" SG_ 611 ChargingLevel 10500;
BA_ "GenSigSNA" SG_ 611 ChargingLevel "Fh";
BA_ "GenSigSendType" SG_ 611 ChargingLevel 5;
BA_ "GenSigCycleTime" SG_ 611 ChargingLevel 1000;
BA_ "FlexKomSigStartValue" SG_ 611 ChargingLevel "0000000000000000h";
BA_ "FlexKomSigStartPos" SG_ 611 ChargingLevel 7;
BA_ "FlexKomSigName" SG_ 611 ChargingLevel "HCP_1000";
BA_ "FlexKomSigLaenge" SG_ 611 ChargingLevel 64;
BA_ "FlexKomSID" SG_ 611 ChargingLevel 2373;
BA_ "FlexKomIsMotorola" SG_ 611 ChargingLevel 1;
BA_ "FlexKomComment" SG_ 611 ChargingLevel "HCP 1000ms packet";
BA_ "RID" SG_ 611 ChargingSysSts "6523";
BA_ "GenSigTimeout_IC" SG_ 611 ChargingSysSts 10500;
BA_ "GenSigTimeout_CBC" SG_ 611 ChargingSysSts 10500;
BA_ "GenSigSNA" SG_ 611 ChargingSysSts "7h";
BA_ "GenSigSendType" SG_ 611 ChargingSysSts 5;
BA_ "GenSigCycleTime" SG_ 611 ChargingSysSts 1000;
BA_ "FlexKomSigStartValue" SG_ 611 ChargingSysSts "0000000000000000h";
BA_ "FlexKomSigStartPos" SG_ 611 ChargingSysSts 7;
BA_ "FlexKomSigName" SG_ 611 ChargingSysSts "HCP_1000";
BA_ "FlexKomSigLaenge" SG_ 611 ChargingSysSts 64;
BA_ "FlexKomSID" SG_ 611 ChargingSysSts 2373;
BA_ "FlexKomIsMotorola" SG_ 611 ChargingSysSts 1;
BA_ "FlexKomComment" SG_ 611 ChargingSysSts "HCP 1000ms packet";
BA_ "GenSigTimeout_IC" SG_ 611 ChrgSysFault 10500;
BA_ "GenSigSNA" SG_ 611 ChrgSysFault "0h";
BA_ "GenSigSendType" SG_ 611 ChrgSysFault 5;
BA_ "GenSigCycleTime" SG_ 611 ChrgSysFault 1000;
BA_ "FlexKomSigStartValue" SG_ 611 ChrgSysFault "0000000000000000h";
BA_ "FlexKomSigStartPos" SG_ 611 ChrgSysFault 7;
BA_ "FlexKomSigName" SG_ 611 ChrgSysFault "HCP_1000";
BA_ "FlexKomSigLaenge" SG_ 611 ChrgSysFault 64;
BA_ "FlexKomSID" SG_ 611 ChrgSysFault 2373;
BA_ "FlexKomIsMotorola" SG_ 611 ChrgSysFault 1;
BA_ "FlexKomComment" SG_ 611 ChrgSysFault "HCP 1000ms packet";
BA_ "RID" SG_ 611 CompStat "3581 3587";
BA_ "GenSigTimeout_CBC" SG_ 611 CompStat 10500;
BA_ "GenSigSNA" SG_ 611 CompStat "Fh";
BA_ "GenSigSendType" SG_ 611 CompStat 5;
BA_ "GenSigCycleTime" SG_ 611 CompStat 1000;
BA_ "FlexKomSigStartValue" SG_ 611 CompStat "0000000000000000h";
BA_ "FlexKomSigStartPos" SG_ 611 CompStat 7;
BA_ "FlexKomSigName" SG_ 611 CompStat "HCP_1000";
BA_ "FlexKomSigLaenge" SG_ 611 CompStat 64;
BA_ "FlexKomSID" SG_ 611 CompStat 2373;
BA_ "FlexKomIsMotorola" SG_ 611 CompStat 1;
BA_ "FlexKomComment" SG_ 611 CompStat "HCP 1000ms packet";
BA_ "GenSigTimeout_IC" SG_ 611 DriveReady 10500;
BA_ "GenSigSNA" SG_ 611 DriveReady "0h";
BA_ "GenSigSendType" SG_ 611 DriveReady 5;
BA_ "GenSigCycleTime" SG_ 611 DriveReady 1000;
BA_ "FlexKomSigStartValue" SG_ 611 DriveReady "0000000000000000h";
BA_ "FlexKomSigStartPos" SG_ 611 DriveReady 7;
BA_ "FlexKomSigName" SG_ 611 DriveReady "HCP_1000";
BA_ "FlexKomSigLaenge" SG_ 611 DriveReady 64;
BA_ "FlexKomSID" SG_ 611 DriveReady 2373;
BA_ "FlexKomIsMotorola" SG_ 611 DriveReady 1;
BA_ "FlexKomComment" SG_ 611 DriveReady "HCP 1000ms packet";
BA_ "RID" SG_ 611 EstTimeofChrg_Lv1 "6508";
BA_ "GenSigTimeout_IC" SG_ 611 EstTimeofChrg_Lv1 10500;
BA_ "GenSigTimeout_CBC" SG_ 611 EstTimeofChrg_Lv1 10500;
BA_ "GenSigSNA" SG_ 611 EstTimeofChrg_Lv1 "1FFFh";
BA_ "GenSigSendType" SG_ 611 EstTimeofChrg_Lv1 5;
BA_ "GenSigCycleTime" SG_ 611 EstTimeofChrg_Lv1 1000;
BA_ "FlexKomSigStartValue" SG_ 611 EstTimeofChrg_Lv1 "0000000000000000h";
BA_ "FlexKomSigStartPos" SG_ 611 EstTimeofChrg_Lv1 7;
BA_ "FlexKomSigName" SG_ 611 EstTimeofChrg_Lv1 "HCP_1000";
BA_ "FlexKomSigLaenge" SG_ 611 EstTimeofChrg_Lv1 64;
BA_ "FlexKomSID" SG_ 611 EstTimeofChrg_Lv1 2373;
BA_ "FlexKomIsMotorola" SG_ 611 EstTimeofChrg_Lv1 1;
BA_ "FlexKomComment" SG_ 611 EstTimeofChrg_Lv1 "HCP 1000ms packet";
BA_ "RID" SG_ 611 EstTimeofChrg_Lv2 "6507";
BA_ "GenSigTimeout_IC" SG_ 611 EstTimeofChrg_Lv2 10500;
BA_ "GenSigTimeout_CBC" SG_ 611 EstTimeofChrg_Lv2 10500;
BA_ "GenSigSNA" SG_ 611 EstTimeofChrg_Lv2 "7FFh";
BA_ "GenSigSendType" SG_ 611 EstTimeofChrg_Lv2 5;
BA_ "GenSigCycleTime" SG_ 611 EstTimeofChrg_Lv2 1000;
BA_ "FlexKomSigStartValue" SG_ 611 EstTimeofChrg_Lv2 "0000000000000000h";
BA_ "FlexKomSigStartPos" SG_ 611 EstTimeofChrg_Lv2 7;
BA_ "FlexKomSigName" SG_ 611 EstTimeofChrg_Lv2 "HCP_1000";
BA_ "FlexKomSigLaenge" SG_ 611 EstTimeofChrg_Lv2 64;
BA_ "FlexKomSID" SG_ 611 EstTimeofChrg_Lv2 2373;
BA_ "FlexKomIsMotorola" SG_ 611 EstTimeofChrg_Lv2 1;
BA_ "FlexKomComment" SG_ 611 EstTimeofChrg_Lv2 "HCP 1000ms packet";
BA_ "GenSigTimeout_IC" SG_ 611 HVBatCntctrStat 10500;
BA_ "GenSigSNA" SG_ 611 HVBatCntctrStat "7h";
BA_ "GenSigSendType" SG_ 611 HVBatCntctrStat 5;
BA_ "GenSigCycleTime" SG_ 611 HVBatCntctrStat 1000;
BA_ "FlexKomSigStartValue" SG_ 611 HVBatCntctrStat "0000000000000000h";
BA_ "FlexKomSigStartPos" SG_ 611 HVBatCntctrStat 7;
BA_ "FlexKomSigName" SG_ 611 HVBatCntctrStat "HCP_1000";
BA_ "FlexKomSigLaenge" SG_ 611 HVBatCntctrStat 64;
BA_ "FlexKomSID" SG_ 611 HVBatCntctrStat 2373;
BA_ "FlexKomIsMotorola" SG_ 611 HVBatCntctrStat 1;
BA_ "FlexKomComment" SG_ 611 HVBatCntctrStat "HCP 1000ms packet";
BA_ "GenSigSNA" SG_ 611 HtrCoreInletTemp "FFh";
BA_ "GenSigSendType" SG_ 611 HtrCoreInletTemp 5;
BA_ "GenSigCycleTime" SG_ 611 HtrCoreInletTemp 1000;
BA_ "FlexKomSigStartValue" SG_ 611 HtrCoreInletTemp "0000000000000000h";
BA_ "FlexKomSigStartPos" SG_ 611 HtrCoreInletTemp 7;
BA_ "FlexKomSigName" SG_ 611 HtrCoreInletTemp "HCP_1000";
BA_ "FlexKomSigLaenge" SG_ 611 HtrCoreInletTemp 64;
BA_ "FlexKomSID" SG_ 611 HtrCoreInletTemp 2373;
BA_ "FlexKomIsMotorola" SG_ 611 HtrCoreInletTemp 1;
BA_ "FlexKomComment" SG_ 611 HtrCoreInletTemp "HCP 1000ms packet";
BA_ "GenSigTimeout_IC" SG_ 611 MIL_OnRq_BPCM 10500;
BA_ "GenSigSNA" SG_ 611 MIL_OnRq_BPCM "0h";
BA_ "GenSigSendType" SG_ 611 MIL_OnRq_BPCM 5;
BA_ "GenSigCycleTime" SG_ 611 MIL_OnRq_BPCM 1000;
BA_ "FlexKomSigStartValue" SG_ 611 MIL_OnRq_BPCM "0000000000000000h";
BA_ "FlexKomSigStartPos" SG_ 611 MIL_OnRq_BPCM 7;
BA_ "FlexKomSigName" SG_ 611 MIL_OnRq_BPCM "HCP_1000";
BA_ "FlexKomSigLaenge" SG_ 611 MIL_OnRq_BPCM 64;
BA_ "FlexKomSID" SG_ 611 MIL_OnRq_BPCM 2373;
BA_ "FlexKomIsMotorola" SG_ 611 MIL_OnRq_BPCM 1;
BA_ "FlexKomComment" SG_ 611 MIL_OnRq_BPCM "HCP 1000ms packet";
BA_ "RID" SG_ 611 PrplsnSysAtv "3065";
BA_ "GenSigTimeout_IC" SG_ 611 PrplsnSysAtv 10500;
BA_ "GenSigSNA" SG_ 611 PrplsnSysAtv "0h";
BA_ "GenSigSendType" SG_ 611 PrplsnSysAtv 5;
BA_ "GenSigCycleTime" SG_ 611 PrplsnSysAtv 1000;
BA_ "FlexKomSigStartValue" SG_ 611 PrplsnSysAtv "0000000000000000h";
BA_ "FlexKomSigStartPos" SG_ 611 PrplsnSysAtv 7;
BA_ "FlexKomSigName" SG_ 611 PrplsnSysAtv "HCP_1000";
BA_ "FlexKomSigLaenge" SG_ 611 PrplsnSysAtv 64;
BA_ "FlexKomSID" SG_ 611 PrplsnSysAtv 2373;
BA_ "FlexKomIsMotorola" SG_ 611 PrplsnSysAtv 1;
BA_ "FlexKomComment" SG_ 611 PrplsnSysAtv "HCP 1000ms packet";
BA_ "GenSigSNA" SG_ 621 ElecClntHtrInletTemp "FFh";
BA_ "GenSigSendType" SG_ 621 ElecClntHtrInletTemp 5;
BA_ "GenSigCycleTime" SG_ 621 ElecClntHtrInletTemp 1000;
BA_ "FlexKomSigStartValue" SG_ 621 ElecClntHtrInletTemp "00001E000001FF00h";
BA_ "FlexKomSigStartPos" SG_ 621 ElecClntHtrInletTemp 7;
BA_ "FlexKomSigName" SG_ 621 ElecClntHtrInletTemp "HCP_2";
BA_ "FlexKomSigLaenge" SG_ 621 ElecClntHtrInletTemp 64;
BA_ "FlexKomSID" SG_ 621 ElecClntHtrInletTemp 2512;
BA_ "FlexKomIsMotorola" SG_ 621 ElecClntHtrInletTemp 1;
BA_ "FlexKomComment" SG_ 621 ElecClntHtrInletTemp "HCP message 2 packet";
BA_ "RID" SG_ 621 ElecCoolantHtrPwr "5018";
BA_ "GenSigTimeout_CBC" SG_ 621 ElecCoolantHtrPwr 10500;
BA_ "GenSigSNA" SG_ 621 ElecCoolantHtrPwr "FFh";
BA_ "GenSigSendType" SG_ 621 ElecCoolantHtrPwr 5;
BA_ "GenSigCycleTime" SG_ 621 ElecCoolantHtrPwr 1000;
BA_ "FlexKomSigStartValue" SG_ 621 ElecCoolantHtrPwr "00001E000001FF00h";
BA_ "FlexKomSigStartPos" SG_ 621 ElecCoolantHtrPwr 7;
BA_ "FlexKomSigName" SG_ 621 ElecCoolantHtrPwr "HCP_2";
BA_ "FlexKomSigLaenge" SG_ 621 ElecCoolantHtrPwr 64;
BA_ "FlexKomSID" SG_ 621 ElecCoolantHtrPwr 2512;
BA_ "FlexKomIsMotorola" SG_ 621 ElecCoolantHtrPwr 1;
BA_ "FlexKomComment" SG_ 621 ElecCoolantHtrPwr "HCP message 2 packet";
BA_ "RID" SG_ 621 FRfShVlvSts "2871";
BA_ "GenSigSNA" SG_ 621 FRfShVlvSts "0h";
BA_ "GenSigSendType" SG_ 621 FRfShVlvSts 5;
BA_ "GenSigCycleTime" SG_ 621 FRfShVlvSts 1000;
BA_ "FlexKomSigStartValue" SG_ 621 FRfShVlvSts "00001E000001FF00h";
BA_ "FlexKomSigStartPos" SG_ 621 FRfShVlvSts 7;
BA_ "FlexKomSigName" SG_ 621 FRfShVlvSts "HCP_2";
BA_ "FlexKomSigLaenge" SG_ 621 FRfShVlvSts 64;
BA_ "FlexKomSID" SG_ 621 FRfShVlvSts 2512;
BA_ "FlexKomIsMotorola" SG_ 621 FRfShVlvSts 1;
BA_ "FlexKomComment" SG_ 621 FRfShVlvSts "HCP message 2 packet";
BA_ "GenSigStartValue" SG_ 621 HTAuxPmpMontrngRPM 3;
BA_ "GenSigSNA" SG_ 621 HTAuxPmpMontrngRPM "3h";
BA_ "GenSigSendType" SG_ 621 HTAuxPmpMontrngRPM 5;
BA_ "GenSigCycleTime" SG_ 621 HTAuxPmpMontrngRPM 1000;
BA_ "FlexKomSigStartValue" SG_ 621 HTAuxPmpMontrngRPM "00001E000001FF00h";
BA_ "FlexKomSigStartPos" SG_ 621 HTAuxPmpMontrngRPM 7;
BA_ "FlexKomSigName" SG_ 621 HTAuxPmpMontrngRPM "HCP_2";
BA_ "FlexKomSigLaenge" SG_ 621 HTAuxPmpMontrngRPM 64;
BA_ "FlexKomSID" SG_ 621 HTAuxPmpMontrngRPM 2512;
BA_ "FlexKomIsMotorola" SG_ 621 HTAuxPmpMontrngRPM 1;
BA_ "FlexKomComment" SG_ 621 HTAuxPmpMontrngRPM "HCP message 2 packet";
BA_ "RID" SG_ 621 HTAuxPmpRPMAct "5020";
BA_ "GenSigTimeout_CBC" SG_ 621 HTAuxPmpRPMAct 10500;
BA_ "GenSigSNA" SG_ 621 HTAuxPmpRPMAct "FFh";
BA_ "GenSigSendType" SG_ 621 HTAuxPmpRPMAct 5;
BA_ "GenSigCycleTime" SG_ 621 HTAuxPmpRPMAct 1000;
BA_ "FlexKomSigStartValue" SG_ 621 HTAuxPmpRPMAct "00001E000001FF00h";
BA_ "FlexKomSigStartPos" SG_ 621 HTAuxPmpRPMAct 7;
BA_ "FlexKomSigName" SG_ 621 HTAuxPmpRPMAct "HCP_2";
BA_ "FlexKomSigLaenge" SG_ 621 HTAuxPmpRPMAct 64;
BA_ "FlexKomSID" SG_ 621 HTAuxPmpRPMAct 2512;
BA_ "FlexKomIsMotorola" SG_ 621 HTAuxPmpRPMAct 1;
BA_ "FlexKomComment" SG_ 621 HTAuxPmpRPMAct "HCP message 2 packet";
BA_ "RID" SG_ 621 HTShtOffVlvReq "3066";
BA_ "GenSigSNA" SG_ 621 HTShtOffVlvReq "0h";
BA_ "GenSigSendType" SG_ 621 HTShtOffVlvReq 5;
BA_ "GenSigCycleTime" SG_ 621 HTShtOffVlvReq 1000;
BA_ "FlexKomSigStartValue" SG_ 621 HTShtOffVlvReq "00001E000001FF00h";
BA_ "FlexKomSigStartPos" SG_ 621 HTShtOffVlvReq 7;
BA_ "FlexKomSigName" SG_ 621 HTShtOffVlvReq "HCP_2";
BA_ "FlexKomSigLaenge" SG_ 621 HTShtOffVlvReq 64;
BA_ "FlexKomSID" SG_ 621 HTShtOffVlvReq 2512;
BA_ "FlexKomIsMotorola" SG_ 621 HTShtOffVlvReq 1;
BA_ "FlexKomComment" SG_ 621 HTShtOffVlvReq "HCP message 2 packet";
BA_ "RID" SG_ 621 HVBatCritCondT "5019";
BA_ "GenSigSNA" SG_ 621 HVBatCritCondT "0h";
BA_ "GenSigSendType" SG_ 621 HVBatCritCondT 5;
BA_ "GenSigCycleTime" SG_ 621 HVBatCritCondT 1000;
BA_ "FlexKomSigStartValue" SG_ 621 HVBatCritCondT "00001E000001FF00h";
BA_ "FlexKomSigStartPos" SG_ 621 HVBatCritCondT 7;
BA_ "FlexKomSigName" SG_ 621 HVBatCritCondT "HCP_2";
BA_ "FlexKomSigLaenge" SG_ 621 HVBatCritCondT 64;
BA_ "FlexKomSID" SG_ 621 HVBatCritCondT 2512;
BA_ "FlexKomIsMotorola" SG_ 621 HVBatCritCondT 1;
BA_ "FlexKomComment" SG_ 621 HVBatCritCondT "HCP message 2 packet";
BA_ "GenSigTimeout_IC" SG_ 621 HVBat_CoolantLvlLo 10500;
BA_ "GenSigStartValue" SG_ 621 HVBat_CoolantLvlLo 3;
BA_ "GenSigSNA" SG_ 621 HVBat_CoolantLvlLo "3h";
BA_ "GenSigSendType" SG_ 621 HVBat_CoolantLvlLo 5;
BA_ "GenSigCycleTime" SG_ 621 HVBat_CoolantLvlLo 1000;
BA_ "FlexKomSigStartValue" SG_ 621 HVBat_CoolantLvlLo "00001E000001FF00h";
BA_ "FlexKomSigStartPos" SG_ 621 HVBat_CoolantLvlLo 7;
BA_ "FlexKomSigName" SG_ 621 HVBat_CoolantLvlLo "HCP_2";
BA_ "FlexKomSigLaenge" SG_ 621 HVBat_CoolantLvlLo 64;
BA_ "FlexKomSID" SG_ 621 HVBat_CoolantLvlLo 2512;
BA_ "FlexKomIsMotorola" SG_ 621 HVBat_CoolantLvlLo 1;
BA_ "FlexKomComment" SG_ 621 HVBat_CoolantLvlLo "HCP message 2 packet";
BA_ "GenSigStartValue" SG_ 40 CRC_HCP_A1 255;
BA_ "GenSigSNA" SG_ 40 CRC_HCP_A1 "FFh";
BA_ "GenSigCycleTime" SG_ 40 CRC_HCP_A1 10;
BA_ "FlexKomSigStartValue" SG_ 40 CRC_HCP_A1 "1FFF1FFF1FFF00FFh";
BA_ "FlexKomSigStartPos" SG_ 40 CRC_HCP_A1 7;
BA_ "FlexKomSigName" SG_ 40 CRC_HCP_A1 "HCP_A1_PKT";
BA_ "FlexKomSigLaenge" SG_ 40 CRC_HCP_A1 64;
BA_ "FlexKomSID" SG_ 40 CRC_HCP_A1 2990;
BA_ "FlexKomIsMotorola" SG_ 40 CRC_HCP_A1 1;
BA_ "FlexKomComment" SG_ 40 CRC_HCP_A1 "HCP_A1_PKT";
BA_ "GenSigSNA" SG_ 40 MC_HCP_A1 "0h";
BA_ "GenSigCycleTime" SG_ 40 MC_HCP_A1 10;
BA_ "FlexKomSigStartValue" SG_ 40 MC_HCP_A1 "1FFF1FFF1FFF00FFh";
BA_ "FlexKomSigStartPos" SG_ 40 MC_HCP_A1 7;
BA_ "FlexKomSigName" SG_ 40 MC_HCP_A1 "HCP_A1_PKT";
BA_ "FlexKomSigLaenge" SG_ 40 MC_HCP_A1 64;
BA_ "FlexKomSID" SG_ 40 MC_HCP_A1 2990;
BA_ "FlexKomIsMotorola" SG_ 40 MC_HCP_A1 1;
BA_ "FlexKomComment" SG_ 40 MC_HCP_A1 "HCP_A1_PKT";
BA_ "GenSigTimeout_IC" SG_ 40 SumTrqMax 105;
BA_ "GenSigStartValue" SG_ 40 SumTrqMax 8191;
BA_ "GenSigSNA" SG_ 40 SumTrqMax "1FFFh";
BA_ "GenSigCycleTime" SG_ 40 SumTrqMax 10;
BA_ "FlexKomSigStartValue" SG_ 40 SumTrqMax "1FFF1FFF1FFF00FFh";
BA_ "FlexKomSigStartPos" SG_ 40 SumTrqMax 7;
BA_ "FlexKomSigName" SG_ 40 SumTrqMax "HCP_A1_PKT";
BA_ "FlexKomSigLaenge" SG_ 40 SumTrqMax 64;
BA_ "FlexKomSID" SG_ 40 SumTrqMax 2990;
BA_ "FlexKomIsMotorola" SG_ 40 SumTrqMax 1;
BA_ "FlexKomComment" SG_ 40 SumTrqMax "HCP_A1_PKT";
BA_ "GenSigTimeout_IC" SG_ 40 SumTrqMin 105;
BA_ "GenSigStartValue" SG_ 40 SumTrqMin 8191;
BA_ "GenSigSNA" SG_ 40 SumTrqMin "1FFFh";
BA_ "GenSigCycleTime" SG_ 40 SumTrqMin 10;
BA_ "FlexKomSigStartValue" SG_ 40 SumTrqMin "1FFF1FFF1FFF00FFh";
BA_ "FlexKomSigStartPos" SG_ 40 SumTrqMin 7;
BA_ "FlexKomSigName" SG_ 40 SumTrqMin "HCP_A1_PKT";
BA_ "FlexKomSigLaenge" SG_ 40 SumTrqMin 64;
BA_ "FlexKomSID" SG_ 40 SumTrqMin 2990;
BA_ "FlexKomIsMotorola" SG_ 40 SumTrqMin 1;
BA_ "FlexKomComment" SG_ 40 SumTrqMin "HCP_A1_PKT";
BA_ "RID" SG_ 40 SumTrqStatic "2184";
BA_ "GenSigTimeout_TCM" SG_ 40 SumTrqStatic 105;
BA_ "GenSigTimeout_IC" SG_ 40 SumTrqStatic 105;
BA_ "GenSigTimeout_DTCM" SG_ 40 SumTrqStatic 105;
BA_ "GenSigTimeout_CBC" SG_ 40 SumTrqStatic 105;
BA_ "GenSigStartValue" SG_ 40 SumTrqStatic 8191;
BA_ "GenSigSNA" SG_ 40 SumTrqStatic "1FFFh";
BA_ "GenSigCycleTime" SG_ 40 SumTrqStatic 10;
BA_ "FlexKomSigStartValue" SG_ 40 SumTrqStatic "1FFF1FFF1FFF00FFh";
BA_ "FlexKomSigStartPos" SG_ 40 SumTrqStatic 7;
BA_ "FlexKomSigName" SG_ 40 SumTrqStatic "HCP_A1_PKT";
BA_ "FlexKomSigLaenge" SG_ 40 SumTrqStatic 64;
BA_ "FlexKomSID" SG_ 40 SumTrqStatic 2990;
BA_ "FlexKomIsMotorola" SG_ 40 SumTrqStatic 1;
BA_ "FlexKomComment" SG_ 40 SumTrqStatic "HCP_A1_PKT";
BA_ "GenSigStartValue" SG_ 54 CRC_HCP_A2 255;
BA_ "GenSigSNA" SG_ 54 CRC_HCP_A2 "FFh";
BA_ "GenSigCycleTime" SG_ 54 CRC_HCP_A2 10;
BA_ "FlexKomSigStartValue" SG_ 54 CRC_HCP_A2 "1FFF1FFF1FFF00FFh";
BA_ "FlexKomSigStartPos" SG_ 54 CRC_HCP_A2 7;
BA_ "FlexKomSigName" SG_ 54 CRC_HCP_A2 "HCP_A2_PKT";
BA_ "FlexKomSigLaenge" SG_ 54 CRC_HCP_A2 64;
BA_ "FlexKomSID" SG_ 54 CRC_HCP_A2 2994;
BA_ "FlexKomIsMotorola" SG_ 54 CRC_HCP_A2 1;
BA_ "FlexKomComment" SG_ 54 CRC_HCP_A2 "HCP_A2_PKT";
BA_ "GenSigTimeout_DTCM" SG_ 54 ExpSumTrq 105;
BA_ "GenSigStartValue" SG_ 54 ExpSumTrq 8191;
BA_ "GenSigSNA" SG_ 54 ExpSumTrq "1FFFh";
BA_ "GenSigCycleTime" SG_ 54 ExpSumTrq 10;
BA_ "FlexKomSigStartValue" SG_ 54 ExpSumTrq "1FFF1FFF1FFF00FFh";
BA_ "FlexKomSigStartPos" SG_ 54 ExpSumTrq 7;
BA_ "FlexKomSigName" SG_ 54 ExpSumTrq "HCP_A2_PKT";
BA_ "FlexKomSigLaenge" SG_ 54 ExpSumTrq 64;
BA_ "FlexKomSID" SG_ 54 ExpSumTrq 2994;
BA_ "FlexKomIsMotorola" SG_ 54 ExpSumTrq 1;
BA_ "FlexKomComment" SG_ 54 ExpSumTrq "HCP_A2_PKT";
BA_ "GenSigSNA" SG_ 54 MC_HCP_A2 "0h";
BA_ "GenSigCycleTime" SG_ 54 MC_HCP_A2 10;
BA_ "FlexKomSigStartValue" SG_ 54 MC_HCP_A2 "1FFF1FFF1FFF00FFh";
BA_ "FlexKomSigStartPos" SG_ 54 MC_HCP_A2 7;
BA_ "FlexKomSigName" SG_ 54 MC_HCP_A2 "HCP_A2_PKT";
BA_ "FlexKomSigLaenge" SG_ 54 MC_HCP_A2 64;
BA_ "FlexKomSID" SG_ 54 MC_HCP_A2 2994;
BA_ "FlexKomIsMotorola" SG_ 54 MC_HCP_A2 1;
BA_ "FlexKomComment" SG_ 54 MC_HCP_A2 "HCP_A2_PKT";
BA_ "GenSigStartValue" SG_ 54 SumTrqStatic_SEM 8191;
BA_ "GenSigSNA" SG_ 54 SumTrqStatic_SEM "1FFFh";
BA_ "GenSigCycleTime" SG_ 54 SumTrqStatic_SEM 10;
BA_ "FlexKomSigStartValue" SG_ 54 SumTrqStatic_SEM "1FFF1FFF1FFF00FFh";
BA_ "FlexKomSigStartPos" SG_ 54 SumTrqStatic_SEM 7;
BA_ "FlexKomSigName" SG_ 54 SumTrqStatic_SEM "HCP_A2_PKT";
BA_ "FlexKomSigLaenge" SG_ 54 SumTrqStatic_SEM 64;
BA_ "FlexKomSID" SG_ 54 SumTrqStatic_SEM 2994;
BA_ "FlexKomIsMotorola" SG_ 54 SumTrqStatic_SEM 1;
BA_ "FlexKomComment" SG_ 54 SumTrqStatic_SEM "HCP_A2_PKT";
BA_ "GenSigStartValue" SG_ 54 SumTrqTgt_SEM 8191;
BA_ "GenSigSNA" SG_ 54 SumTrqTgt_SEM "1FFFh";
BA_ "GenSigCycleTime" SG_ 54 SumTrqTgt_SEM 10;
BA_ "FlexKomSigStartValue" SG_ 54 SumTrqTgt_SEM "1FFF1FFF1FFF00FFh";
BA_ "FlexKomSigStartPos" SG_ 54 SumTrqTgt_SEM 7;
BA_ "FlexKomSigName" SG_ 54 SumTrqTgt_SEM "HCP_A2_PKT";
BA_ "FlexKomSigLaenge" SG_ 54 SumTrqTgt_SEM 64;
BA_ "FlexKomSID" SG_ 54 SumTrqTgt_SEM 2994;
BA_ "FlexKomIsMotorola" SG_ 54 SumTrqTgt_SEM 1;
BA_ "FlexKomComment" SG_ 54 SumTrqTgt_SEM "HCP_A2_PKT";
BA_ "GenSigStartValue" SG_ 56 CRC_HCP_A3 255;
BA_ "GenSigSNA" SG_ 56 CRC_HCP_A3 "FFh";
BA_ "GenSigCycleTime" SG_ 56 CRC_HCP_A3 10;
BA_ "FlexKomSigStartValue" SG_ 56 CRC_HCP_A3 "1FFF1FFFFFFE00FFh";
BA_ "FlexKomSigStartPos" SG_ 56 CRC_HCP_A3 7;
BA_ "FlexKomSigName" SG_ 56 CRC_HCP_A3 "HCP_A3_PKT";
BA_ "FlexKomSigLaenge" SG_ 56 CRC_HCP_A3 64;
BA_ "FlexKomSID" SG_ 56 CRC_HCP_A3 2995;
BA_ "FlexKomIsMotorola" SG_ 56 CRC_HCP_A3 1;
BA_ "FlexKomComment" SG_ 56 CRC_HCP_A3 "HCP_A3_PKT";
BA_ "GenSigSNA" SG_ 56 MC_HCP_A3 "0h";
BA_ "GenSigCycleTime" SG_ 56 MC_HCP_A3 10;
BA_ "FlexKomSigStartValue" SG_ 56 MC_HCP_A3 "1FFF1FFFFFFE00FFh";
BA_ "FlexKomSigStartPos" SG_ 56 MC_HCP_A3 7;
BA_ "FlexKomSigName" SG_ 56 MC_HCP_A3 "HCP_A3_PKT";
BA_ "FlexKomSigLaenge" SG_ 56 MC_HCP_A3 64;
BA_ "FlexKomSID" SG_ 56 MC_HCP_A3 2995;
BA_ "FlexKomIsMotorola" SG_ 56 MC_HCP_A3 1;
BA_ "FlexKomComment" SG_ 56 MC_HCP_A3 "HCP_A3_PKT";
BA_ "GenSigTimeout_TPM" SG_ 56 MotorB_Speed 105;
BA_ "GenSigTimeout_TCM" SG_ 56 MotorB_Speed 105;
BA_ "GenSigTimeout_ORC" SG_ 56 MotorB_Speed 35;
BA_ "GenSigTimeout_IC" SG_ 56 MotorB_Speed 105;
BA_ "GenSigTimeout_ESM" SG_ 56 MotorB_Speed 105;
BA_ "GenSigTimeout_EHPS" SG_ 56 MotorB_Speed 105;
BA_ "GenSigTimeout_DTCM" SG_ 56 MotorB_Speed 105;
BA_ "GenSigTimeout_CBC" SG_ 56 MotorB_Speed 105;
BA_ "GenSigStartValue" SG_ 56 MotorB_Speed 65534;
BA_ "GenSigSNA" SG_ 56 MotorB_Speed "FFFFh";
BA_ "GenSigCycleTime" SG_ 56 MotorB_Speed 10;
BA_ "FlexKomSigStartValue" SG_ 56 MotorB_Speed "1FFF1FFFFFFE00FFh";
BA_ "FlexKomSigStartPos" SG_ 56 MotorB_Speed 7;
BA_ "FlexKomSigName" SG_ 56 MotorB_Speed "HCP_A3_PKT";
BA_ "FlexKomSigLaenge" SG_ 56 MotorB_Speed 64;
BA_ "FlexKomSID" SG_ 56 MotorB_Speed 2995;
BA_ "FlexKomIsMotorola" SG_ 56 MotorB_Speed 1;
BA_ "FlexKomComment" SG_ 56 MotorB_Speed "HCP_A3_PKT";
BA_ "GenSigTimeout_TCM" SG_ 56 SumTrqSel_D_TTC 210;
BA_ "GenSigTimeout_DTCM" SG_ 56 SumTrqSel_D_TTC 210;
BA_ "GenSigStartValue" SG_ 56 SumTrqSel_D_TTC 8191;
BA_ "GenSigSNA" SG_ 56 SumTrqSel_D_TTC "1FFFh";
BA_ "GenSigCycleTime" SG_ 56 SumTrqSel_D_TTC 10;
BA_ "FlexKomSigStartValue" SG_ 56 SumTrqSel_D_TTC "1FFF1FFFFFFE00FFh";
BA_ "FlexKomSigStartPos" SG_ 56 SumTrqSel_D_TTC 7;
BA_ "FlexKomSigName" SG_ 56 SumTrqSel_D_TTC "HCP_A3_PKT";
BA_ "FlexKomSigLaenge" SG_ 56 SumTrqSel_D_TTC 64;
BA_ "FlexKomSID" SG_ 56 SumTrqSel_D_TTC 2995;
BA_ "FlexKomIsMotorola" SG_ 56 SumTrqSel_D_TTC 1;
BA_ "FlexKomComment" SG_ 56 SumTrqSel_D_TTC "HCP_A3_PKT";
BA_ "GenSigTimeout_DTCM" SG_ 56 SumTrq_DrvReqMod 210;
BA_ "GenSigStartValue" SG_ 56 SumTrq_DrvReqMod 8191;
BA_ "GenSigSNA" SG_ 56 SumTrq_DrvReqMod "1FFFh";
BA_ "GenSigCycleTime" SG_ 56 SumTrq_DrvReqMod 10;
BA_ "FlexKomSigStartValue" SG_ 56 SumTrq_DrvReqMod "1FFF1FFFFFFE00FFh";
BA_ "FlexKomSigStartPos" SG_ 56 SumTrq_DrvReqMod 7;
BA_ "FlexKomSigName" SG_ 56 SumTrq_DrvReqMod "HCP_A3_PKT";
BA_ "FlexKomSigLaenge" SG_ 56 SumTrq_DrvReqMod 64;
BA_ "FlexKomSID" SG_ 56 SumTrq_DrvReqMod 2995;
BA_ "FlexKomIsMotorola" SG_ 56 SumTrq_DrvReqMod 1;
BA_ "FlexKomComment" SG_ 56 SumTrq_DrvReqMod "HCP_A3_PKT";
BA_ "GenSigStartValue" SG_ 315 CRC_HCP_C1 255;
BA_ "GenSigSNA" SG_ 315 CRC_HCP_C1 "FFh";
BA_ "GenSigCycleTime" SG_ 315 CRC_HCP_C1 100;
BA_ "FlexKomSigStartValue" SG_ 315 CRC_HCP_C1 "00000000646400FFh";
BA_ "FlexKomSigStartPos" SG_ 315 CRC_HCP_C1 7;
BA_ "FlexKomSigName" SG_ 315 CRC_HCP_C1 "HCP_C1_Pkt";
BA_ "FlexKomSigLaenge" SG_ 315 CRC_HCP_C1 64;
BA_ "FlexKomSID" SG_ 315 CRC_HCP_C1 2374;
BA_ "FlexKomIsMotorola" SG_ 315 CRC_HCP_C1 1;
BA_ "FlexKomComment" SG_ 315 CRC_HCP_C1 "HCP_C1_Pkt message packet";
BA_ "GenSigTimeout_IC" SG_ 315 DriveMdstat 1050;
BA_ "GenSigTimeout_CBC" SG_ 315 DriveMdstat 1050;
BA_ "GenSigSNA" SG_ 315 DriveMdstat "Fh";
BA_ "GenSigCycleTime" SG_ 315 DriveMdstat 100;
BA_ "FlexKomSigStartValue" SG_ 315 DriveMdstat "00000000646400FFh";
BA_ "FlexKomSigStartPos" SG_ 315 DriveMdstat 7;
BA_ "FlexKomSigName" SG_ 315 DriveMdstat "HCP_C1_Pkt";
BA_ "FlexKomSigLaenge" SG_ 315 DriveMdstat 64;
BA_ "FlexKomSID" SG_ 315 DriveMdstat 2374;
BA_ "FlexKomIsMotorola" SG_ 315 DriveMdstat 1;
BA_ "FlexKomComment" SG_ 315 DriveMdstat "HCP_C1_Pkt message packet";
BA_ "GenSigTimeout_IC" SG_ 315 DrvMode_PopUpRqst 1050;
BA_ "GenSigTimeout_CBC" SG_ 315 DrvMode_PopUpRqst 1050;
BA_ "GenSigSNA" SG_ 315 DrvMode_PopUpRqst "Fh";
BA_ "GenSigCycleTime" SG_ 315 DrvMode_PopUpRqst 100;
BA_ "FlexKomSigStartValue" SG_ 315 DrvMode_PopUpRqst "00000000646400FFh";
BA_ "FlexKomSigStartPos" SG_ 315 DrvMode_PopUpRqst 7;
BA_ "FlexKomSigName" SG_ 315 DrvMode_PopUpRqst "HCP_C1_Pkt";
BA_ "FlexKomSigLaenge" SG_ 315 DrvMode_PopUpRqst 64;
BA_ "FlexKomSID" SG_ 315 DrvMode_PopUpRqst 2374;
BA_ "FlexKomIsMotorola" SG_ 315 DrvMode_PopUpRqst 1;
BA_ "FlexKomComment" SG_ 315 DrvMode_PopUpRqst "HCP_C1_Pkt message packet";
BA_ "GenSigSNA" SG_ 315 GrShiftIndication "3h";
BA_ "GenSigCycleTime" SG_ 315 GrShiftIndication 100;
BA_ "FlexKomSigStartValue" SG_ 315 GrShiftIndication "00000000646400FFh";
BA_ "FlexKomSigStartPos" SG_ 315 GrShiftIndication 7;
BA_ "FlexKomSigName" SG_ 315 GrShiftIndication "HCP_C1_Pkt";
BA_ "FlexKomSigLaenge" SG_ 315 GrShiftIndication 64;
BA_ "FlexKomSID" SG_ 315 GrShiftIndication 2374;
BA_ "FlexKomIsMotorola" SG_ 315 GrShiftIndication 1;
BA_ "FlexKomComment" SG_ 315 GrShiftIndication "HCP_C1_Pkt message packet";
BA_ "GenSigTimeout_IC" SG_ 315 HCPCoachDisp 1050;
BA_ "GenSigStartValue" SG_ 315 HCPCoachDisp 100;
BA_ "GenSigSNA" SG_ 315 HCPCoachDisp "64h";
BA_ "GenSigCycleTime" SG_ 315 HCPCoachDisp 100;
BA_ "FlexKomSigStartValue" SG_ 315 HCPCoachDisp "00000000646400FFh";
BA_ "FlexKomSigStartPos" SG_ 315 HCPCoachDisp 7;
BA_ "FlexKomSigName" SG_ 315 HCPCoachDisp "HCP_C1_Pkt";
BA_ "FlexKomSigLaenge" SG_ 315 HCPCoachDisp 64;
BA_ "FlexKomSID" SG_ 315 HCPCoachDisp 2374;
BA_ "FlexKomIsMotorola" SG_ 315 HCPCoachDisp 1;
BA_ "FlexKomComment" SG_ 315 HCPCoachDisp "HCP_C1_Pkt message packet";
BA_ "GenSigTimeout_IC" SG_ 315 HCPCoachDispV 1050;
BA_ "GenSigSNA" SG_ 315 HCPCoachDispV "0h";
BA_ "GenSigCycleTime" SG_ 315 HCPCoachDispV 100;
BA_ "FlexKomSigStartValue" SG_ 315 HCPCoachDispV "00000000646400FFh";
BA_ "FlexKomSigStartPos" SG_ 315 HCPCoachDispV 7;
BA_ "FlexKomSigName" SG_ 315 HCPCoachDispV "HCP_C1_Pkt";
BA_ "FlexKomSigLaenge" SG_ 315 HCPCoachDispV 64;
BA_ "FlexKomSID" SG_ 315 HCPCoachDispV 2374;
BA_ "FlexKomIsMotorola" SG_ 315 HCPCoachDispV 1;
BA_ "FlexKomComment" SG_ 315 HCPCoachDispV "HCP_C1_Pkt message packet";
BA_ "GenSigTimeout_IC" SG_ 315 HCPOutputPwr 1050;
BA_ "GenSigStartValue" SG_ 315 HCPOutputPwr 100;
BA_ "GenSigSNA" SG_ 315 HCPOutputPwr "64h";
BA_ "GenSigCycleTime" SG_ 315 HCPOutputPwr 100;
BA_ "FlexKomSigStartValue" SG_ 315 HCPOutputPwr "00000000646400FFh";
BA_ "FlexKomSigStartPos" SG_ 315 HCPOutputPwr 7;
BA_ "FlexKomSigName" SG_ 315 HCPOutputPwr "HCP_C1_Pkt";
BA_ "FlexKomSigLaenge" SG_ 315 HCPOutputPwr 64;
BA_ "FlexKomSID" SG_ 315 HCPOutputPwr 2374;
BA_ "FlexKomIsMotorola" SG_ 315 HCPOutputPwr 1;
BA_ "FlexKomComment" SG_ 315 HCPOutputPwr "HCP_C1_Pkt message packet";
BA_ "GenSigTimeout_IC" SG_ 315 HCPOutputPwrV 1050;
BA_ "GenSigSNA" SG_ 315 HCPOutputPwrV "0h";
BA_ "GenSigCycleTime" SG_ 315 HCPOutputPwrV 100;
BA_ "FlexKomSigStartValue" SG_ 315 HCPOutputPwrV "00000000646400FFh";
BA_ "FlexKomSigStartPos" SG_ 315 HCPOutputPwrV 7;
BA_ "FlexKomSigName" SG_ 315 HCPOutputPwrV "HCP_C1_Pkt";
BA_ "FlexKomSigLaenge" SG_ 315 HCPOutputPwrV 64;
BA_ "FlexKomSID" SG_ 315 HCPOutputPwrV 2374;
BA_ "FlexKomIsMotorola" SG_ 315 HCPOutputPwrV 1;
BA_ "FlexKomComment" SG_ 315 HCPOutputPwrV "HCP_C1_Pkt message packet";
BA_ "GenSigTimeout_IC" SG_ 315 HCPPopUpMessage1 1050;
BA_ "GenSigSNA" SG_ 315 HCPPopUpMessage1 "0h";
BA_ "GenSigCycleTime" SG_ 315 HCPPopUpMessage1 100;
BA_ "FlexKomSigStartValue" SG_ 315 HCPPopUpMessage1 "00000000646400FFh";
BA_ "FlexKomSigStartPos" SG_ 315 HCPPopUpMessage1 7;
BA_ "FlexKomSigName" SG_ 315 HCPPopUpMessage1 "HCP_C1_Pkt";
BA_ "FlexKomSigLaenge" SG_ 315 HCPPopUpMessage1 64;
BA_ "FlexKomSID" SG_ 315 HCPPopUpMessage1 2374;
BA_ "FlexKomIsMotorola" SG_ 315 HCPPopUpMessage1 1;
BA_ "FlexKomComment" SG_ 315 HCPPopUpMessage1 "HCP_C1_Pkt message packet";
BA_ "GenSigTimeout_IC" SG_ 315 HCPPopUpMessage10 1050;
BA_ "GenSigSNA" SG_ 315 HCPPopUpMessage10 "0h";
BA_ "GenSigCycleTime" SG_ 315 HCPPopUpMessage10 100;
BA_ "FlexKomSigStartValue" SG_ 315 HCPPopUpMessage10 "00000000646400FFh";
BA_ "FlexKomSigStartPos" SG_ 315 HCPPopUpMessage10 7;
BA_ "FlexKomSigName" SG_ 315 HCPPopUpMessage10 "HCP_C1_Pkt";
BA_ "FlexKomSigLaenge" SG_ 315 HCPPopUpMessage10 64;
BA_ "FlexKomSID" SG_ 315 HCPPopUpMessage10 2374;
BA_ "FlexKomIsMotorola" SG_ 315 HCPPopUpMessage10 1;
BA_ "FlexKomComment" SG_ 315 HCPPopUpMessage10 "HCP_C1_Pkt message packet";
BA_ "GenSigTimeout_IC" SG_ 315 HCPPopUpMessage12 1050;
BA_ "GenSigSNA" SG_ 315 HCPPopUpMessage12 "0h";
BA_ "GenSigCycleTime" SG_ 315 HCPPopUpMessage12 100;
BA_ "FlexKomSigStartValue" SG_ 315 HCPPopUpMessage12 "00000000646400FFh";
BA_ "FlexKomSigStartPos" SG_ 315 HCPPopUpMessage12 7;
BA_ "FlexKomSigName" SG_ 315 HCPPopUpMessage12 "HCP_C1_Pkt";
BA_ "FlexKomSigLaenge" SG_ 315 HCPPopUpMessage12 64;
BA_ "FlexKomSID" SG_ 315 HCPPopUpMessage12 2374;
BA_ "FlexKomIsMotorola" SG_ 315 HCPPopUpMessage12 1;
BA_ "FlexKomComment" SG_ 315 HCPPopUpMessage12 "HCP_C1_Pkt message packet";
BA_ "GenSigTimeout_IC" SG_ 315 HCPPopUpMessage2 1050;
BA_ "GenSigSNA" SG_ 315 HCPPopUpMessage2 "0h";
BA_ "GenSigCycleTime" SG_ 315 HCPPopUpMessage2 100;
BA_ "FlexKomSigStartValue" SG_ 315 HCPPopUpMessage2 "00000000646400FFh";
BA_ "FlexKomSigStartPos" SG_ 315 HCPPopUpMessage2 7;
BA_ "FlexKomSigName" SG_ 315 HCPPopUpMessage2 "HCP_C1_Pkt";
BA_ "FlexKomSigLaenge" SG_ 315 HCPPopUpMessage2 64;
BA_ "FlexKomSID" SG_ 315 HCPPopUpMessage2 2374;
BA_ "FlexKomIsMotorola" SG_ 315 HCPPopUpMessage2 1;
BA_ "FlexKomComment" SG_ 315 HCPPopUpMessage2 "HCP_C1_Pkt message packet";
BA_ "GenSigTimeout_IC" SG_ 315 HCPPopUpMessage3 1050;
BA_ "GenSigSNA" SG_ 315 HCPPopUpMessage3 "0h";
BA_ "GenSigCycleTime" SG_ 315 HCPPopUpMessage3 100;
BA_ "FlexKomSigStartValue" SG_ 315 HCPPopUpMessage3 "00000000646400FFh";
BA_ "FlexKomSigStartPos" SG_ 315 HCPPopUpMessage3 7;
BA_ "FlexKomSigName" SG_ 315 HCPPopUpMessage3 "HCP_C1_Pkt";
BA_ "FlexKomSigLaenge" SG_ 315 HCPPopUpMessage3 64;
BA_ "FlexKomSID" SG_ 315 HCPPopUpMessage3 2374;
BA_ "FlexKomIsMotorola" SG_ 315 HCPPopUpMessage3 1;
BA_ "FlexKomComment" SG_ 315 HCPPopUpMessage3 "HCP_C1_Pkt message packet";
BA_ "GenSigTimeout_IC" SG_ 315 HCPPopUpMessage4 1050;
BA_ "GenSigSNA" SG_ 315 HCPPopUpMessage4 "0h";
BA_ "GenSigCycleTime" SG_ 315 HCPPopUpMessage4 100;
BA_ "FlexKomSigStartValue" SG_ 315 HCPPopUpMessage4 "00000000646400FFh";
BA_ "FlexKomSigStartPos" SG_ 315 HCPPopUpMessage4 7;
BA_ "FlexKomSigName" SG_ 315 HCPPopUpMessage4 "HCP_C1_Pkt";
BA_ "FlexKomSigLaenge" SG_ 315 HCPPopUpMessage4 64;
BA_ "FlexKomSID" SG_ 315 HCPPopUpMessage4 2374;
BA_ "FlexKomIsMotorola" SG_ 315 HCPPopUpMessage4 1;
BA_ "FlexKomComment" SG_ 315 HCPPopUpMessage4 "HCP_C1_Pkt message packet";
BA_ "GenSigTimeout_IC" SG_ 315 HCPPopUpMessage5 1050;
BA_ "GenSigSNA" SG_ 315 HCPPopUpMessage5 "0h";
BA_ "GenSigCycleTime" SG_ 315 HCPPopUpMessage5 100;
BA_ "FlexKomSigStartValue" SG_ 315 HCPPopUpMessage5 "00000000646400FFh";
BA_ "FlexKomSigStartPos" SG_ 315 HCPPopUpMessage5 7;
BA_ "FlexKomSigName" SG_ 315 HCPPopUpMessage5 "HCP_C1_Pkt";
BA_ "FlexKomSigLaenge" SG_ 315 HCPPopUpMessage5 64;
BA_ "FlexKomSID" SG_ 315 HCPPopUpMessage5 2374;
BA_ "FlexKomIsMotorola" SG_ 315 HCPPopUpMessage5 1;
BA_ "FlexKomComment" SG_ 315 HCPPopUpMessage5 "HCP_C1_Pkt message packet";
BA_ "GenSigTimeout_IC" SG_ 315 HCPPopUpMessage6 1050;
BA_ "GenSigSNA" SG_ 315 HCPPopUpMessage6 "0h";
BA_ "GenSigCycleTime" SG_ 315 HCPPopUpMessage6 100;
BA_ "FlexKomSigStartValue" SG_ 315 HCPPopUpMessage6 "00000000646400FFh";
BA_ "FlexKomSigStartPos" SG_ 315 HCPPopUpMessage6 7;
BA_ "FlexKomSigName" SG_ 315 HCPPopUpMessage6 "HCP_C1_Pkt";
BA_ "FlexKomSigLaenge" SG_ 315 HCPPopUpMessage6 64;
BA_ "FlexKomSID" SG_ 315 HCPPopUpMessage6 2374;
BA_ "FlexKomIsMotorola" SG_ 315 HCPPopUpMessage6 1;
BA_ "FlexKomComment" SG_ 315 HCPPopUpMessage6 "HCP_C1_Pkt message packet";
BA_ "GenSigTimeout_IC" SG_ 315 HCPPopUpMessage7 1050;
BA_ "GenSigSNA" SG_ 315 HCPPopUpMessage7 "0h";
BA_ "GenSigCycleTime" SG_ 315 HCPPopUpMessage7 100;
BA_ "FlexKomSigStartValue" SG_ 315 HCPPopUpMessage7 "00000000646400FFh";
BA_ "FlexKomSigStartPos" SG_ 315 HCPPopUpMessage7 7;
BA_ "FlexKomSigName" SG_ 315 HCPPopUpMessage7 "HCP_C1_Pkt";
BA_ "FlexKomSigLaenge" SG_ 315 HCPPopUpMessage7 64;
BA_ "FlexKomSID" SG_ 315 HCPPopUpMessage7 2374;
BA_ "FlexKomIsMotorola" SG_ 315 HCPPopUpMessage7 1;
BA_ "FlexKomComment" SG_ 315 HCPPopUpMessage7 "HCP_C1_Pkt message packet";
BA_ "GenSigTimeout_IC" SG_ 315 HCPPopUpMessage8 1050;
BA_ "GenSigSNA" SG_ 315 HCPPopUpMessage8 "0h";
BA_ "GenSigCycleTime" SG_ 315 HCPPopUpMessage8 100;
BA_ "FlexKomSigStartValue" SG_ 315 HCPPopUpMessage8 "00000000646400FFh";
BA_ "FlexKomSigStartPos" SG_ 315 HCPPopUpMessage8 7;
BA_ "FlexKomSigName" SG_ 315 HCPPopUpMessage8 "HCP_C1_Pkt";
BA_ "FlexKomSigLaenge" SG_ 315 HCPPopUpMessage8 64;
BA_ "FlexKomSID" SG_ 315 HCPPopUpMessage8 2374;
BA_ "FlexKomIsMotorola" SG_ 315 HCPPopUpMessage8 1;
BA_ "FlexKomComment" SG_ 315 HCPPopUpMessage8 "HCP_C1_Pkt message packet";
BA_ "GenSigTimeout_IC" SG_ 315 HCPPopUpMessage9 1050;
BA_ "GenSigSNA" SG_ 315 HCPPopUpMessage9 "0h";
BA_ "GenSigCycleTime" SG_ 315 HCPPopUpMessage9 100;
BA_ "FlexKomSigStartValue" SG_ 315 HCPPopUpMessage9 "00000000646400FFh";
BA_ "FlexKomSigStartPos" SG_ 315 HCPPopUpMessage9 7;
BA_ "FlexKomSigName" SG_ 315 HCPPopUpMessage9 "HCP_C1_Pkt";
BA_ "FlexKomSigLaenge" SG_ 315 HCPPopUpMessage9 64;
BA_ "FlexKomSID" SG_ 315 HCPPopUpMessage9 2374;
BA_ "FlexKomIsMotorola" SG_ 315 HCPPopUpMessage9 1;
BA_ "FlexKomComment" SG_ 315 HCPPopUpMessage9 "HCP_C1_Pkt message packet";
BA_ "GenSigSNA" SG_ 315 HybSysEmsMlfAtv "0h";
BA_ "GenSigCycleTime" SG_ 315 HybSysEmsMlfAtv 100;
BA_ "FlexKomSigStartValue" SG_ 315 HybSysEmsMlfAtv "00000000646400FFh";
BA_ "FlexKomSigStartPos" SG_ 315 HybSysEmsMlfAtv 7;
BA_ "FlexKomSigName" SG_ 315 HybSysEmsMlfAtv "HCP_C1_Pkt";
BA_ "FlexKomSigLaenge" SG_ 315 HybSysEmsMlfAtv 64;
BA_ "FlexKomSID" SG_ 315 HybSysEmsMlfAtv 2374;
BA_ "FlexKomIsMotorola" SG_ 315 HybSysEmsMlfAtv 1;
BA_ "FlexKomComment" SG_ 315 HybSysEmsMlfAtv "HCP_C1_Pkt message packet";
BA_ "GenSigSNA" SG_ 315 MC_HCP_C1 "0h";
BA_ "GenSigCycleTime" SG_ 315 MC_HCP_C1 100;
BA_ "FlexKomSigStartValue" SG_ 315 MC_HCP_C1 "00000000646400FFh";
BA_ "FlexKomSigStartPos" SG_ 315 MC_HCP_C1 7;
BA_ "FlexKomSigName" SG_ 315 MC_HCP_C1 "HCP_C1_Pkt";
BA_ "FlexKomSigLaenge" SG_ 315 MC_HCP_C1 64;
BA_ "FlexKomSID" SG_ 315 MC_HCP_C1 2374;
BA_ "FlexKomIsMotorola" SG_ 315 MC_HCP_C1 1;
BA_ "FlexKomComment" SG_ 315 MC_HCP_C1 "HCP_C1_Pkt message packet";
BA_ "GenSigSNA" SG_ 315 MIL_OnRq_HCP "0h";
BA_ "GenSigCycleTime" SG_ 315 MIL_OnRq_HCP 100;
BA_ "FlexKomSigStartValue" SG_ 315 MIL_OnRq_HCP "00000000646400FFh";
BA_ "FlexKomSigStartPos" SG_ 315 MIL_OnRq_HCP 7;
BA_ "FlexKomSigName" SG_ 315 MIL_OnRq_HCP "HCP_C1_Pkt";
BA_ "FlexKomSigLaenge" SG_ 315 MIL_OnRq_HCP 64;
BA_ "FlexKomSID" SG_ 315 MIL_OnRq_HCP 2374;
BA_ "FlexKomIsMotorola" SG_ 315 MIL_OnRq_HCP 1;
BA_ "FlexKomComment" SG_ 315 MIL_OnRq_HCP "HCP_C1_Pkt message packet";
BA_ "GenSigSNA" SG_ 315 MaxRegenTelltale "0h";
BA_ "GenSigCycleTime" SG_ 315 MaxRegenTelltale 100;
BA_ "FlexKomSigStartValue" SG_ 315 MaxRegenTelltale "00000000646400FFh";
BA_ "FlexKomSigStartPos" SG_ 315 MaxRegenTelltale 7;
BA_ "FlexKomSigName" SG_ 315 MaxRegenTelltale "HCP_C1_Pkt";
BA_ "FlexKomSigLaenge" SG_ 315 MaxRegenTelltale 64;
BA_ "FlexKomSID" SG_ 315 MaxRegenTelltale 2374;
BA_ "FlexKomIsMotorola" SG_ 315 MaxRegenTelltale 1;
BA_ "FlexKomComment" SG_ 315 MaxRegenTelltale "HCP_C1_Pkt message packet";
BA_ "GenSigSNA" SG_ 315 P1fFailedUseBumpStartHMI "0h";
BA_ "GenSigCycleTime" SG_ 315 P1fFailedUseBumpStartHMI 100;
BA_ "FlexKomSigStartValue" SG_ 315 P1fFailedUseBumpStartHMI "00000000646400FFh";
BA_ "FlexKomSigStartPos" SG_ 315 P1fFailedUseBumpStartHMI 7;
BA_ "FlexKomSigName" SG_ 315 P1fFailedUseBumpStartHMI "HCP_C1_Pkt";
BA_ "FlexKomSigLaenge" SG_ 315 P1fFailedUseBumpStartHMI 64;
BA_ "FlexKomSID" SG_ 315 P1fFailedUseBumpStartHMI 2374;
BA_ "FlexKomIsMotorola" SG_ 315 P1fFailedUseBumpStartHMI 1;
BA_ "FlexKomComment" SG_ 315 P1fFailedUseBumpStartHMI "HCP_C1_Pkt message packet";
BA_ "RID" SG_ 505 BatPwrUsageDisp "6520";
BA_ "GenSigTimeout_CBC" SG_ 505 BatPwrUsageDisp 10500;
BA_ "GenSigSNA" SG_ 505 BatPwrUsageDisp "0h";
BA_ "GenSigCycleTime" SG_ 505 BatPwrUsageDisp 500;
BA_ "FlexKomSigStartValue" SG_ 505 BatPwrUsageDisp "0000000000000000h";
BA_ "FlexKomSigStartPos" SG_ 505 BatPwrUsageDisp 7;
BA_ "FlexKomSigName" SG_ 505 BatPwrUsageDisp "HCP_DISP";
BA_ "FlexKomSigLaenge" SG_ 505 BatPwrUsageDisp 64;
BA_ "FlexKomSID" SG_ 505 BatPwrUsageDisp 2549;
BA_ "FlexKomIsMotorola" SG_ 505 BatPwrUsageDisp 1;
BA_ "FlexKomComment" SG_ 505 BatPwrUsageDisp "HCP Info for Display";
BA_ "RID" SG_ 505 BatPwrUsageDisp_V "6509";
BA_ "GenSigTimeout_CBC" SG_ 505 BatPwrUsageDisp_V 10500;
BA_ "GenSigSNA" SG_ 505 BatPwrUsageDisp_V "0h";
BA_ "GenSigCycleTime" SG_ 505 BatPwrUsageDisp_V 500;
BA_ "FlexKomSigStartValue" SG_ 505 BatPwrUsageDisp_V "0000000000000000h";
BA_ "FlexKomSigStartPos" SG_ 505 BatPwrUsageDisp_V 7;
BA_ "FlexKomSigName" SG_ 505 BatPwrUsageDisp_V "HCP_DISP";
BA_ "FlexKomSigLaenge" SG_ 505 BatPwrUsageDisp_V 64;
BA_ "FlexKomSID" SG_ 505 BatPwrUsageDisp_V 2549;
BA_ "FlexKomIsMotorola" SG_ 505 BatPwrUsageDisp_V 1;
BA_ "FlexKomComment" SG_ 505 BatPwrUsageDisp_V "HCP Info for Display";
BA_ "RID" SG_ 505 EngPwrUsageDisp "6506";
BA_ "GenSigTimeout_CBC" SG_ 505 EngPwrUsageDisp 10500;
BA_ "GenSigSNA" SG_ 505 EngPwrUsageDisp "0h";
BA_ "GenSigCycleTime" SG_ 505 EngPwrUsageDisp 500;
BA_ "FlexKomSigStartValue" SG_ 505 EngPwrUsageDisp "0000000000000000h";
BA_ "FlexKomSigStartPos" SG_ 505 EngPwrUsageDisp 7;
BA_ "FlexKomSigName" SG_ 505 EngPwrUsageDisp "HCP_DISP";
BA_ "FlexKomSigLaenge" SG_ 505 EngPwrUsageDisp 64;
BA_ "FlexKomSID" SG_ 505 EngPwrUsageDisp 2549;
BA_ "FlexKomIsMotorola" SG_ 505 EngPwrUsageDisp 1;
BA_ "FlexKomComment" SG_ 505 EngPwrUsageDisp "HCP Info for Display";
BA_ "RID" SG_ 505 EngPwrUsageDisp_V "6512";
BA_ "GenSigTimeout_CBC" SG_ 505 EngPwrUsageDisp_V 10500;
BA_ "GenSigSNA" SG_ 505 EngPwrUsageDisp_V "0h";
BA_ "GenSigCycleTime" SG_ 505 EngPwrUsageDisp_V 500;
BA_ "FlexKomSigStartValue" SG_ 505 EngPwrUsageDisp_V "0000000000000000h";
BA_ "FlexKomSigStartPos" SG_ 505 EngPwrUsageDisp_V 7;
BA_ "FlexKomSigName" SG_ 505 EngPwrUsageDisp_V "HCP_DISP";
BA_ "FlexKomSigLaenge" SG_ 505 EngPwrUsageDisp_V 64;
BA_ "FlexKomSID" SG_ 505 EngPwrUsageDisp_V 2549;
BA_ "FlexKomIsMotorola" SG_ 505 EngPwrUsageDisp_V 1;
BA_ "FlexKomComment" SG_ 505 EngPwrUsageDisp_V "HCP Info for Display";
BA_ "RID" SG_ 505 HVACPwrUsageDisp "6516";
BA_ "GenSigTimeout_CBC" SG_ 505 HVACPwrUsageDisp 10500;
BA_ "GenSigSNA" SG_ 505 HVACPwrUsageDisp "0h";
BA_ "GenSigCycleTime" SG_ 505 HVACPwrUsageDisp 500;
BA_ "FlexKomSigStartValue" SG_ 505 HVACPwrUsageDisp "0000000000000000h";
BA_ "FlexKomSigStartPos" SG_ 505 HVACPwrUsageDisp 7;
BA_ "FlexKomSigName" SG_ 505 HVACPwrUsageDisp "HCP_DISP";
BA_ "FlexKomSigLaenge" SG_ 505 HVACPwrUsageDisp 64;
BA_ "FlexKomSID" SG_ 505 HVACPwrUsageDisp 2549;
BA_ "FlexKomIsMotorola" SG_ 505 HVACPwrUsageDisp 1;
BA_ "FlexKomComment" SG_ 505 HVACPwrUsageDisp "HCP Info for Display";
BA_ "RID" SG_ 505 HVACPwrUsageDisp_V "6513";
BA_ "GenSigTimeout_CBC" SG_ 505 HVACPwrUsageDisp_V 10500;
BA_ "GenSigSNA" SG_ 505 HVACPwrUsageDisp_V "0h";
BA_ "GenSigCycleTime" SG_ 505 HVACPwrUsageDisp_V 500;
BA_ "FlexKomSigStartValue" SG_ 505 HVACPwrUsageDisp_V "0000000000000000h";
BA_ "FlexKomSigStartPos" SG_ 505 HVACPwrUsageDisp_V 7;
BA_ "FlexKomSigName" SG_ 505 HVACPwrUsageDisp_V "HCP_DISP";
BA_ "FlexKomSigLaenge" SG_ 505 HVACPwrUsageDisp_V 64;
BA_ "FlexKomSID" SG_ 505 HVACPwrUsageDisp_V 2549;
BA_ "FlexKomIsMotorola" SG_ 505 HVACPwrUsageDisp_V 1;
BA_ "FlexKomComment" SG_ 505 HVACPwrUsageDisp_V "HCP Info for Display";
BA_ "RID" SG_ 505 HVBatSOCV_HCP "6514";
BA_ "GenSigTimeout_CBC" SG_ 505 HVBatSOCV_HCP 10500;
BA_ "GenSigSNA" SG_ 505 HVBatSOCV_HCP "0h";
BA_ "GenSigCycleTime" SG_ 505 HVBatSOCV_HCP 500;
BA_ "FlexKomSigStartValue" SG_ 505 HVBatSOCV_HCP "0000000000000000h";
BA_ "FlexKomSigStartPos" SG_ 505 HVBatSOCV_HCP 7;
BA_ "FlexKomSigName" SG_ 505 HVBatSOCV_HCP "HCP_DISP";
BA_ "FlexKomSigLaenge" SG_ 505 HVBatSOCV_HCP 64;
BA_ "FlexKomSID" SG_ 505 HVBatSOCV_HCP 2549;
BA_ "FlexKomIsMotorola" SG_ 505 HVBatSOCV_HCP 1;
BA_ "FlexKomComment" SG_ 505 HVBatSOCV_HCP "HCP Info for Display";
BA_ "RID" SG_ 505 HVBatSOC_HCP "6519";
BA_ "GenSigTimeout_CBC" SG_ 505 HVBatSOC_HCP 10500;
BA_ "GenSigSNA" SG_ 505 HVBatSOC_HCP "0h";
BA_ "GenSigCycleTime" SG_ 505 HVBatSOC_HCP 500;
BA_ "FlexKomSigStartValue" SG_ 505 HVBatSOC_HCP "0000000000000000h";
BA_ "FlexKomSigStartPos" SG_ 505 HVBatSOC_HCP 7;
BA_ "FlexKomSigName" SG_ 505 HVBatSOC_HCP "HCP_DISP";
BA_ "FlexKomSigLaenge" SG_ 505 HVBatSOC_HCP 64;
BA_ "FlexKomSID" SG_ 505 HVBatSOC_HCP 2549;
BA_ "FlexKomIsMotorola" SG_ 505 HVBatSOC_HCP 1;
BA_ "FlexKomComment" SG_ 505 HVBatSOC_HCP "HCP Info for Display";
BA_ "RID" SG_ 505 MtrAPwrUsageDisp "6556";
BA_ "GenSigSNA" SG_ 505 MtrAPwrUsageDisp "0h";
BA_ "GenSigCycleTime" SG_ 505 MtrAPwrUsageDisp 500;
BA_ "FlexKomSigStartValue" SG_ 505 MtrAPwrUsageDisp "0000000000000000h";
BA_ "FlexKomSigStartPos" SG_ 505 MtrAPwrUsageDisp 7;
BA_ "FlexKomSigName" SG_ 505 MtrAPwrUsageDisp "HCP_DISP";
BA_ "FlexKomSigLaenge" SG_ 505 MtrAPwrUsageDisp 64;
BA_ "FlexKomSID" SG_ 505 MtrAPwrUsageDisp 2549;
BA_ "FlexKomIsMotorola" SG_ 505 MtrAPwrUsageDisp 1;
BA_ "FlexKomComment" SG_ 505 MtrAPwrUsageDisp "HCP Info for Display";
BA_ "RID" SG_ 505 MtrAPwrUsageDispV "6557";
BA_ "GenSigSNA" SG_ 505 MtrAPwrUsageDispV "0h";
BA_ "GenSigCycleTime" SG_ 505 MtrAPwrUsageDispV 500;
BA_ "FlexKomSigStartValue" SG_ 505 MtrAPwrUsageDispV "0000000000000000h";
BA_ "FlexKomSigStartPos" SG_ 505 MtrAPwrUsageDispV 7;
BA_ "FlexKomSigName" SG_ 505 MtrAPwrUsageDispV "HCP_DISP";
BA_ "FlexKomSigLaenge" SG_ 505 MtrAPwrUsageDispV 64;
BA_ "FlexKomSID" SG_ 505 MtrAPwrUsageDispV 2549;
BA_ "FlexKomIsMotorola" SG_ 505 MtrAPwrUsageDispV 1;
BA_ "FlexKomComment" SG_ 505 MtrAPwrUsageDispV "HCP Info for Display";
BA_ "RID" SG_ 505 MtrBPwrUsageDisp "6555";
BA_ "GenSigSNA" SG_ 505 MtrBPwrUsageDisp "0h";
BA_ "GenSigCycleTime" SG_ 505 MtrBPwrUsageDisp 500;
BA_ "FlexKomSigStartValue" SG_ 505 MtrBPwrUsageDisp "0000000000000000h";
BA_ "FlexKomSigStartPos" SG_ 505 MtrBPwrUsageDisp 7;
BA_ "FlexKomSigName" SG_ 505 MtrBPwrUsageDisp "HCP_DISP";
BA_ "FlexKomSigLaenge" SG_ 505 MtrBPwrUsageDisp 64;
BA_ "FlexKomSID" SG_ 505 MtrBPwrUsageDisp 2549;
BA_ "FlexKomIsMotorola" SG_ 505 MtrBPwrUsageDisp 1;
BA_ "FlexKomComment" SG_ 505 MtrBPwrUsageDisp "HCP Info for Display";
BA_ "RID" SG_ 505 MtrBPwrUsageDispV "6554";
BA_ "GenSigSNA" SG_ 505 MtrBPwrUsageDispV "0h";
BA_ "GenSigCycleTime" SG_ 505 MtrBPwrUsageDispV 500;
BA_ "FlexKomSigStartValue" SG_ 505 MtrBPwrUsageDispV "0000000000000000h";
BA_ "FlexKomSigStartPos" SG_ 505 MtrBPwrUsageDispV 7;
BA_ "FlexKomSigName" SG_ 505 MtrBPwrUsageDispV "HCP_DISP";
BA_ "FlexKomSigLaenge" SG_ 505 MtrBPwrUsageDispV 64;
BA_ "FlexKomSID" SG_ 505 MtrBPwrUsageDispV 2549;
BA_ "FlexKomIsMotorola" SG_ 505 MtrBPwrUsageDispV 1;
BA_ "FlexKomComment" SG_ 505 MtrBPwrUsageDispV "HCP Info for Display";
BA_ "GenSigSNA" SG_ 505 MtrPwrUsageDisp "0h";
BA_ "GenSigCycleTime" SG_ 505 MtrPwrUsageDisp 500;
BA_ "FlexKomSigStartValue" SG_ 505 MtrPwrUsageDisp "0000000000000000h";
BA_ "FlexKomSigStartPos" SG_ 505 MtrPwrUsageDisp 7;
BA_ "FlexKomSigName" SG_ 505 MtrPwrUsageDisp "HCP_DISP";
BA_ "FlexKomSigLaenge" SG_ 505 MtrPwrUsageDisp 64;
BA_ "FlexKomSID" SG_ 505 MtrPwrUsageDisp 2549;
BA_ "FlexKomIsMotorola" SG_ 505 MtrPwrUsageDisp 1;
BA_ "FlexKomComment" SG_ 505 MtrPwrUsageDisp "HCP Info for Display";
BA_ "GenSigSNA" SG_ 505 MtrPwrUsageDisp_V "0h";
BA_ "GenSigCycleTime" SG_ 505 MtrPwrUsageDisp_V 500;
BA_ "FlexKomSigStartValue" SG_ 505 MtrPwrUsageDisp_V "0000000000000000h";
BA_ "FlexKomSigStartPos" SG_ 505 MtrPwrUsageDisp_V 7;
BA_ "FlexKomSigName" SG_ 505 MtrPwrUsageDisp_V "HCP_DISP";
BA_ "FlexKomSigLaenge" SG_ 505 MtrPwrUsageDisp_V 64;
BA_ "FlexKomSID" SG_ 505 MtrPwrUsageDisp_V 2549;
BA_ "FlexKomIsMotorola" SG_ 505 MtrPwrUsageDisp_V 1;
BA_ "FlexKomComment" SG_ 505 MtrPwrUsageDisp_V "HCP Info for Display";
BA_ "RID" SG_ 796 Batt_CabinPriority1_Sts "6619";
BA_ "GenSigSNA" SG_ 796 Batt_CabinPriority1_Sts "0h";
BA_ "GenSigSendType" SG_ 796 Batt_CabinPriority1_Sts 5;
BA_ "GenSigCycleTime" SG_ 796 Batt_CabinPriority1_Sts 1000;
BA_ "FlexKomSigStartValue" SG_ 796 Batt_CabinPriority1_Sts "0000000000000000h";
BA_ "FlexKomSigStartPos" SG_ 796 Batt_CabinPriority1_Sts 7;
BA_ "FlexKomSigName" SG_ 796 Batt_CabinPriority1_Sts "HCP_Schedule1";
BA_ "FlexKomSigLaenge" SG_ 796 Batt_CabinPriority1_Sts 64;
BA_ "FlexKomSID" SG_ 796 Batt_CabinPriority1_Sts 3114;
BA_ "FlexKomIsMotorola" SG_ 796 Batt_CabinPriority1_Sts 1;
BA_ "FlexKomComment" SG_ 796 Batt_CabinPriority1_Sts "HCP_Schedule1";
BA_ "RID" SG_ 796 ChargeUntilFull1_Sts "6650";
BA_ "GenSigSNA" SG_ 796 ChargeUntilFull1_Sts "0h";
BA_ "GenSigSendType" SG_ 796 ChargeUntilFull1_Sts 5;
BA_ "GenSigCycleTime" SG_ 796 ChargeUntilFull1_Sts 1000;
BA_ "FlexKomSigStartValue" SG_ 796 ChargeUntilFull1_Sts "0000000000000000h";
BA_ "FlexKomSigStartPos" SG_ 796 ChargeUntilFull1_Sts 7;
BA_ "FlexKomSigName" SG_ 796 ChargeUntilFull1_Sts "HCP_Schedule1";
BA_ "FlexKomSigLaenge" SG_ 796 ChargeUntilFull1_Sts 64;
BA_ "FlexKomSID" SG_ 796 ChargeUntilFull1_Sts 3114;
BA_ "FlexKomIsMotorola" SG_ 796 ChargeUntilFull1_Sts 1;
BA_ "FlexKomComment" SG_ 796 ChargeUntilFull1_Sts "HCP_Schedule1";
BA_ "RID" SG_ 796 Do_Not_Repeat1_Sts "6690";
BA_ "GenSigSNA" SG_ 796 Do_Not_Repeat1_Sts "0h";
BA_ "GenSigSendType" SG_ 796 Do_Not_Repeat1_Sts 5;
BA_ "GenSigCycleTime" SG_ 796 Do_Not_Repeat1_Sts 1000;
BA_ "FlexKomSigStartValue" SG_ 796 Do_Not_Repeat1_Sts "0000000000000000h";
BA_ "FlexKomSigStartPos" SG_ 796 Do_Not_Repeat1_Sts 7;
BA_ "FlexKomSigName" SG_ 796 Do_Not_Repeat1_Sts "HCP_Schedule1";
BA_ "FlexKomSigLaenge" SG_ 796 Do_Not_Repeat1_Sts 64;
BA_ "FlexKomSID" SG_ 796 Do_Not_Repeat1_Sts 3114;
BA_ "FlexKomIsMotorola" SG_ 796 Do_Not_Repeat1_Sts 1;
BA_ "FlexKomComment" SG_ 796 Do_Not_Repeat1_Sts "HCP_Schedule1";
BA_ "RID" SG_ 796 End_Time_Hr1_Sts "6666";
BA_ "GenSigSNA" SG_ 796 End_Time_Hr1_Sts "1Fh";
BA_ "GenSigSendType" SG_ 796 End_Time_Hr1_Sts 5;
BA_ "GenSigCycleTime" SG_ 796 End_Time_Hr1_Sts 1000;
BA_ "FlexKomSigStartValue" SG_ 796 End_Time_Hr1_Sts "0000000000000000h";
BA_ "FlexKomSigStartPos" SG_ 796 End_Time_Hr1_Sts 7;
BA_ "FlexKomSigName" SG_ 796 End_Time_Hr1_Sts "HCP_Schedule1";
BA_ "FlexKomSigLaenge" SG_ 796 End_Time_Hr1_Sts 64;
BA_ "FlexKomSID" SG_ 796 End_Time_Hr1_Sts 3114;
BA_ "FlexKomIsMotorola" SG_ 796 End_Time_Hr1_Sts 1;
BA_ "FlexKomComment" SG_ 796 End_Time_Hr1_Sts "HCP_Schedule1";
BA_ "RID" SG_ 796 End_Time_Min1_Sts "6632";
BA_ "GenSigSNA" SG_ 796 End_Time_Min1_Sts "Fh";
BA_ "GenSigSendType" SG_ 796 End_Time_Min1_Sts 5;
BA_ "GenSigCycleTime" SG_ 796 End_Time_Min1_Sts 1000;
BA_ "FlexKomSigStartValue" SG_ 796 End_Time_Min1_Sts "0000000000000000h";
BA_ "FlexKomSigStartPos" SG_ 796 End_Time_Min1_Sts 7;
BA_ "FlexKomSigName" SG_ 796 End_Time_Min1_Sts "HCP_Schedule1";
BA_ "FlexKomSigLaenge" SG_ 796 End_Time_Min1_Sts 64;
BA_ "FlexKomSID" SG_ 796 End_Time_Min1_Sts 3114;
BA_ "FlexKomIsMotorola" SG_ 796 End_Time_Min1_Sts 1;
BA_ "FlexKomComment" SG_ 796 End_Time_Min1_Sts "HCP_Schedule1";
BA_ "RID" SG_ 796 Schedule_Confirmed1 "6644";
BA_ "GenSigSNA" SG_ 796 Schedule_Confirmed1 "0h";
BA_ "GenSigSendType" SG_ 796 Schedule_Confirmed1 5;
BA_ "GenSigCycleTime" SG_ 796 Schedule_Confirmed1 1000;
BA_ "FlexKomSigStartValue" SG_ 796 Schedule_Confirmed1 "0000000000000000h";
BA_ "FlexKomSigStartPos" SG_ 796 Schedule_Confirmed1 7;
BA_ "FlexKomSigName" SG_ 796 Schedule_Confirmed1 "HCP_Schedule1";
BA_ "FlexKomSigLaenge" SG_ 796 Schedule_Confirmed1 64;
BA_ "FlexKomSID" SG_ 796 Schedule_Confirmed1 3114;
BA_ "FlexKomIsMotorola" SG_ 796 Schedule_Confirmed1 1;
BA_ "FlexKomComment" SG_ 796 Schedule_Confirmed1 "HCP_Schedule1";
BA_ "RID" SG_ 796 Schedule_Day1_Sts "6643";
BA_ "GenSigSNA" SG_ 796 Schedule_Day1_Sts "FFh";
BA_ "GenSigSendType" SG_ 796 Schedule_Day1_Sts 5;
BA_ "GenSigCycleTime" SG_ 796 Schedule_Day1_Sts 1000;
BA_ "FlexKomSigStartValue" SG_ 796 Schedule_Day1_Sts "0000000000000000h";
BA_ "FlexKomSigStartPos" SG_ 796 Schedule_Day1_Sts 7;
BA_ "FlexKomSigName" SG_ 796 Schedule_Day1_Sts "HCP_Schedule1";
BA_ "FlexKomSigLaenge" SG_ 796 Schedule_Day1_Sts 64;
BA_ "FlexKomSID" SG_ 796 Schedule_Day1_Sts 3114;
BA_ "FlexKomIsMotorola" SG_ 796 Schedule_Day1_Sts 1;
BA_ "FlexKomComment" SG_ 796 Schedule_Day1_Sts "HCP_Schedule1";
BA_ "RID" SG_ 796 Schedule_Type1_Sts "6678";
BA_ "GenSigSNA" SG_ 796 Schedule_Type1_Sts "3h";
BA_ "GenSigSendType" SG_ 796 Schedule_Type1_Sts 5;
BA_ "GenSigCycleTime" SG_ 796 Schedule_Type1_Sts 1000;
BA_ "FlexKomSigStartValue" SG_ 796 Schedule_Type1_Sts "0000000000000000h";
BA_ "FlexKomSigStartPos" SG_ 796 Schedule_Type1_Sts 7;
BA_ "FlexKomSigName" SG_ 796 Schedule_Type1_Sts "HCP_Schedule1";
BA_ "FlexKomSigLaenge" SG_ 796 Schedule_Type1_Sts 64;
BA_ "FlexKomSID" SG_ 796 Schedule_Type1_Sts 3114;
BA_ "FlexKomIsMotorola" SG_ 796 Schedule_Type1_Sts 1;
BA_ "FlexKomComment" SG_ 796 Schedule_Type1_Sts "HCP_Schedule1";
BA_ "RID" SG_ 796 Start_Time_Hr1_Sts "6677";
BA_ "GenSigSNA" SG_ 796 Start_Time_Hr1_Sts "1Fh";
BA_ "GenSigSendType" SG_ 796 Start_Time_Hr1_Sts 5;
BA_ "GenSigCycleTime" SG_ 796 Start_Time_Hr1_Sts 1000;
BA_ "FlexKomSigStartValue" SG_ 796 Start_Time_Hr1_Sts "0000000000000000h";
BA_ "FlexKomSigStartPos" SG_ 796 Start_Time_Hr1_Sts 7;
BA_ "FlexKomSigName" SG_ 796 Start_Time_Hr1_Sts "HCP_Schedule1";
BA_ "FlexKomSigLaenge" SG_ 796 Start_Time_Hr1_Sts 64;
BA_ "FlexKomSID" SG_ 796 Start_Time_Hr1_Sts 3114;
BA_ "FlexKomIsMotorola" SG_ 796 Start_Time_Hr1_Sts 1;
BA_ "FlexKomComment" SG_ 796 Start_Time_Hr1_Sts "HCP_Schedule1";
BA_ "RID" SG_ 796 Start_Time_Min1_Sts "6689";
BA_ "GenSigSNA" SG_ 796 Start_Time_Min1_Sts "Fh";
BA_ "GenSigSendType" SG_ 796 Start_Time_Min1_Sts 5;
BA_ "GenSigCycleTime" SG_ 796 Start_Time_Min1_Sts 1000;
BA_ "FlexKomSigStartValue" SG_ 796 Start_Time_Min1_Sts "0000000000000000h";
BA_ "FlexKomSigStartPos" SG_ 796 Start_Time_Min1_Sts 7;
BA_ "FlexKomSigName" SG_ 796 Start_Time_Min1_Sts "HCP_Schedule1";
BA_ "FlexKomSigLaenge" SG_ 796 Start_Time_Min1_Sts 64;
BA_ "FlexKomSID" SG_ 796 Start_Time_Min1_Sts 3114;
BA_ "FlexKomIsMotorola" SG_ 796 Start_Time_Min1_Sts 1;
BA_ "FlexKomComment" SG_ 796 Start_Time_Min1_Sts "HCP_Schedule1";
BA_ "RID" SG_ 797 Batt_CabinPriority2_Sts "6691";
BA_ "GenSigSNA" SG_ 797 Batt_CabinPriority2_Sts "0h";
BA_ "GenSigSendType" SG_ 797 Batt_CabinPriority2_Sts 5;
BA_ "GenSigCycleTime" SG_ 797 Batt_CabinPriority2_Sts 1000;
BA_ "FlexKomSigStartValue" SG_ 797 Batt_CabinPriority2_Sts "0000000000000000h";
BA_ "FlexKomSigStartPos" SG_ 797 Batt_CabinPriority2_Sts 7;
BA_ "FlexKomSigName" SG_ 797 Batt_CabinPriority2_Sts "HCP_Schedule2";
BA_ "FlexKomSigLaenge" SG_ 797 Batt_CabinPriority2_Sts 64;
BA_ "FlexKomSID" SG_ 797 Batt_CabinPriority2_Sts 3115;
BA_ "FlexKomIsMotorola" SG_ 797 Batt_CabinPriority2_Sts 1;
BA_ "FlexKomComment" SG_ 797 Batt_CabinPriority2_Sts "HCP_Schedule2";
BA_ "RID" SG_ 797 ChargeUntilFull2_Sts "6635";
BA_ "GenSigSNA" SG_ 797 ChargeUntilFull2_Sts "0h";
BA_ "GenSigSendType" SG_ 797 ChargeUntilFull2_Sts 5;
BA_ "GenSigCycleTime" SG_ 797 ChargeUntilFull2_Sts 1000;
BA_ "FlexKomSigStartValue" SG_ 797 ChargeUntilFull2_Sts "0000000000000000h";
BA_ "FlexKomSigStartPos" SG_ 797 ChargeUntilFull2_Sts 7;
BA_ "FlexKomSigName" SG_ 797 ChargeUntilFull2_Sts "HCP_Schedule2";
BA_ "FlexKomSigLaenge" SG_ 797 ChargeUntilFull2_Sts 64;
BA_ "FlexKomSID" SG_ 797 ChargeUntilFull2_Sts 3115;
BA_ "FlexKomIsMotorola" SG_ 797 ChargeUntilFull2_Sts 1;
BA_ "FlexKomComment" SG_ 797 ChargeUntilFull2_Sts "HCP_Schedule2";
BA_ "RID" SG_ 797 Do_Not_Repeat2_Sts "6626";
BA_ "GenSigSNA" SG_ 797 Do_Not_Repeat2_Sts "0h";
BA_ "GenSigSendType" SG_ 797 Do_Not_Repeat2_Sts 5;
BA_ "GenSigCycleTime" SG_ 797 Do_Not_Repeat2_Sts 1000;
BA_ "FlexKomSigStartValue" SG_ 797 Do_Not_Repeat2_Sts "0000000000000000h";
BA_ "FlexKomSigStartPos" SG_ 797 Do_Not_Repeat2_Sts 7;
BA_ "FlexKomSigName" SG_ 797 Do_Not_Repeat2_Sts "HCP_Schedule2";
BA_ "FlexKomSigLaenge" SG_ 797 Do_Not_Repeat2_Sts 64;
BA_ "FlexKomSID" SG_ 797 Do_Not_Repeat2_Sts 3115;
BA_ "FlexKomIsMotorola" SG_ 797 Do_Not_Repeat2_Sts 1;
BA_ "FlexKomComment" SG_ 797 Do_Not_Repeat2_Sts "HCP_Schedule2";
BA_ "RID" SG_ 797 End_Time_Hr2_Sts "6647";
BA_ "GenSigSNA" SG_ 797 End_Time_Hr2_Sts "1Fh";
BA_ "GenSigSendType" SG_ 797 End_Time_Hr2_Sts 5;
BA_ "GenSigCycleTime" SG_ 797 End_Time_Hr2_Sts 1000;
BA_ "FlexKomSigStartValue" SG_ 797 End_Time_Hr2_Sts "0000000000000000h";
BA_ "FlexKomSigStartPos" SG_ 797 End_Time_Hr2_Sts 7;
BA_ "FlexKomSigName" SG_ 797 End_Time_Hr2_Sts "HCP_Schedule2";
BA_ "FlexKomSigLaenge" SG_ 797 End_Time_Hr2_Sts 64;
BA_ "FlexKomSID" SG_ 797 End_Time_Hr2_Sts 3115;
BA_ "FlexKomIsMotorola" SG_ 797 End_Time_Hr2_Sts 1;
BA_ "FlexKomComment" SG_ 797 End_Time_Hr2_Sts "HCP_Schedule2";
BA_ "RID" SG_ 797 End_Time_Min2_Sts "6659";
BA_ "GenSigSNA" SG_ 797 End_Time_Min2_Sts "Fh";
BA_ "GenSigSendType" SG_ 797 End_Time_Min2_Sts 5;
BA_ "GenSigCycleTime" SG_ 797 End_Time_Min2_Sts 1000;
BA_ "FlexKomSigStartValue" SG_ 797 End_Time_Min2_Sts "0000000000000000h";
BA_ "FlexKomSigStartPos" SG_ 797 End_Time_Min2_Sts 7;
BA_ "FlexKomSigName" SG_ 797 End_Time_Min2_Sts "HCP_Schedule2";
BA_ "FlexKomSigLaenge" SG_ 797 End_Time_Min2_Sts 64;
BA_ "FlexKomSID" SG_ 797 End_Time_Min2_Sts 3115;
BA_ "FlexKomIsMotorola" SG_ 797 End_Time_Min2_Sts 1;
BA_ "FlexKomComment" SG_ 797 End_Time_Min2_Sts "HCP_Schedule2";
BA_ "RID" SG_ 797 Schedule_Confirmed2 "6669";
BA_ "GenSigSNA" SG_ 797 Schedule_Confirmed2 "0h";
BA_ "GenSigSendType" SG_ 797 Schedule_Confirmed2 5;
BA_ "GenSigCycleTime" SG_ 797 Schedule_Confirmed2 1000;
BA_ "FlexKomSigStartValue" SG_ 797 Schedule_Confirmed2 "0000000000000000h";
BA_ "FlexKomSigStartPos" SG_ 797 Schedule_Confirmed2 7;
BA_ "FlexKomSigName" SG_ 797 Schedule_Confirmed2 "HCP_Schedule2";
BA_ "FlexKomSigLaenge" SG_ 797 Schedule_Confirmed2 64;
BA_ "FlexKomSID" SG_ 797 Schedule_Confirmed2 3115;
BA_ "FlexKomIsMotorola" SG_ 797 Schedule_Confirmed2 1;
BA_ "FlexKomComment" SG_ 797 Schedule_Confirmed2 "HCP_Schedule2";
BA_ "RID" SG_ 797 Schedule_Day2_Sts "6692";
BA_ "GenSigSNA" SG_ 797 Schedule_Day2_Sts "FFh";
BA_ "GenSigSendType" SG_ 797 Schedule_Day2_Sts 5;
BA_ "GenSigCycleTime" SG_ 797 Schedule_Day2_Sts 1000;
BA_ "FlexKomSigStartValue" SG_ 797 Schedule_Day2_Sts "0000000000000000h";
BA_ "FlexKomSigStartPos" SG_ 797 Schedule_Day2_Sts 7;
BA_ "FlexKomSigName" SG_ 797 Schedule_Day2_Sts "HCP_Schedule2";
BA_ "FlexKomSigLaenge" SG_ 797 Schedule_Day2_Sts 64;
BA_ "FlexKomSID" SG_ 797 Schedule_Day2_Sts 3115;
BA_ "FlexKomIsMotorola" SG_ 797 Schedule_Day2_Sts 1;
BA_ "FlexKomComment" SG_ 797 Schedule_Day2_Sts "HCP_Schedule2";
BA_ "RID" SG_ 797 Schedule_Type2_Sts "6631";
BA_ "GenSigSNA" SG_ 797 Schedule_Type2_Sts "3h";
BA_ "GenSigSendType" SG_ 797 Schedule_Type2_Sts 5;
BA_ "GenSigCycleTime" SG_ 797 Schedule_Type2_Sts 1000;
BA_ "FlexKomSigStartValue" SG_ 797 Schedule_Type2_Sts "0000000000000000h";
BA_ "FlexKomSigStartPos" SG_ 797 Schedule_Type2_Sts 7;
BA_ "FlexKomSigName" SG_ 797 Schedule_Type2_Sts "HCP_Schedule2";
BA_ "FlexKomSigLaenge" SG_ 797 Schedule_Type2_Sts 64;
BA_ "FlexKomSID" SG_ 797 Schedule_Type2_Sts 3115;
BA_ "FlexKomIsMotorola" SG_ 797 Schedule_Type2_Sts 1;
BA_ "FlexKomComment" SG_ 797 Schedule_Type2_Sts "HCP_Schedule2";
BA_ "RID" SG_ 797 Start_Time_Hr2_Sts "6700";
BA_ "GenSigSNA" SG_ 797 Start_Time_Hr2_Sts "1Fh";
BA_ "GenSigSendType" SG_ 797 Start_Time_Hr2_Sts 5;
BA_ "GenSigCycleTime" SG_ 797 Start_Time_Hr2_Sts 1000;
BA_ "FlexKomSigStartValue" SG_ 797 Start_Time_Hr2_Sts "0000000000000000h";
BA_ "FlexKomSigStartPos" SG_ 797 Start_Time_Hr2_Sts 7;
BA_ "FlexKomSigName" SG_ 797 Start_Time_Hr2_Sts "HCP_Schedule2";
BA_ "FlexKomSigLaenge" SG_ 797 Start_Time_Hr2_Sts 64;
BA_ "FlexKomSID" SG_ 797 Start_Time_Hr2_Sts 3115;
BA_ "FlexKomIsMotorola" SG_ 797 Start_Time_Hr2_Sts 1;
BA_ "FlexKomComment" SG_ 797 Start_Time_Hr2_Sts "HCP_Schedule2";
BA_ "RID" SG_ 797 Start_Time_Min2_Sts "6675";
BA_ "GenSigSNA" SG_ 797 Start_Time_Min2_Sts "Fh";
BA_ "GenSigSendType" SG_ 797 Start_Time_Min2_Sts 5;
BA_ "GenSigCycleTime" SG_ 797 Start_Time_Min2_Sts 1000;
BA_ "FlexKomSigStartValue" SG_ 797 Start_Time_Min2_Sts "0000000000000000h";
BA_ "FlexKomSigStartPos" SG_ 797 Start_Time_Min2_Sts 7;
BA_ "FlexKomSigName" SG_ 797 Start_Time_Min2_Sts "HCP_Schedule2";
BA_ "FlexKomSigLaenge" SG_ 797 Start_Time_Min2_Sts 64;
BA_ "FlexKomSID" SG_ 797 Start_Time_Min2_Sts 3115;
BA_ "FlexKomIsMotorola" SG_ 797 Start_Time_Min2_Sts 1;
BA_ "FlexKomComment" SG_ 797 Start_Time_Min2_Sts "HCP_Schedule2";
BA_ "RID" SG_ 798 Batt_CabinPriority3_Sts "6630";
BA_ "GenSigSNA" SG_ 798 Batt_CabinPriority3_Sts "0h";
BA_ "GenSigSendType" SG_ 798 Batt_CabinPriority3_Sts 5;
BA_ "GenSigCycleTime" SG_ 798 Batt_CabinPriority3_Sts 1000;
BA_ "FlexKomSigStartValue" SG_ 798 Batt_CabinPriority3_Sts "0000000000000000h";
BA_ "FlexKomSigStartPos" SG_ 798 Batt_CabinPriority3_Sts 7;
BA_ "FlexKomSigName" SG_ 798 Batt_CabinPriority3_Sts "HCP_Schedule3";
BA_ "FlexKomSigLaenge" SG_ 798 Batt_CabinPriority3_Sts 64;
BA_ "FlexKomSID" SG_ 798 Batt_CabinPriority3_Sts 3116;
BA_ "FlexKomIsMotorola" SG_ 798 Batt_CabinPriority3_Sts 1;
BA_ "FlexKomComment" SG_ 798 Batt_CabinPriority3_Sts "HCP_Schedule3";
BA_ "RID" SG_ 798 ChargeUntilFull3_Sts "6701";
BA_ "GenSigSNA" SG_ 798 ChargeUntilFull3_Sts "0h";
BA_ "GenSigSendType" SG_ 798 ChargeUntilFull3_Sts 5;
BA_ "GenSigCycleTime" SG_ 798 ChargeUntilFull3_Sts 1000;
BA_ "FlexKomSigStartValue" SG_ 798 ChargeUntilFull3_Sts "0000000000000000h";
BA_ "FlexKomSigStartPos" SG_ 798 ChargeUntilFull3_Sts 7;
BA_ "FlexKomSigName" SG_ 798 ChargeUntilFull3_Sts "HCP_Schedule3";
BA_ "FlexKomSigLaenge" SG_ 798 ChargeUntilFull3_Sts 64;
BA_ "FlexKomSID" SG_ 798 ChargeUntilFull3_Sts 3116;
BA_ "FlexKomIsMotorola" SG_ 798 ChargeUntilFull3_Sts 1;
BA_ "FlexKomComment" SG_ 798 ChargeUntilFull3_Sts "HCP_Schedule3";
BA_ "RID" SG_ 798 Do_Not_Repeat3_Sts "6705";
BA_ "GenSigSNA" SG_ 798 Do_Not_Repeat3_Sts "0h";
BA_ "GenSigSendType" SG_ 798 Do_Not_Repeat3_Sts 5;
BA_ "GenSigCycleTime" SG_ 798 Do_Not_Repeat3_Sts 1000;
BA_ "FlexKomSigStartValue" SG_ 798 Do_Not_Repeat3_Sts "0000000000000000h";
BA_ "FlexKomSigStartPos" SG_ 798 Do_Not_Repeat3_Sts 7;
BA_ "FlexKomSigName" SG_ 798 Do_Not_Repeat3_Sts "HCP_Schedule3";
BA_ "FlexKomSigLaenge" SG_ 798 Do_Not_Repeat3_Sts 64;
BA_ "FlexKomSID" SG_ 798 Do_Not_Repeat3_Sts 3116;
BA_ "FlexKomIsMotorola" SG_ 798 Do_Not_Repeat3_Sts 1;
BA_ "FlexKomComment" SG_ 798 Do_Not_Repeat3_Sts "HCP_Schedule3";
BA_ "RID" SG_ 798 End_Time_Hr3_Sts "6614";
BA_ "GenSigSNA" SG_ 798 End_Time_Hr3_Sts "1Fh";
BA_ "GenSigSendType" SG_ 798 End_Time_Hr3_Sts 5;
BA_ "GenSigCycleTime" SG_ 798 End_Time_Hr3_Sts 1000;
BA_ "FlexKomSigStartValue" SG_ 798 End_Time_Hr3_Sts "0000000000000000h";
BA_ "FlexKomSigStartPos" SG_ 798 End_Time_Hr3_Sts 7;
BA_ "FlexKomSigName" SG_ 798 End_Time_Hr3_Sts "HCP_Schedule3";
BA_ "FlexKomSigLaenge" SG_ 798 End_Time_Hr3_Sts 64;
BA_ "FlexKomSID" SG_ 798 End_Time_Hr3_Sts 3116;
BA_ "FlexKomIsMotorola" SG_ 798 End_Time_Hr3_Sts 1;
BA_ "FlexKomComment" SG_ 798 End_Time_Hr3_Sts "HCP_Schedule3";
BA_ "RID" SG_ 798 End_Time_Min3_Sts "6685";
BA_ "GenSigSNA" SG_ 798 End_Time_Min3_Sts "Fh";
BA_ "GenSigSendType" SG_ 798 End_Time_Min3_Sts 5;
BA_ "GenSigCycleTime" SG_ 798 End_Time_Min3_Sts 1000;
BA_ "FlexKomSigStartValue" SG_ 798 End_Time_Min3_Sts "0000000000000000h";
BA_ "FlexKomSigStartPos" SG_ 798 End_Time_Min3_Sts 7;
BA_ "FlexKomSigName" SG_ 798 End_Time_Min3_Sts "HCP_Schedule3";
BA_ "FlexKomSigLaenge" SG_ 798 End_Time_Min3_Sts 64;
BA_ "FlexKomSID" SG_ 798 End_Time_Min3_Sts 3116;
BA_ "FlexKomIsMotorola" SG_ 798 End_Time_Min3_Sts 1;
BA_ "FlexKomComment" SG_ 798 End_Time_Min3_Sts "HCP_Schedule3";
BA_ "RID" SG_ 798 Schedule_Confirmed3 "6660";
BA_ "GenSigSNA" SG_ 798 Schedule_Confirmed3 "0h";
BA_ "GenSigSendType" SG_ 798 Schedule_Confirmed3 5;
BA_ "GenSigCycleTime" SG_ 798 Schedule_Confirmed3 1000;
BA_ "FlexKomSigStartValue" SG_ 798 Schedule_Confirmed3 "0000000000000000h";
BA_ "FlexKomSigStartPos" SG_ 798 Schedule_Confirmed3 7;
BA_ "FlexKomSigName" SG_ 798 Schedule_Confirmed3 "HCP_Schedule3";
BA_ "FlexKomSigLaenge" SG_ 798 Schedule_Confirmed3 64;
BA_ "FlexKomSID" SG_ 798 Schedule_Confirmed3 3116;
BA_ "FlexKomIsMotorola" SG_ 798 Schedule_Confirmed3 1;
BA_ "FlexKomComment" SG_ 798 Schedule_Confirmed3 "HCP_Schedule3";
BA_ "RID" SG_ 798 Schedule_Day3_Sts "6645";
BA_ "GenSigSNA" SG_ 798 Schedule_Day3_Sts "FFh";
BA_ "GenSigSendType" SG_ 798 Schedule_Day3_Sts 5;
BA_ "GenSigCycleTime" SG_ 798 Schedule_Day3_Sts 1000;
BA_ "FlexKomSigStartValue" SG_ 798 Schedule_Day3_Sts "0000000000000000h";
BA_ "FlexKomSigStartPos" SG_ 798 Schedule_Day3_Sts 7;
BA_ "FlexKomSigName" SG_ 798 Schedule_Day3_Sts "HCP_Schedule3";
BA_ "FlexKomSigLaenge" SG_ 798 Schedule_Day3_Sts 64;
BA_ "FlexKomSID" SG_ 798 Schedule_Day3_Sts 3116;
BA_ "FlexKomIsMotorola" SG_ 798 Schedule_Day3_Sts 1;
BA_ "FlexKomComment" SG_ 798 Schedule_Day3_Sts "HCP_Schedule3";
BA_ "RID" SG_ 798 Schedule_Type3_Sts "6672";
BA_ "GenSigSNA" SG_ 798 Schedule_Type3_Sts "3h";
BA_ "GenSigSendType" SG_ 798 Schedule_Type3_Sts 5;
BA_ "GenSigCycleTime" SG_ 798 Schedule_Type3_Sts 1000;
BA_ "FlexKomSigStartValue" SG_ 798 Schedule_Type3_Sts "0000000000000000h";
BA_ "FlexKomSigStartPos" SG_ 798 Schedule_Type3_Sts 7;
BA_ "FlexKomSigName" SG_ 798 Schedule_Type3_Sts "HCP_Schedule3";
BA_ "FlexKomSigLaenge" SG_ 798 Schedule_Type3_Sts 64;
BA_ "FlexKomSID" SG_ 798 Schedule_Type3_Sts 3116;
BA_ "FlexKomIsMotorola" SG_ 798 Schedule_Type3_Sts 1;
BA_ "FlexKomComment" SG_ 798 Schedule_Type3_Sts "HCP_Schedule3";
BA_ "RID" SG_ 798 Start_Time_Hr3_Sts "6663";
BA_ "GenSigSNA" SG_ 798 Start_Time_Hr3_Sts "1Fh";
BA_ "GenSigSendType" SG_ 798 Start_Time_Hr3_Sts 5;
BA_ "GenSigCycleTime" SG_ 798 Start_Time_Hr3_Sts 1000;
BA_ "FlexKomSigStartValue" SG_ 798 Start_Time_Hr3_Sts "0000000000000000h";
BA_ "FlexKomSigStartPos" SG_ 798 Start_Time_Hr3_Sts 7;
BA_ "FlexKomSigName" SG_ 798 Start_Time_Hr3_Sts "HCP_Schedule3";
BA_ "FlexKomSigLaenge" SG_ 798 Start_Time_Hr3_Sts 64;
BA_ "FlexKomSID" SG_ 798 Start_Time_Hr3_Sts 3116;
BA_ "FlexKomIsMotorola" SG_ 798 Start_Time_Hr3_Sts 1;
BA_ "FlexKomComment" SG_ 798 Start_Time_Hr3_Sts "HCP_Schedule3";
BA_ "RID" SG_ 798 Start_Time_Min3_Sts "6641";
BA_ "GenSigSNA" SG_ 798 Start_Time_Min3_Sts "Fh";
BA_ "GenSigSendType" SG_ 798 Start_Time_Min3_Sts 5;
BA_ "GenSigCycleTime" SG_ 798 Start_Time_Min3_Sts 1000;
BA_ "FlexKomSigStartValue" SG_ 798 Start_Time_Min3_Sts "0000000000000000h";
BA_ "FlexKomSigStartPos" SG_ 798 Start_Time_Min3_Sts 7;
BA_ "FlexKomSigName" SG_ 798 Start_Time_Min3_Sts "HCP_Schedule3";
BA_ "FlexKomSigLaenge" SG_ 798 Start_Time_Min3_Sts 64;
BA_ "FlexKomSID" SG_ 798 Start_Time_Min3_Sts 3116;
BA_ "FlexKomIsMotorola" SG_ 798 Start_Time_Min3_Sts 1;
BA_ "FlexKomComment" SG_ 798 Start_Time_Min3_Sts "HCP_Schedule3";
BA_ "GenSigSNA" SG_ 41 CODE_CLR_HCP "0h";
BA_ "GenSigCycleTime" SG_ 41 CODE_CLR_HCP 10;
BA_ "FlexKomSigStartValue" SG_ 41 CODE_CLR_HCP "00000000000000FFh";
BA_ "FlexKomSigStartPos" SG_ 41 CODE_CLR_HCP 7;
BA_ "FlexKomSigName" SG_ 41 CODE_CLR_HCP "HCP_Torq_Status";
BA_ "FlexKomSigLaenge" SG_ 41 CODE_CLR_HCP 64;
BA_ "FlexKomSID" SG_ 41 CODE_CLR_HCP 2222;
BA_ "FlexKomIsMotorola" SG_ 41 CODE_CLR_HCP 1;
BA_ "FlexKomComment" SG_ 41 CODE_CLR_HCP ".";
BA_ "GenSigStartValue" SG_ 41 CRC_123h 255;
BA_ "GenSigSNA" SG_ 41 CRC_123h "FFh";
BA_ "GenSigCycleTime" SG_ 41 CRC_123h 10;
BA_ "FlexKomSigStartValue" SG_ 41 CRC_123h "00000000000000FFh";
BA_ "FlexKomSigStartPos" SG_ 41 CRC_123h 7;
BA_ "FlexKomSigName" SG_ 41 CRC_123h "HCP_Torq_Status";
BA_ "FlexKomSigLaenge" SG_ 41 CRC_123h 64;
BA_ "FlexKomSID" SG_ 41 CRC_123h 2222;
BA_ "FlexKomIsMotorola" SG_ 41 CRC_123h 1;
BA_ "FlexKomComment" SG_ 41 CRC_123h ".";
BA_ "GenSigSNA" SG_ 41 MC_123h "0h";
BA_ "GenSigCycleTime" SG_ 41 MC_123h 10;
BA_ "FlexKomSigStartValue" SG_ 41 MC_123h "00000000000000FFh";
BA_ "FlexKomSigStartPos" SG_ 41 MC_123h 7;
BA_ "FlexKomSigName" SG_ 41 MC_123h "HCP_Torq_Status";
BA_ "FlexKomSigLaenge" SG_ 41 MC_123h 64;
BA_ "FlexKomSID" SG_ 41 MC_123h 2222;
BA_ "FlexKomIsMotorola" SG_ 41 MC_123h 1;
BA_ "FlexKomComment" SG_ 41 MC_123h ".";
BA_ "GenSigSNA" SG_ 41 PropulsionMode "7h";
BA_ "GenSigCycleTime" SG_ 41 PropulsionMode 10;
BA_ "FlexKomSigStartValue" SG_ 41 PropulsionMode "00000000000000FFh";
BA_ "FlexKomSigStartPos" SG_ 41 PropulsionMode 7;
BA_ "FlexKomSigName" SG_ 41 PropulsionMode "HCP_Torq_Status";
BA_ "FlexKomSigLaenge" SG_ 41 PropulsionMode 64;
BA_ "FlexKomSID" SG_ 41 PropulsionMode 2222;
BA_ "FlexKomIsMotorola" SG_ 41 PropulsionMode 1;
BA_ "FlexKomComment" SG_ 41 PropulsionMode ".";
BA_ "GenSigSNA" SG_ 41 REPRGD_PFC_CLR_HCP "0h";
BA_ "GenSigCycleTime" SG_ 41 REPRGD_PFC_CLR_HCP 10;
BA_ "FlexKomSigStartValue" SG_ 41 REPRGD_PFC_CLR_HCP "00000000000000FFh";
BA_ "FlexKomSigStartPos" SG_ 41 REPRGD_PFC_CLR_HCP 7;
BA_ "FlexKomSigName" SG_ 41 REPRGD_PFC_CLR_HCP "HCP_Torq_Status";
BA_ "FlexKomSigLaenge" SG_ 41 REPRGD_PFC_CLR_HCP 64;
BA_ "FlexKomSID" SG_ 41 REPRGD_PFC_CLR_HCP 2222;
BA_ "FlexKomIsMotorola" SG_ 41 REPRGD_PFC_CLR_HCP 1;
BA_ "FlexKomComment" SG_ 41 REPRGD_PFC_CLR_HCP ".";
BA_ "GenSigSNA" SG_ 41 ReqTorqueOverLayActive "0h";
BA_ "GenSigCycleTime" SG_ 41 ReqTorqueOverLayActive 10;
BA_ "FlexKomSigStartValue" SG_ 41 ReqTorqueOverLayActive "00000000000000FFh";
BA_ "FlexKomSigStartPos" SG_ 41 ReqTorqueOverLayActive 7;
BA_ "FlexKomSigName" SG_ 41 ReqTorqueOverLayActive "HCP_Torq_Status";
BA_ "FlexKomSigLaenge" SG_ 41 ReqTorqueOverLayActive 64;
BA_ "FlexKomSID" SG_ 41 ReqTorqueOverLayActive 2222;
BA_ "FlexKomIsMotorola" SG_ 41 ReqTorqueOverLayActive 1;
BA_ "FlexKomComment" SG_ 41 ReqTorqueOverLayActive ".";
BA_ "GenSigSNA" SG_ 41 TCC_Slip_Rgn "0h";
BA_ "GenSigCycleTime" SG_ 41 TCC_Slip_Rgn 10;
BA_ "FlexKomSigStartValue" SG_ 41 TCC_Slip_Rgn "00000000000000FFh";
BA_ "FlexKomSigStartPos" SG_ 41 TCC_Slip_Rgn 7;
BA_ "FlexKomSigName" SG_ 41 TCC_Slip_Rgn "HCP_Torq_Status";
BA_ "FlexKomSigLaenge" SG_ 41 TCC_Slip_Rgn 64;
BA_ "FlexKomSID" SG_ 41 TCC_Slip_Rgn 2222;
BA_ "FlexKomIsMotorola" SG_ 41 TCC_Slip_Rgn 1;
BA_ "FlexKomComment" SG_ 41 TCC_Slip_Rgn ".";
BA_ "RID" SG_ 801 Batt_CabinPriority1 "6640";
BA_ "GenSigSNA" SG_ 801 Batt_CabinPriority1 "0h";
BA_ "GenSigSendType" SG_ 801 Batt_CabinPriority1 5;
BA_ "GenSigCycleTime" SG_ 801 Batt_CabinPriority1 1000;
BA_ "FlexKomSigStartValue" SG_ 801 Batt_CabinPriority1 "0000000000000000h";
BA_ "FlexKomSigStartPos" SG_ 801 Batt_CabinPriority1 7;
BA_ "FlexKomSigName" SG_ 801 Batt_CabinPriority1 "HU_Schedule1";
BA_ "FlexKomSigLaenge" SG_ 801 Batt_CabinPriority1 64;
BA_ "FlexKomSID" SG_ 801 Batt_CabinPriority1 3108;
BA_ "FlexKomIsMotorola" SG_ 801 Batt_CabinPriority1 1;
BA_ "FlexKomComment" SG_ 801 Batt_CabinPriority1 "HU_Schedule1";
BA_ "RID" SG_ 801 ChargeUntilFull1 "6704";
BA_ "GenSigSNA" SG_ 801 ChargeUntilFull1 "0h";
BA_ "GenSigSendType" SG_ 801 ChargeUntilFull1 5;
BA_ "GenSigCycleTime" SG_ 801 ChargeUntilFull1 1000;
BA_ "FlexKomSigStartValue" SG_ 801 ChargeUntilFull1 "0000000000000000h";
BA_ "FlexKomSigStartPos" SG_ 801 ChargeUntilFull1 7;
BA_ "FlexKomSigName" SG_ 801 ChargeUntilFull1 "HU_Schedule1";
BA_ "FlexKomSigLaenge" SG_ 801 ChargeUntilFull1 64;
BA_ "FlexKomSID" SG_ 801 ChargeUntilFull1 3108;
BA_ "FlexKomIsMotorola" SG_ 801 ChargeUntilFull1 1;
BA_ "FlexKomComment" SG_ 801 ChargeUntilFull1 "HU_Schedule1";
BA_ "RID" SG_ 801 Do_Not_Repeat1 "6633";
BA_ "GenSigSNA" SG_ 801 Do_Not_Repeat1 "0h";
BA_ "GenSigSendType" SG_ 801 Do_Not_Repeat1 5;
BA_ "GenSigCycleTime" SG_ 801 Do_Not_Repeat1 1000;
BA_ "FlexKomSigStartValue" SG_ 801 Do_Not_Repeat1 "0000000000000000h";
BA_ "FlexKomSigStartPos" SG_ 801 Do_Not_Repeat1 7;
BA_ "FlexKomSigName" SG_ 801 Do_Not_Repeat1 "HU_Schedule1";
BA_ "FlexKomSigLaenge" SG_ 801 Do_Not_Repeat1 64;
BA_ "FlexKomSID" SG_ 801 Do_Not_Repeat1 3108;
BA_ "FlexKomIsMotorola" SG_ 801 Do_Not_Repeat1 1;
BA_ "FlexKomComment" SG_ 801 Do_Not_Repeat1 "HU_Schedule1";
BA_ "RID" SG_ 801 Enable_Schedule1 "6656";
BA_ "GenSigSNA" SG_ 801 Enable_Schedule1 "0h";
BA_ "GenSigSendType" SG_ 801 Enable_Schedule1 5;
BA_ "GenSigCycleTime" SG_ 801 Enable_Schedule1 1000;
BA_ "FlexKomSigStartValue" SG_ 801 Enable_Schedule1 "0000000000000000h";
BA_ "FlexKomSigStartPos" SG_ 801 Enable_Schedule1 7;
BA_ "FlexKomSigName" SG_ 801 Enable_Schedule1 "HU_Schedule1";
BA_ "FlexKomSigLaenge" SG_ 801 Enable_Schedule1 64;
BA_ "FlexKomSID" SG_ 801 Enable_Schedule1 3108;
BA_ "FlexKomIsMotorola" SG_ 801 Enable_Schedule1 1;
BA_ "FlexKomComment" SG_ 801 Enable_Schedule1 "HU_Schedule1";
BA_ "RID" SG_ 801 End_Time_Hr1 "6670";
BA_ "GenSigSNA" SG_ 801 End_Time_Hr1 "1Fh";
BA_ "GenSigSendType" SG_ 801 End_Time_Hr1 5;
BA_ "GenSigCycleTime" SG_ 801 End_Time_Hr1 1000;
BA_ "FlexKomSigStartValue" SG_ 801 End_Time_Hr1 "0000000000000000h";
BA_ "FlexKomSigStartPos" SG_ 801 End_Time_Hr1 7;
BA_ "FlexKomSigName" SG_ 801 End_Time_Hr1 "HU_Schedule1";
BA_ "FlexKomSigLaenge" SG_ 801 End_Time_Hr1 64;
BA_ "FlexKomSID" SG_ 801 End_Time_Hr1 3108;
BA_ "FlexKomIsMotorola" SG_ 801 End_Time_Hr1 1;
BA_ "FlexKomComment" SG_ 801 End_Time_Hr1 "HU_Schedule1";
BA_ "RID" SG_ 801 End_Time_Min1 "6662";
BA_ "GenSigSNA" SG_ 801 End_Time_Min1 "Fh";
BA_ "GenSigSendType" SG_ 801 End_Time_Min1 5;
BA_ "GenSigCycleTime" SG_ 801 End_Time_Min1 1000;
BA_ "FlexKomSigStartValue" SG_ 801 End_Time_Min1 "0000000000000000h";
BA_ "FlexKomSigStartPos" SG_ 801 End_Time_Min1 7;
BA_ "FlexKomSigName" SG_ 801 End_Time_Min1 "HU_Schedule1";
BA_ "FlexKomSigLaenge" SG_ 801 End_Time_Min1 64;
BA_ "FlexKomSID" SG_ 801 End_Time_Min1 3108;
BA_ "FlexKomIsMotorola" SG_ 801 End_Time_Min1 1;
BA_ "FlexKomComment" SG_ 801 End_Time_Min1 "HU_Schedule1";
BA_ "RID" SG_ 801 Schedule_Day1 "6623";
BA_ "GenSigSNA" SG_ 801 Schedule_Day1 "FFh";
BA_ "GenSigSendType" SG_ 801 Schedule_Day1 5;
BA_ "GenSigCycleTime" SG_ 801 Schedule_Day1 1000;
BA_ "FlexKomSigStartValue" SG_ 801 Schedule_Day1 "0000000000000000h";
BA_ "FlexKomSigStartPos" SG_ 801 Schedule_Day1 7;
BA_ "FlexKomSigName" SG_ 801 Schedule_Day1 "HU_Schedule1";
BA_ "FlexKomSigLaenge" SG_ 801 Schedule_Day1 64;
BA_ "FlexKomSID" SG_ 801 Schedule_Day1 3108;
BA_ "FlexKomIsMotorola" SG_ 801 Schedule_Day1 1;
BA_ "FlexKomComment" SG_ 801 Schedule_Day1 "HU_Schedule1";
BA_ "RID" SG_ 801 Schedule_Type1 "6681";
BA_ "GenSigSNA" SG_ 801 Schedule_Type1 "3h";
BA_ "GenSigSendType" SG_ 801 Schedule_Type1 5;
BA_ "GenSigCycleTime" SG_ 801 Schedule_Type1 1000;
BA_ "FlexKomSigStartValue" SG_ 801 Schedule_Type1 "0000000000000000h";
BA_ "FlexKomSigStartPos" SG_ 801 Schedule_Type1 7;
BA_ "FlexKomSigName" SG_ 801 Schedule_Type1 "HU_Schedule1";
BA_ "FlexKomSigLaenge" SG_ 801 Schedule_Type1 64;
BA_ "FlexKomSID" SG_ 801 Schedule_Type1 3108;
BA_ "FlexKomIsMotorola" SG_ 801 Schedule_Type1 1;
BA_ "FlexKomComment" SG_ 801 Schedule_Type1 "HU_Schedule1";
BA_ "RID" SG_ 801 Start_Time_Hr1 "6627";
BA_ "GenSigSNA" SG_ 801 Start_Time_Hr1 "1Fh";
BA_ "GenSigSendType" SG_ 801 Start_Time_Hr1 5;
BA_ "GenSigCycleTime" SG_ 801 Start_Time_Hr1 1000;
BA_ "FlexKomSigStartValue" SG_ 801 Start_Time_Hr1 "0000000000000000h";
BA_ "FlexKomSigStartPos" SG_ 801 Start_Time_Hr1 7;
BA_ "FlexKomSigName" SG_ 801 Start_Time_Hr1 "HU_Schedule1";
BA_ "FlexKomSigLaenge" SG_ 801 Start_Time_Hr1 64;
BA_ "FlexKomSID" SG_ 801 Start_Time_Hr1 3108;
BA_ "FlexKomIsMotorola" SG_ 801 Start_Time_Hr1 1;
BA_ "FlexKomComment" SG_ 801 Start_Time_Hr1 "HU_Schedule1";
BA_ "RID" SG_ 801 Start_Time_Min1 "6621";
BA_ "GenSigSNA" SG_ 801 Start_Time_Min1 "Fh";
BA_ "GenSigSendType" SG_ 801 Start_Time_Min1 5;
BA_ "GenSigCycleTime" SG_ 801 Start_Time_Min1 1000;
BA_ "FlexKomSigStartValue" SG_ 801 Start_Time_Min1 "0000000000000000h";
BA_ "FlexKomSigStartPos" SG_ 801 Start_Time_Min1 7;
BA_ "FlexKomSigName" SG_ 801 Start_Time_Min1 "HU_Schedule1";
BA_ "FlexKomSigLaenge" SG_ 801 Start_Time_Min1 64;
BA_ "FlexKomSID" SG_ 801 Start_Time_Min1 3108;
BA_ "FlexKomIsMotorola" SG_ 801 Start_Time_Min1 1;
BA_ "FlexKomComment" SG_ 801 Start_Time_Min1 "HU_Schedule1";
BA_ "RID" SG_ 801 Submit_Schedule1 "6654";
BA_ "GenSigSNA" SG_ 801 Submit_Schedule1 "0h";
BA_ "GenSigSendType" SG_ 801 Submit_Schedule1 5;
BA_ "GenSigCycleTime" SG_ 801 Submit_Schedule1 1000;
BA_ "FlexKomSigStartValue" SG_ 801 Submit_Schedule1 "0000000000000000h";
BA_ "FlexKomSigStartPos" SG_ 801 Submit_Schedule1 7;
BA_ "FlexKomSigName" SG_ 801 Submit_Schedule1 "HU_Schedule1";
BA_ "FlexKomSigLaenge" SG_ 801 Submit_Schedule1 64;
BA_ "FlexKomSID" SG_ 801 Submit_Schedule1 3108;
BA_ "FlexKomIsMotorola" SG_ 801 Submit_Schedule1 1;
BA_ "FlexKomComment" SG_ 801 Submit_Schedule1 "HU_Schedule1";
BA_ "RID" SG_ 802 Batt_CabinPriority2 "6651";
BA_ "GenSigSNA" SG_ 802 Batt_CabinPriority2 "0h";
BA_ "GenSigSendType" SG_ 802 Batt_CabinPriority2 5;
BA_ "GenSigCycleTime" SG_ 802 Batt_CabinPriority2 1000;
BA_ "FlexKomSigStartValue" SG_ 802 Batt_CabinPriority2 "0000000000000000h";
BA_ "FlexKomSigStartPos" SG_ 802 Batt_CabinPriority2 7;
BA_ "FlexKomSigName" SG_ 802 Batt_CabinPriority2 "HU_Schedule2";
BA_ "FlexKomSigLaenge" SG_ 802 Batt_CabinPriority2 64;
BA_ "FlexKomSID" SG_ 802 Batt_CabinPriority2 3109;
BA_ "FlexKomIsMotorola" SG_ 802 Batt_CabinPriority2 1;
BA_ "FlexKomComment" SG_ 802 Batt_CabinPriority2 "HU_Schedule2";
BA_ "RID" SG_ 802 ChargeUntilFull2 "6687";
BA_ "GenSigSNA" SG_ 802 ChargeUntilFull2 "0h";
BA_ "GenSigSendType" SG_ 802 ChargeUntilFull2 5;
BA_ "GenSigCycleTime" SG_ 802 ChargeUntilFull2 1000;
BA_ "FlexKomSigStartValue" SG_ 802 ChargeUntilFull2 "0000000000000000h";
BA_ "FlexKomSigStartPos" SG_ 802 ChargeUntilFull2 7;
BA_ "FlexKomSigName" SG_ 802 ChargeUntilFull2 "HU_Schedule2";
BA_ "FlexKomSigLaenge" SG_ 802 ChargeUntilFull2 64;
BA_ "FlexKomSID" SG_ 802 ChargeUntilFull2 3109;
BA_ "FlexKomIsMotorola" SG_ 802 ChargeUntilFull2 1;
BA_ "FlexKomComment" SG_ 802 ChargeUntilFull2 "HU_Schedule2";
BA_ "RID" SG_ 802 Do_Not_Repeat2 "6639";
BA_ "GenSigSNA" SG_ 802 Do_Not_Repeat2 "0h";
BA_ "GenSigSendType" SG_ 802 Do_Not_Repeat2 5;
BA_ "GenSigCycleTime" SG_ 802 Do_Not_Repeat2 1000;
BA_ "FlexKomSigStartValue" SG_ 802 Do_Not_Repeat2 "0000000000000000h";
BA_ "FlexKomSigStartPos" SG_ 802 Do_Not_Repeat2 7;
BA_ "FlexKomSigName" SG_ 802 Do_Not_Repeat2 "HU_Schedule2";
BA_ "FlexKomSigLaenge" SG_ 802 Do_Not_Repeat2 64;
BA_ "FlexKomSID" SG_ 802 Do_Not_Repeat2 3109;
BA_ "FlexKomIsMotorola" SG_ 802 Do_Not_Repeat2 1;
BA_ "FlexKomComment" SG_ 802 Do_Not_Repeat2 "HU_Schedule2";
BA_ "RID" SG_ 802 Enable_Schedule2 "6637";
BA_ "GenSigSNA" SG_ 802 Enable_Schedule2 "0h";
BA_ "GenSigSendType" SG_ 802 Enable_Schedule2 5;
BA_ "GenSigCycleTime" SG_ 802 Enable_Schedule2 1000;
BA_ "FlexKomSigStartValue" SG_ 802 Enable_Schedule2 "0000000000000000h";
BA_ "FlexKomSigStartPos" SG_ 802 Enable_Schedule2 7;
BA_ "FlexKomSigName" SG_ 802 Enable_Schedule2 "HU_Schedule2";
BA_ "FlexKomSigLaenge" SG_ 802 Enable_Schedule2 64;
BA_ "FlexKomSID" SG_ 802 Enable_Schedule2 3109;
BA_ "FlexKomIsMotorola" SG_ 802 Enable_Schedule2 1;
BA_ "FlexKomComment" SG_ 802 Enable_Schedule2 "HU_Schedule2";
BA_ "RID" SG_ 802 End_Time_Hr2 "6673";
BA_ "GenSigSNA" SG_ 802 End_Time_Hr2 "1Fh";
BA_ "GenSigSendType" SG_ 802 End_Time_Hr2 5;
BA_ "GenSigCycleTime" SG_ 802 End_Time_Hr2 1000;
BA_ "FlexKomSigStartValue" SG_ 802 End_Time_Hr2 "0000000000000000h";
BA_ "FlexKomSigStartPos" SG_ 802 End_Time_Hr2 7;
BA_ "FlexKomSigName" SG_ 802 End_Time_Hr2 "HU_Schedule2";
BA_ "FlexKomSigLaenge" SG_ 802 End_Time_Hr2 64;
BA_ "FlexKomSID" SG_ 802 End_Time_Hr2 3109;
BA_ "FlexKomIsMotorola" SG_ 802 End_Time_Hr2 1;
BA_ "FlexKomComment" SG_ 802 End_Time_Hr2 "HU_Schedule2";
BA_ "RID" SG_ 802 End_Time_Min2 "6657";
BA_ "GenSigSNA" SG_ 802 End_Time_Min2 "Fh";
BA_ "GenSigSendType" SG_ 802 End_Time_Min2 5;
BA_ "GenSigCycleTime" SG_ 802 End_Time_Min2 1000;
BA_ "FlexKomSigStartValue" SG_ 802 End_Time_Min2 "0000000000000000h";
BA_ "FlexKomSigStartPos" SG_ 802 End_Time_Min2 7;
BA_ "FlexKomSigName" SG_ 802 End_Time_Min2 "HU_Schedule2";
BA_ "FlexKomSigLaenge" SG_ 802 End_Time_Min2 64;
BA_ "FlexKomSID" SG_ 802 End_Time_Min2 3109;
BA_ "FlexKomIsMotorola" SG_ 802 End_Time_Min2 1;
BA_ "FlexKomComment" SG_ 802 End_Time_Min2 "HU_Schedule2";
BA_ "RID" SG_ 802 Schedule_Day2 "6665";
BA_ "GenSigSNA" SG_ 802 Schedule_Day2 "FFh";
BA_ "GenSigSendType" SG_ 802 Schedule_Day2 5;
BA_ "GenSigCycleTime" SG_ 802 Schedule_Day2 1000;
BA_ "FlexKomSigStartValue" SG_ 802 Schedule_Day2 "0000000000000000h";
BA_ "FlexKomSigStartPos" SG_ 802 Schedule_Day2 7;
BA_ "FlexKomSigName" SG_ 802 Schedule_Day2 "HU_Schedule2";
BA_ "FlexKomSigLaenge" SG_ 802 Schedule_Day2 64;
BA_ "FlexKomSID" SG_ 802 Schedule_Day2 3109;
BA_ "FlexKomIsMotorola" SG_ 802 Schedule_Day2 1;
BA_ "FlexKomComment" SG_ 802 Schedule_Day2 "HU_Schedule2";
BA_ "RID" SG_ 802 Schedule_Type2 "6611";
BA_ "GenSigSNA" SG_ 802 Schedule_Type2 "3h";
BA_ "GenSigSendType" SG_ 802 Schedule_Type2 5;
BA_ "GenSigCycleTime" SG_ 802 Schedule_Type2 1000;
BA_ "FlexKomSigStartValue" SG_ 802 Schedule_Type2 "0000000000000000h";
BA_ "FlexKomSigStartPos" SG_ 802 Schedule_Type2 7;
BA_ "FlexKomSigName" SG_ 802 Schedule_Type2 "HU_Schedule2";
BA_ "FlexKomSigLaenge" SG_ 802 Schedule_Type2 64;
BA_ "FlexKomSID" SG_ 802 Schedule_Type2 3109;
BA_ "FlexKomIsMotorola" SG_ 802 Schedule_Type2 1;
BA_ "FlexKomComment" SG_ 802 Schedule_Type2 "HU_Schedule2";
BA_ "RID" SG_ 802 Start_Time_Hr2 "6653";
BA_ "GenSigSNA" SG_ 802 Start_Time_Hr2 "1Fh";
BA_ "GenSigSendType" SG_ 802 Start_Time_Hr2 5;
BA_ "GenSigCycleTime" SG_ 802 Start_Time_Hr2 1000;
BA_ "FlexKomSigStartValue" SG_ 802 Start_Time_Hr2 "0000000000000000h";
BA_ "FlexKomSigStartPos" SG_ 802 Start_Time_Hr2 7;
BA_ "FlexKomSigName" SG_ 802 Start_Time_Hr2 "HU_Schedule2";
BA_ "FlexKomSigLaenge" SG_ 802 Start_Time_Hr2 64;
BA_ "FlexKomSID" SG_ 802 Start_Time_Hr2 3109;
BA_ "FlexKomIsMotorola" SG_ 802 Start_Time_Hr2 1;
BA_ "FlexKomComment" SG_ 802 Start_Time_Hr2 "HU_Schedule2";
BA_ "RID" SG_ 802 Start_Time_Min2 "6695";
BA_ "GenSigSNA" SG_ 802 Start_Time_Min2 "Fh";
BA_ "GenSigSendType" SG_ 802 Start_Time_Min2 5;
BA_ "GenSigCycleTime" SG_ 802 Start_Time_Min2 1000;
BA_ "FlexKomSigStartValue" SG_ 802 Start_Time_Min2 "0000000000000000h";
BA_ "FlexKomSigStartPos" SG_ 802 Start_Time_Min2 7;
BA_ "FlexKomSigName" SG_ 802 Start_Time_Min2 "HU_Schedule2";
BA_ "FlexKomSigLaenge" SG_ 802 Start_Time_Min2 64;
BA_ "FlexKomSID" SG_ 802 Start_Time_Min2 3109;
BA_ "FlexKomIsMotorola" SG_ 802 Start_Time_Min2 1;
BA_ "FlexKomComment" SG_ 802 Start_Time_Min2 "HU_Schedule2";
BA_ "RID" SG_ 802 Submit_Schedule2 "6698";
BA_ "GenSigSNA" SG_ 802 Submit_Schedule2 "0h";
BA_ "GenSigSendType" SG_ 802 Submit_Schedule2 5;
BA_ "GenSigCycleTime" SG_ 802 Submit_Schedule2 1000;
BA_ "FlexKomSigStartValue" SG_ 802 Submit_Schedule2 "0000000000000000h";
BA_ "FlexKomSigStartPos" SG_ 802 Submit_Schedule2 7;
BA_ "FlexKomSigName" SG_ 802 Submit_Schedule2 "HU_Schedule2";
BA_ "FlexKomSigLaenge" SG_ 802 Submit_Schedule2 64;
BA_ "FlexKomSID" SG_ 802 Submit_Schedule2 3109;
BA_ "FlexKomIsMotorola" SG_ 802 Submit_Schedule2 1;
BA_ "FlexKomComment" SG_ 802 Submit_Schedule2 "HU_Schedule2";
VAL_ 1015 EC_ECUCfg8_Stat 0 "NA" 1 "PROGAMMED" 2 "REQUEST_DATA" 3 "SNA" ;
VAL_ 984 EC_ECUCfg9_Stat 0 "NA" 1 "PROGAMMED" 2 "REQUEST_DATA" 3 "SNA" ;
VAL_ 833 GPF_T1_Status 0 "PASS" 1 "SHORT_TO_VBAT" 2 "SHORT_TO_GND" 5 "OPEN_CKT" 6 "TC_ASIC" 11 "TC_CJ" 13 "TC_ECU" 16 "NOT_COMPLETE" ;
VAL_ 833 GPF_T2_Status 0 "PASS" 1 "SHORT_TO_VBAT" 2 "SHORT_TO_GND" 5 "OPEN_CKT" 6 "TC_ASIC" 11 "TC_CJ" 13 "TC_ECU" 16 "NOT_COMPLETE" ;
VAL_ 908 GPS_Date_Day 255 "SNA" ;
VAL_ 908 GPS_Date_Month 255 "SNA" ;
VAL_ 908 GPS_Date_Year 65535 "SNA" ;
VAL_ 908 GPS_UTC_Hour 255 "SNA" ;
VAL_ 908 GPS_UTC_Minute 255 "SNA" ;
VAL_ 908 GPS_UTC_Second 65535 "SNA" ;
VAL_ 689 DRV_TEMP_DR_POS 127 "SNA" ;
VAL_ 689 FT_HVAC_BLW_FN_SP 127 "SNA" ;
VAL_ 689 PAS_TEMP_DR_POS 127 "SNA" ;
VAL_ 609 IBS_Q_received 65535 "SNA" ;
VAL_ 609 IBS_Q_released 65535 "SNA" ;
VAL_ 609 IBS_Tm_Lst_Reset_Days 4095 "SNA" ;
VAL_ 609 IBS_Tm_Lst_Reset_Sec 65535 "SNA" ;
VAL_ 649 HVAC_CLNT_FLW_MIN 0 "OPEN" 254 "CLOSE" 255 "SNA" ;
VAL_ 663 SpSt_Pad1 0 "UN_PSD" 1 "PSD" 2 "S_GND" 3 "S_PLUS" 4 "IND" 7 "SNA" ;
VAL_ 663 SpSt_Pad2 0 "UN_PSD" 1 "PSD" 2 "S_GND" 3 "S_PLUS" 4 "IND" 7 "SNA" ;
VAL_ 641 IBS_R_Batt 2047 "SNA" ;
VAL_ 641 IBS_R_Batt_25 2047 "SNA" ;
VAL_ 641 PaddlesModeReq 0 "NONE" 1 "DIS" 2 "EN" 3 "SNA" ;
VAL_ 641 TBM_E_CALL_STS 0 "OFF" 1 "SOS_SERVICE" 2 "SOS_BATT" 3 "SOS_START" 4 "SOS_Call" 5 "SOS_EST" 6 "SOS_END" 7 "SOS_INCOM" 8 "SOS_UNABLE" 9 "SOS_START_CANCEL" 10 "OS_UPDATING" 11 "OS_UPDATED" 12 "BM_MSG1" 13 "BM_MSG2" 14 "BM_MSG3" 15 "SNA" ;
VAL_ 641 TGW_AUD_MD_CAB_DR 0 "AM_SEL" 1 "FM_SEL" 2 "MW_SEL" 3 "LW_SEL" 4 "INT_Disk_SEL" 5 "INT_HDD_SEL" 6 "INT_AUX_SEL" 7 "INT_SLOT_SEL" 8 "USB3_SEL" 9 "SDAR1_SEL" 10 "SW_SEL" 11 "VES_DVD1_SEL" 12 "TMM_SEL" 13 "VES_AUX1_SEL" 14 "VES_AUX2_SEL" 15 "SDARV_SEL" 16 "PPR_SEL" 18 "DAB_SEL" 19 "TGW_USB1_SEL" 20 "ES_SEL" 21 "VES_AUX3_SEL" 22 "VES_AUX4_SEL" 23 "PASS_BT1_SEL" 24 "TV_SEL" 25 "USB2_SEL" 26 "APPS_SEL" 27 "AUD_MUTED" 28 "IR_OFF" 29 "RAD_OFF" 30 "RAD_LOCK" 31 "SNA" ;
VAL_ 641 Trns_DrvMdReq 0 "NP" 1 "STREET" 2 "VALET" 3 "SPORT" 4 "S_PLUS" 5 "TRACK" 6 "ECO" 7 "SNOW" 8 "ROCK" 9 "TOW" 10 "DRAG" 11 "MUD" 12 "SAND" 13 "BAJA" 15 "SNA" ;
VAL_ 651 HILL_DES_RQ_ICS 0 "NOT_PSD" 1 "PSD" 3 "SNA" ;
VAL_ 605 AxleLckrOFF_SW 0 "NOT_PSD" 1 "PSD" 3 "SNA" ;
VAL_ 605 AxleLckrSEL_SW 0 "NOT_PSD" 1 "UP_PSD" 2 "DOWN_PSD" 3 "SNA" ;
VAL_ 605 PwrTop_Cal 0 "DEF" 1 "PT_UNCAL" 2 "PT_CAL_IN_PROG" 3 "PT_CAL_INTERUPT" 4 "PT_CAL_COMPLETE" 5 "PT_UNCAL_ENG_OFF" 7 "SNA" ;
VAL_ 605 PwrTop_Cmd 0 "NOT_ACTIVE" 1 "OPEN_ACTIVE" 2 "CLS_ACTIVE" 3 "SNA" ;
VAL_ 605 PwrTop_Pos 0 "DEF" 1 "PARTIAL_OPEN" 2 "FULL_OPEN" 3 "FULL_CLS" ;
VAL_ 605 PwrTop_Stat 0 "DEF" 1 "OBSTRUCTED" 2 "SPEED_INH" 3 "COLD_INH" 4 "LATCHED" 7 "SNA" ;
VAL_ 605 TGW_AUD_MD2_CAB_DR 0 "NONE" 1 "Android_Auto" 2 "Apple_CarPlay" 3 "Music_Muted" 4 "Baidu_CarLife" 5 "Amazon_Alexa" ;
VAL_ 623 HVAC_Blwr_Perct 127 "SNA" ;
VAL_ 623 HtrCorTmp_InTgt 255 "SNA" ;
VAL_ 623 SwayBarBtnRq 0 "NOT_PRESSED" 1 "PRESSED" 2 "STUCK" 3 "SNA" ;
VAL_ 623 VEH_INT_TEMP 65535 "SNA" ;
VAL_ 910 IBS3_FLAG_DISCONNECT 0 "No_Disconnect" 1 "Disconnect" ;
VAL_ 910 IBS3_SOC 127 "SNA" ;
VAL_ 910 IBS3_SOC_Accuracy 0 "Inaccurate" 1 "Accurate" ;
VAL_ 910 IBS3_SOF_Q 255 "SNA" ;
VAL_ 910 IBS3_SOF_Q_Accuracy 0 "Inaccurate" 1 "Accurate" ;
VAL_ 910 IBS3_SOF_VC 127 "SNA" ;
VAL_ 910 IBS3_SOF_V_Accuracy 0 "Inaccurate" 1 "Accurate" ;
VAL_ 910 IBS3_SOH_Q 127 "SNA" ;
VAL_ 910 IBS3_SOH_Q_Accuracy 0 "Inaccurate" 1 "Accurate" ;
VAL_ 910 IBS3_T_BATT 255 "SNA" ;
VAL_ 910 IBS3_TempFailStatus 0 "Fail_not_present" 1 "Fail_present" ;
VAL_ 321 BatPwrUsage_V 0 "Valid" 1 "Not_Valid" ;
VAL_ 321 Echarge_SOCRange_Cnfm 0 "40_Percent" 1 "60_Percent" 2 "80_Percent" 3 "Empty_Space" ;
VAL_ 321 Echarge_Type_Cnfm 0 "Battery_Save" 1 "Battery_Charge" ;
VAL_ 321 Est_Range 255 "SNA" ;
VAL_ 321 HEV_LMP_RQ 0 "OFF" 1 "ON" 2 "BLINK" 3 "SNA" ;
VAL_ 321 MaxRegenLedCmd 0 "OFF" 1 "Cont" 2 "Blink" 3 "SNA" ;
VAL_ 321 R134a_PressSts 511 "SNA" ;
VAL_ 298 BSGActualTorque 1023 "SNA" ;
VAL_ 298 HCP_Comm_Fail_ePT 0 "No_Fault" 1 "HCP_LoC_ePT_TCM" 2 "HCP_LoC_ePT_ECM" 3 "HCP_LoC_ePT_TCM_ECM" 7 "HCP_Bus_Failure_ePT" ;
VAL_ 298 HCP_Shutdown_Command 0 "Default" 1 "Initiate_Powerdown" 2 "Shutdown" 3 "Cancel_Powerdown" 7 "SNA" ;
VAL_ 298 Hybrid_Immobilizer_Status 0 "HCPIS" 1 "HCPKILL" 2 "HCPRUN" 3 "SNA" ;
VAL_ 611 ChargingLevel 0 "Default_NoLevel" 1 "Level_1_AC" 2 "Level_2_AC" 3 "Level_3_AC" 4 "Level_1_DC" 5 "Level_2_DC" 6 "PlugInNotDet" 7 "PPI_1_No_Drive" 8 "PPI_2_OK_Drive" 15 "SNA" ;
VAL_ 611 ChargingSysSts 0 "NotCharging" 1 "Charging" 2 "ChargeInterrupted" 3 "ChargeComplete" 7 "SNA" ;
VAL_ 611 CompStat 0 "NormalOperation" 1 "DegradedOperation" 2 "Inoperative" 3 "Reserved1" 4 "Reserved2" 5 "Reserved3" 6 "Reserved4" 15 "SNA" ;
VAL_ 611 EstTimeofChrg_Lv1 8191 "SNA" ;
VAL_ 611 EstTimeofChrg_Lv2 2047 "SNA" ;
VAL_ 611 HVBatCntctrStat 0 "Open" 1 "Precharging" 2 "Closed" 3 "Precharge_Failed" 4 "Precharge_Inhibited" 7 "SNA" ;
VAL_ 611 HtrCoreInletTemp 255 "SNA" ;
VAL_ 611 MIL_OnRq_BPCM 0 "FALSE" 1 "TRUE" ;
VAL_ 621 ElecClntHtrInletTemp 255 "SNA" ;
VAL_ 621 ElecCoolantHtrPwr 255 "SNA" ;
VAL_ 621 HTAuxPmpMontrngRPM 0 "TRUE" 1 "FALSE" 3 "SNA" ;
VAL_ 621 HTAuxPmpRPMAct 255 "SNA" ;
VAL_ 621 HVBat_CoolantLvlLo 0 "FALSE" 1 "TRUE" 3 "SNA" ;
VAL_ 40 SumTrqMax 8191 "SNA" ;
VAL_ 40 SumTrqMin 8191 "SNA" ;
VAL_ 40 SumTrqStatic 8191 "SNA" ;
VAL_ 54 ExpSumTrq 8191 "SNA" ;
VAL_ 54 SumTrqStatic_SEM 8191 "SNA" ;
VAL_ 54 SumTrqTgt_SEM 8191 "SNA" ;
VAL_ 56 MotorB_Speed 65535 "SNA" ;
VAL_ 56 SumTrqSel_D_TTC 8191 "SNA" ;
VAL_ 56 SumTrq_DrvReqMod 8191 "SNA" ;
VAL_ 315 DriveMdstat 0 "Drive_Mode_Unavailable" 1 "Hybrid" 2 "Sport" 4 "ESave" 8 "Electric" 15 "SNA" ;
VAL_ 315 DrvMode_PopUpRqst 0 "TM0" 1 "TM1" 2 "TM2" 3 "TM3" 4 "TM4" 5 "TM5" 6 "TM6" 7 "TM7" 8 "TM8" 9 "TM9" 10 "TM10" 11 "TM11" 12 "TM12" 13 "TM13" 14 "TM14" 15 "SNA" ;
VAL_ 315 GrShiftIndication 0 "NONE" 1 "UP" 2 "DOWN" 3 "SNA" ;
VAL_ 315 HCPPopUpMessage12 0 "MaxRegen_Off" 1 "MaxRegen_ON" 2 "MaxRegen_Unavailable" 3 "Not_Defined" ;
VAL_ 315 MaxRegenTelltale 0 "Off" 1 "White" 2 "Green" 3 "Not_Defined" ;
VAL_ 796 Batt_CabinPriority1_Sts 0 "Battery_charging_on_priority" 1 "Cabin_conditioning_on_priority" ;
VAL_ 796 ChargeUntilFull1_Sts 0 "Charge_Until_Full_Not_selected" 1 "Charge_Until_Full" ;
VAL_ 796 Do_Not_Repeat1_Sts 0 "Repeat" 1 "Do_Not_Repeat" ;
VAL_ 796 End_Time_Hr1_Sts 31 "SNA" ;
VAL_ 796 End_Time_Min1_Sts 15 "SNA" ;
VAL_ 796 Schedule_Confirmed1 0 "DISABLE" 1 "ENABLE" ;
VAL_ 796 Schedule_Day1_Sts 0 "No_Selection" 1 "M" 2 "T" 3 "TM" 4 "W" 5 "WM" 6 "WT" 7 "WTM" 8 "Th" 9 "ThM" 10 "ThT" 11 "ThTM" 12 "ThW" 13 "ThWM" 14 "ThWT" 15 "ThWTM" 16 "F" 17 "FM" 18 "FT" 19 "FTM" 20 "FW" 21 "FWM" 22 "FWT" 23 "FWTM" 24 "FTh" 25 "FThM" 26 "FThT" 27 "FThTM" 28 "FThW" 29 "FThWM" 30 "FThWT" 31 "FThWTM" 32 "S" 33 "SM" 34 "ST" 35 "STM" 36 "SW" 37 "SWM" 38 "SWT" 39 "SWTM" 40 "STh" 41 "SThM" 42 "SThT" 43 "SThTM" 44 "SThW" 45 "SThWM" 46 "SThWT" 47 "SThWTM" 48 "SF" 49 "SFM" 50 "SFT" 51 "SFTM" 52 "SFW" 53 "SFWM" 54 "SFWT" 55 "SFWTM" 56 "SFTh" 57 "SFThM" 58 "SFThT" 59 "SFThTM" 60 "SFThW" 61 "SFThWM" 62 "SFThWT" 63 "SFThWTM" 64 "Sa" 65 "SaM" 66 "SaT" 67 "SaTM" 68 "SaW" 69 "SaWM" 70 "SaWT" 71 "SaWTM" 72 "SaTh" 73 "SaThM" 74 "SaThT" 75 "SaThTM" 76 "SaThW" 77 "SaThWM" 78 "SaThWT" 79 "SaThWTM" 80 "SaF" 81 "SaFM" 82 "SaFT" 83 "SaFTM" 84 "SaFW" 85 "SaFWM" 86 "SaFWT" 87 "SaFWTM" 88 "SaFTh" 89 "SaFThM" 90 "SaFThT" 91 "SaFThTM" 92 "SaFThW" 93 "SaFThWM" 94 "SaFThWT" 95 "SaFThWTM" 96 "SaS" 97 "SaSM" 98 "SaST" 99 "SaSTM" 100 "SaSW" 101 "SaSWM" 102 "SaSWT" 103 "SaSWTM" 104 "SaSTh" 105 "SaSThM" 106 "SaSThT" 107 "SaSThTM" 108 "SaSThW" 109 "SaSThWM" 110 "SaSThWT" 111 "SaSThWTM" 112 "SaSF" 113 "SaSFM" 114 "SaSFT" 115 "SaSFTM" 116 "SaSFW" 117 "SaSFWM" 118 "SaSFWT" 119 "SaSFWTM" 120 "SaSFTh" 121 "SaSFThM" 122 "SaSFThT" 123 "SaSFThTM" 124 "SaSFThW" 125 "SaSFThWM" 126 "SaSFThWT" 127 "SaSFThWTM" ;
VAL_ 796 Schedule_Type1_Sts 0 "No_Selection" 1 "Departure_Time" 2 "Charge_Interval" 3 "SNA" ;
VAL_ 796 Start_Time_Hr1_Sts 31 "SNA" ;
VAL_ 796 Start_Time_Min1_Sts 15 "SNA" ;
VAL_ 797 Batt_CabinPriority2_Sts 0 "Battery_charging_on_priority" 1 "Cabin_conditioning_on_priority" ;
VAL_ 797 ChargeUntilFull2_Sts 0 "Charge_Until_Full_Not_selected" 1 "Charge_Until_Full" ;
VAL_ 797 Do_Not_Repeat2_Sts 0 "Repeat" 1 "Do_Not_Repeat" ;
VAL_ 797 End_Time_Hr2_Sts 31 "SNA" ;
VAL_ 797 End_Time_Min2_Sts 15 "SNA" ;
VAL_ 797 Schedule_Confirmed2 0 "DISABLE" 1 "ENABLE" ;
VAL_ 797 Schedule_Day2_Sts 0 "No_Selection" 1 "M" 2 "T" 3 "TM" 4 "W" 5 "WM" 6 "WT" 7 "WTM" 8 "Th" 9 "ThM" 10 "ThT" 11 "ThTM" 12 "ThW" 13 "ThWM" 14 "ThWT" 15 "ThWTM" 16 "F" 17 "FM" 18 "FT" 19 "FTM" 20 "FW" 21 "FWM" 22 "FWT" 23 "FWTM" 24 "FTh" 25 "FThM" 26 "FThT" 27 "FThTM" 28 "FThW" 29 "FThWM" 30 "FThWT" 31 "FThWTM" 32 "S" 33 "SM" 34 "ST" 35 "STM" 36 "SW" 37 "SWM" 38 "SWT" 39 "SWTM" 40 "STh" 41 "SThM" 42 "SThT" 43 "SThTM" 44 "SThW" 45 "SThWM" 46 "SThWT" 47 "SThWTM" 48 "SF" 49 "SFM" 50 "SFT" 51 "SFTM" 52 "SFW" 53 "SFWM" 54 "SFWT" 55 "SFWTM" 56 "SFTh" 57 "SFThM" 58 "SFThT" 59 "SFThTM" 60 "SFThW" 61 "SFThWM" 62 "SFThWT" 63 "SFThWTM" 64 "Sa" 65 "SaM" 66 "SaT" 67 "SaTM" 68 "SaW" 69 "SaWM" 70 "SaWT" 71 "SaWTM" 72 "SaTh" 73 "SaThM" 74 "SaThT" 75 "SaThTM" 76 "SaThW" 77 "SaThWM" 78 "SaThWT" 79 "SaThWTM" 80 "SaF" 81 "SaFM" 82 "SaFT" 83 "SaFTM" 84 "SaFW" 85 "SaFWM" 86 "SaFWT" 87 "SaFWTM" 88 "SaFTh" 89 "SaFThM" 90 "SaFThT" 91 "SaFThTM" 92 "SaFThW" 93 "SaFThWM" 94 "SaFThWT" 95 "SaFThWTM" 96 "SaS" 97 "SaSM" 98 "SaST" 99 "SaSTM" 100 "SaSW" 101 "SaSWM" 102 "SaSWT" 103 "SaSWTM" 104 "SaSTh" 105 "SaSThM" 106 "SaSThT" 107 "SaSThTM" 108 "SaSThW" 109 "SaSThWM" 110 "SaSThWT" 111 "SaSThWTM" 112 "SaSF" 113 "SaSFM" 114 "SaSFT" 115 "SaSFTM" 116 "SaSFW" 117 "SaSFWM" 118 "SaSFWT" 119 "SaSFWTM" 120 "SaSFTh" 121 "SaSFThM" 122 "SaSFThT" 123 "SaSFThTM" 124 "SaSFThW" 125 "SaSFThWM" 126 "SaSFThWT" 127 "SaSFThWTM" ;
VAL_ 797 Schedule_Type2_Sts 0 "No_Selection" 1 "Departure_Time" 2 "Charge_Interval" 3 "SNA" ;
VAL_ 797 Start_Time_Hr2_Sts 31 "SNA" ;
VAL_ 797 Start_Time_Min2_Sts 15 "SNA" ;
VAL_ 798 Batt_CabinPriority3_Sts 0 "Battery_charging_on_priority" 1 "Cabin_conditioning_on_priority" ;
VAL_ 798 ChargeUntilFull3_Sts 0 "Charge_Until_Full_Not_selected" 1 "Charge_Until_Full" ;
VAL_ 798 Do_Not_Repeat3_Sts 0 "Repeat" 1 "Do_Not_Repeat" ;
VAL_ 798 End_Time_Hr3_Sts 31 "SNA" ;
VAL_ 798 End_Time_Min3_Sts 15 "SNA" ;
VAL_ 798 Schedule_Confirmed3 0 "DISABLE" 1 "ENABLE" ;
VAL_ 798 Schedule_Day3_Sts 0 "No_Selection" 1 "M" 2 "T" 3 "TM" 4 "W" 5 "WM" 6 "WT" 7 "WTM" 8 "Th" 9 "ThM" 10 "ThT" 11 "ThTM" 12 "ThW" 13 "ThWM" 14 "ThWT" 15 "ThWTM" 16 "F" 17 "FM" 18 "FT" 19 "FTM" 20 "FW" 21 "FWM" 22 "FWT" 23 "FWTM" 24 "FTh" 25 "FThM" 26 "FThT" 27 "FThTM" 28 "FThW" 29 "FThWM" 30 "FThWT" 31 "FThWTM" 32 "S" 33 "SM" 34 "ST" 35 "STM" 36 "SW" 37 "SWM" 38 "SWT" 39 "SWTM" 40 "STh" 41 "SThM" 42 "SThT" 43 "SThTM" 44 "SThW" 45 "SThWM" 46 "SThWT" 47 "SThWTM" 48 "SF" 49 "SFM" 50 "SFT" 51 "SFTM" 52 "SFW" 53 "SFWM" 54 "SFWT" 55 "SFWTM" 56 "SFTh" 57 "SFThM" 58 "SFThT" 59 "SFThTM" 60 "SFThW" 61 "SFThWM" 62 "SFThWT" 63 "SFThWTM" 64 "Sa" 65 "SaM" 66 "SaT" 67 "SaTM" 68 "SaW" 69 "SaWM" 70 "SaWT" 71 "SaWTM" 72 "SaTh" 73 "SaThM" 74 "SaThT" 75 "SaThTM" 76 "SaThW" 77 "SaThWM" 78 "SaThWT" 79 "SaThWTM" 80 "SaF" 81 "SaFM" 82 "SaFT" 83 "SaFTM" 84 "SaFW" 85 "SaFWM" 86 "SaFWT" 87 "SaFWTM" 88 "SaFTh" 89 "SaFThM" 90 "SaFThT" 91 "SaFThTM" 92 "SaFThW" 93 "SaFThWM" 94 "SaFThWT" 95 "SaFThWTM" 96 "SaS" 97 "SaSM" 98 "SaST" 99 "SaSTM" 100 "SaSW" 101 "SaSWM" 102 "SaSWT" 103 "SaSWTM" 104 "SaSTh" 105 "SaSThM" 106 "SaSThT" 107 "SaSThTM" 108 "SaSThW" 109 "SaSThWM" 110 "SaSThWT" 111 "SaSThWTM" 112 "SaSF" 113 "SaSFM" 114 "SaSFT" 115 "SaSFTM" 116 "SaSFW" 117 "SaSFWM" 118 "SaSFWT" 119 "SaSFWTM" 120 "SaSFTh" 121 "SaSFThM" 122 "SaSFThT" 123 "SaSFThTM" 124 "SaSFThW" 125 "SaSFThWM" 126 "SaSFThWT" 127 "SaSFThWTM" ;
VAL_ 798 Schedule_Type3_Sts 0 "No_Selection" 1 "Departure_Time" 2 "Charge_Interval" 3 "SNA" ;
VAL_ 798 Start_Time_Hr3_Sts 31 "SNA" ;
VAL_ 798 Start_Time_Min3_Sts 15 "SNA" ;
VAL_ 41 PropulsionMode 0 "Hybrid_Parallel" 1 "EV_Only" 2 "Hybrid_Series" 7 "SNA" ;
VAL_ 801 Batt_CabinPriority1 0 "Checkbox_Unselected" 1 "Checkbox_Selected" ;
VAL_ 801 ChargeUntilFull1 0 "Charge_Until_Full_Not_selected" 1 "Charge_Until_Full" ;
VAL_ 801 Do_Not_Repeat1 0 "Repeat" 1 "Do_Not_Repeat" ;
VAL_ 801 Enable_Schedule1 0 "Disable_schedule" 1 "Enable_schedule" ;
VAL_ 801 End_Time_Hr1 31 "SNA" ;
VAL_ 801 End_Time_Min1 15 "SNA" ;
VAL_ 801 Schedule_Day1 0 "No_Selection" 1 "M" 2 "T" 3 "TM" 4 "W" 5 "WM" 6 "WT" 7 "WTM" 8 "Th" 9 "ThM" 10 "ThT" 11 "ThTM" 12 "ThW" 13 "ThWM" 14 "ThWT" 15 "ThWTM" 16 "F" 17 "FM" 18 "FT" 19 "FTM" 20 "FW" 21 "FWM" 22 "FWT" 23 "FWTM" 24 "FTh" 25 "FThM" 26 "FThT" 27 "FThTM" 28 "FThW" 29 "FThWM" 30 "FThWT" 31 "FThWTM" 32 "S" 33 "SM" 34 "ST" 35 "STM" 36 "SW" 37 "SWM" 38 "SWT" 39 "SWTM" 40 "STh" 41 "SThM" 42 "SThT" 43 "SThTM" 44 "SThW" 45 "SThWM" 46 "SThWT" 47 "SThWTM" 48 "SF" 49 "SFM" 50 "SFT" 51 "SFTM" 52 "SFW" 53 "SFWM" 54 "SFWT" 55 "SFWTM" 56 "SFTh" 57 "SFThM" 58 "SFThT" 59 "SFThTM" 60 "SFThW" 61 "SFThWM" 62 "SFThWT" 63 "SFThWTM" 64 "Sa" 65 "SaM" 66 "SaT" 67 "SaTM" 68 "SaW" 69 "SaWM" 70 "SaWT" 71 "SaWTM" 72 "SaTh" 73 "SaThM" 74 "SaThT" 75 "SaThTM" 76 "SaThW" 77 "SaThWM" 78 "SaThWT" 79 "SaThWTM" 80 "SaF" 81 "SaFM" 82 "SaFT" 83 "SaFTM" 84 "SaFW" 85 "SaFWM" 86 "SaFWT" 87 "SaFWTM" 88 "SaFTh" 89 "SaFThM" 90 "SaFThT" 91 "SaFThTM" 92 "SaFThW" 93 "SaFThWM" 94 "SaFThWT" 95 "SaFThWTM" 96 "SaS" 97 "SaSM" 98 "SaST" 99 "SaSTM" 100 "SaSW" 101 "SaSWM" 102 "SaSWT" 103 "SaSWTM" 104 "SaSTh" 105 "SaSThM" 106 "SaSThT" 107 "SaSThTM" 108 "SaSThW" 109 "SaSThWM" 110 "SaSThWT" 111 "SaSThWTM" 112 "SaSF" 113 "SaSFM" 114 "SaSFT" 115 "SaSFTM" 116 "SaSFW" 117 "SaSFWM" 118 "SaSFWT" 119 "SaSFWTM" 120 "SaSFTh" 121 "SaSFThM" 122 "SaSFThT" 123 "SaSFThTM" 124 "SaSFThW" 125 "SaSFThWM" 126 "SaSFThWT" 127 "SaSFThWTM" ;
VAL_ 801 Schedule_Type1 0 "No_Selection" 1 "Departure_Time" 2 "Charge_Interval" 3 "SNA" ;
VAL_ 801 Start_Time_Hr1 31 "SNA" ;
VAL_ 801 Start_Time_Min1 15 "SNA" ;
VAL_ 801 Submit_Schedule1 0 "No_Change" 1 "Change_in_schedule" ;
VAL_ 802 Batt_CabinPriority2 0 "Checkbox_Unselected" 1 "Checkbox_Selected" ;
VAL_ 802 ChargeUntilFull2 0 "Charge_Until_Full_Not_selected" 1 "Charge_Until_Full" ;
VAL_ 802 Do_Not_Repeat2 0 "Repeat" 1 "Do_Not_Repeat" ;
VAL_ 802 Enable_Schedule2 0 "Disable_schedule" 1 "Enable_schedule" ;
VAL_ 802 End_Time_Hr2 31 "SNA" ;
VAL_ 802 End_Time_Min2 15 "SNA" ;
VAL_ 802 Schedule_Day2 0 "No_Selection" 1 "M" 2 "T" 3 "TM" 4 "W" 5 "WM" 6 "WT" 7 "WTM" 8 "Th" 9 "ThM" 10 "ThT" 11 "ThTM" 12 "ThW" 13 "ThWM" 14 "ThWT" 15 "ThWTM" 16 "F" 17 "FM" 18 "FT" 19 "FTM" 20 "FW" 21 "FWM" 22 "FWT" 23 "FWTM" 24 "FTh" 25 "FThM" 26 "FThT" 27 "FThTM" 28 "FThW" 29 "FThWM" 30 "FThWT" 31 "FThWTM" 32 "S" 33 "SM" 34 "ST" 35 "STM" 36 "SW" 37 "SWM" 38 "SWT" 39 "SWTM" 40 "STh" 41 "SThM" 42 "SThT" 43 "SThTM" 44 "SThW" 45 "SThWM" 46 "SThWT" 47 "SThWTM" 48 "SF" 49 "SFM" 50 "SFT" 51 "SFTM" 52 "SFW" 53 "SFWM" 54 "SFWT" 55 "SFWTM" 56 "SFTh" 57 "SFThM" 58 "SFThT" 59 "SFThTM" 60 "SFThW" 61 "SFThWM" 62 "SFThWT" 63 "SFThWTM" 64 "Sa" 65 "SaM" 66 "SaT" 67 "SaTM" 68 "SaW" 69 "SaWM" 70 "SaWT" 71 "SaWTM" 72 "SaTh" 73 "SaThM" 74 "SaThT" 75 "SaThTM" 76 "SaThW" 77 "SaThWM" 78 "SaThWT" 79 "SaThWTM" 80 "SaF" 81 "SaFM" 82 "SaFT" 83 "SaFTM" 84 "SaFW" 85 "SaFWM" 86 "SaFWT" 87 "SaFWTM" 88 "SaFTh" 89 "SaFThM" 90 "SaFThT" 91 "SaFThTM" 92 "SaFThW" 93 "SaFThWM" 94 "SaFThWT" 95 "SaFThWTM" 96 "SaS" 97 "SaSM" 98 "SaST" 99 "SaSTM" 100 "SaSW" 101 "SaSWM" 102 "SaSWT" 103 "SaSWTM" 104 "SaSTh" 105 "SaSThM" 106 "SaSThT" 107 "SaSThTM" 108 "SaSThW" 109 "SaSThWM" 110 "SaSThWT" 111 "SaSThWTM" 112 "SaSF" 113 "SaSFM" 114 "SaSFT" 115 "SaSFTM" 116 "SaSFW" 117 "SaSFWM" 118 "SaSFWT" 119 "SaSFWTM" 120 "SaSFTh" 121 "SaSFThM" 122 "SaSFThT" 123 "SaSFThTM" 124 "SaSFThW" 125 "SaSFThWM" 126 "SaSFThWT" 127 "SaSFThWTM" ;
VAL_ 802 Schedule_Type2 0 "No_Selection" 1 "Departure_Time" 2 "Charge_Interval" 3 "SNA" ;
VAL_ 802 Start_Time_Hr2 31 "SNA" ;
VAL_ 802 Start_Time_Min2 15 "SNA" ;
VAL_ 802 Submit_Schedule2 0 "No_Change" 1 "Change_in_schedule" ;
